VERSION "created by canmatrix"

NS_ :

BS_:

BU_: TCM iBooster HCU CIM SCM Right_Hand_Control Left_Hand_Control GPS VCM IC_2 XM GMRS Radio_CANtool Diagnostic_Tool_Digital_Wrench Information_System_Controller_1 STEERING_CONTROLLER VEHICLE_SECURITY RADIO_Hub ABS Battery_Management_Cntrl_2 Battery_Management_Cntrl_1 Auxiliary_Power_Unit_2 Auxiliary_Power_Unit_1 Electric_Propulsion_Cntrl_Unit_4 Electric_Propulsion_Cntrl_Unit_3 Electric_Propulsion_Cntrl_Unit_2 Electric_Propulsion_Cntrl_Unit_1 ECM IC

BO_ 2566740990 DM45: 22 Vector__XXX
 SG_ FlashRedStopLamp : 12|2@1+ (1,0) [0.0|3.0] "" Vector__XXX
 SG_ FlashProtectLamp : 8|2@1+ (1,0) [0.0|3.0] "" Vector__XXX
 SG_ FlashMalfuncIndicatorLamp : 14|2@1+ (1,0) [0.0|3.0] "" Vector__XXX
 SG_ FlashAmberWarningLamp : 10|2@1+ (1,0) [0.0|3.0] "" Vector__XXX
 SG_ MalfunctionIndicatorLampStatus : 6|2@1+ (1,0) [0.0|3.0] "" Vector__XXX
 SG_ AmberWarningLampStatus : 2|2@1+ (1,0) [0.0|3.0] "" Vector__XXX
 SG_ RedStopLampState : 4|2@1+ (1,0) [0.0|3.0] "" Vector__XXX
 SG_ ProtectLampStatus : 0|2@1+ (1,0) [0.0|3.0] "" Vector__XXX
 SG_ DTC5 : 144|32@1+ (1,0) [0.0|4294967295.0] "" Vector__XXX
 SG_ DTC4 : 112|32@1+ (1,0) [0.0|4294967295.0] "" Vector__XXX
 SG_ DTC3 : 80|32@1+ (1,0) [0.0|4294967295.0] "" Vector__XXX
 SG_ DTC2 : 48|32@1+ (1,0) [0.0|4294967295.0] "" Vector__XXX
 SG_ DTC1 : 16|32@1+ (1,0) [0.0|4294967295.0] "" Vector__XXX

BO_ 2566741246 DM44: 22 Vector__XXX
 SG_ FlashRedStopLamp : 12|2@1+ (1,0) [0.0|3.0] "" Vector__XXX
 SG_ FlashProtectLamp : 8|2@1+ (1,0) [0.0|3.0] "" Vector__XXX
 SG_ FlashMalfuncIndicatorLamp : 14|2@1+ (1,0) [0.0|3.0] "" Vector__XXX
 SG_ FlashAmberWarningLamp : 10|2@1+ (1,0) [0.0|3.0] "" Vector__XXX
 SG_ MalfunctionIndicatorLampStatus : 6|2@1+ (1,0) [0.0|3.0] "" Vector__XXX
 SG_ AmberWarningLampStatus : 2|2@1+ (1,0) [0.0|3.0] "" Vector__XXX
 SG_ RedStopLampState : 4|2@1+ (1,0) [0.0|3.0] "" Vector__XXX
 SG_ ProtectLampStatus : 0|2@1+ (1,0) [0.0|3.0] "" Vector__XXX
 SG_ DTC5 : 144|32@1+ (1,0) [0.0|4294967295.0] "" Vector__XXX
 SG_ DTC4 : 112|32@1+ (1,0) [0.0|4294967295.0] "" Vector__XXX
 SG_ DTC3 : 80|32@1+ (1,0) [0.0|4294967295.0] "" Vector__XXX
 SG_ DTC2 : 48|32@1+ (1,0) [0.0|4294967295.0] "" Vector__XXX
 SG_ DTC1 : 16|32@1+ (1,0) [0.0|4294967295.0] "" Vector__XXX

BO_ 2566741502 DM43: 22 Vector__XXX
 SG_ FlashRedStopLamp : 12|2@1+ (1,0) [0.0|3.0] "" Vector__XXX
 SG_ FlashProtectLamp : 8|2@1+ (1,0) [0.0|3.0] "" Vector__XXX
 SG_ FlashMalfuncIndicatorLamp : 14|2@1+ (1,0) [0.0|3.0] "" Vector__XXX
 SG_ FlashAmberWarningLamp : 10|2@1+ (1,0) [0.0|3.0] "" Vector__XXX
 SG_ MalfunctionIndicatorLampStatus : 6|2@1+ (1,0) [0.0|3.0] "" Vector__XXX
 SG_ AmberWarningLampStatus : 2|2@1+ (1,0) [0.0|3.0] "" Vector__XXX
 SG_ RedStopLampState : 4|2@1+ (1,0) [0.0|3.0] "" Vector__XXX
 SG_ ProtectLampStatus : 0|2@1+ (1,0) [0.0|3.0] "" Vector__XXX
 SG_ DTC5 : 144|32@1+ (1,0) [0.0|4294967295.0] "" Vector__XXX
 SG_ DTC4 : 112|32@1+ (1,0) [0.0|4294967295.0] "" Vector__XXX
 SG_ DTC3 : 80|32@1+ (1,0) [0.0|4294967295.0] "" Vector__XXX
 SG_ DTC2 : 48|32@1+ (1,0) [0.0|4294967295.0] "" Vector__XXX
 SG_ DTC1 : 16|32@1+ (1,0) [0.0|4294967295.0] "" Vector__XXX

BO_ 2566741758 DM42: 22 Vector__XXX
 SG_ FlashRedStopLamp : 12|2@1+ (1,0) [0.0|3.0] "" Vector__XXX
 SG_ FlashProtectLamp : 8|2@1+ (1,0) [0.0|3.0] "" Vector__XXX
 SG_ FlashMalfuncIndicatorLamp : 14|2@1+ (1,0) [0.0|3.0] "" Vector__XXX
 SG_ FlashAmberWarningLamp : 10|2@1+ (1,0) [0.0|3.0] "" Vector__XXX
 SG_ MalfunctionIndicatorLampStatus : 6|2@1+ (1,0) [0.0|3.0] "" Vector__XXX
 SG_ AmberWarningLampStatus : 2|2@1+ (1,0) [0.0|3.0] "" Vector__XXX
 SG_ RedStopLampState : 4|2@1+ (1,0) [0.0|3.0] "" Vector__XXX
 SG_ ProtectLampStatus : 0|2@1+ (1,0) [0.0|3.0] "" Vector__XXX
 SG_ DTC5 : 144|32@1+ (1,0) [0.0|4294967295.0] "" Vector__XXX
 SG_ DTC4 : 112|32@1+ (1,0) [0.0|4294967295.0] "" Vector__XXX
 SG_ DTC3 : 80|32@1+ (1,0) [0.0|4294967295.0] "" Vector__XXX
 SG_ DTC2 : 48|32@1+ (1,0) [0.0|4294967295.0] "" Vector__XXX
 SG_ DTC1 : 16|32@1+ (1,0) [0.0|4294967295.0] "" Vector__XXX

BO_ 2566742014 DM41: 22 Vector__XXX
 SG_ FlashRedStopLamp : 12|2@1+ (1,0) [0.0|3.0] "" Vector__XXX
 SG_ FlashProtectLamp : 8|2@1+ (1,0) [0.0|3.0] "" Vector__XXX
 SG_ FlashMalfuncIndicatorLamp : 14|2@1+ (1,0) [0.0|3.0] "" Vector__XXX
 SG_ FlashAmberWarningLamp : 10|2@1+ (1,0) [0.0|3.0] "" Vector__XXX
 SG_ MalfunctionIndicatorLampStatus : 6|2@1+ (1,0) [0.0|3.0] "" Vector__XXX
 SG_ AmberWarningLampStatus : 2|2@1+ (1,0) [0.0|3.0] "" Vector__XXX
 SG_ RedStopLampState : 4|2@1+ (1,0) [0.0|3.0] "" Vector__XXX
 SG_ ProtectLampStatus : 0|2@1+ (1,0) [0.0|3.0] "" Vector__XXX
 SG_ DTC5 : 144|32@1+ (1,0) [0.0|4294967295.0] "" Vector__XXX
 SG_ DTC4 : 112|32@1+ (1,0) [0.0|4294967295.0] "" Vector__XXX
 SG_ DTC3 : 80|32@1+ (1,0) [0.0|4294967295.0] "" Vector__XXX
 SG_ DTC2 : 48|32@1+ (1,0) [0.0|4294967295.0] "" Vector__XXX
 SG_ DTC1 : 16|32@1+ (1,0) [0.0|4294967295.0] "" Vector__XXX

BO_ 2560622334 DM35_40704: 22 Vector__XXX
 SG_ FlashRedStopLamp_3039 : 12|2@1+ (1,0) [0.0|3.0] "" Vector__XXX
 SG_ FlashProtectLamp_3041 : 8|2@1+ (1,0) [0.0|3.0] "" Vector__XXX
 SG_ FlashMalfuncIndicatorLamp_3038 : 14|2@1+ (1,0) [0.0|3.0] "" Vector__XXX
 SG_ FlashAmberWarningLamp_3040 : 10|2@1+ (1,0) [0.0|3.0] "" Vector__XXX
 SG_ MILStatus_1213 : 6|2@1+ (1,0) [0.0|3.0] "" Vector__XXX
 SG_ AmberWarningLampStatus_624 : 2|2@1+ (1,0) [0.0|3.0] "" Vector__XXX
 SG_ RedStopLampState_623 : 4|2@1+ (1,0) [0.0|3.0] "" Vector__XXX
 SG_ ProtectLampStatus_987 : 0|2@1+ (1,0) [0.0|3.0] "" Vector__XXX
 SG_ DTC5 : 144|32@1+ (1,0) [0.0|4294967295.0] "" Vector__XXX
 SG_ DTC4 : 112|32@1+ (1,0) [0.0|4294967295.0] "" Vector__XXX
 SG_ DTC3 : 80|32@1+ (1,0) [0.0|4294967295.0] "" Vector__XXX
 SG_ DTC2 : 48|32@1+ (1,0) [0.0|4294967295.0] "" Vector__XXX
 SG_ DTC1 : 16|32@1+ (1,0) [0.0|4294967295.0] "" Vector__XXX

BO_ 2566744062 ZNVW: 8 Vector__XXX
 SG_ ZeroNetVehicleWeightChange : 0|2@1+ (1,0) [0.0|3.0] "" Vector__XXX

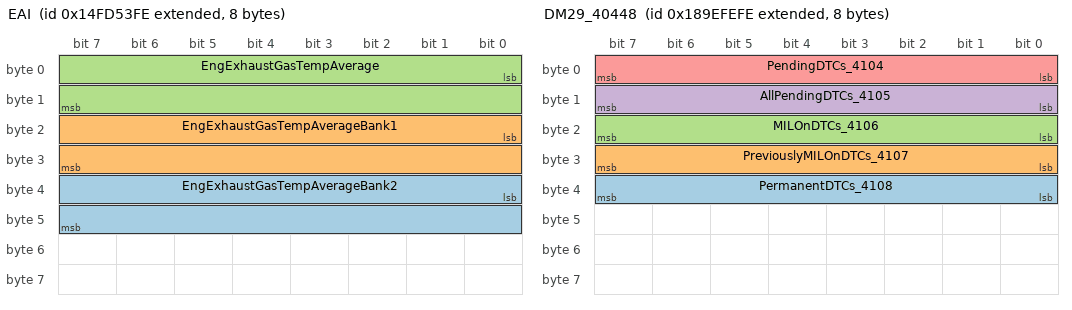
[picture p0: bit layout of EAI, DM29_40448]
BO_ 2499630078 EAI: 8 Vector__XXX
 SG_ EngExhaustGasTempAverageBank2 : 32|16@1+ (0.03125,-273) [-273.0|1734.96875] "°C" Vector__XXX
 SG_ EngExhaustGasTempAverageBank1 : 16|16@1+ (0.03125,-273) [-273.0|1734.96875] "°C" Vector__XXX
 SG_ EngExhaustGasTempAverage : 0|16@1+ (0.03125,-273) [-273.0|1734.96875] "°C" Vector__XXX

BO_ 2560556798 DM29_40448: 8 Vector__XXX
 SG_ PermanentDTCs_4108 : 32|8@1+ (1,0) [0.0|255.0] "" Vector__XXX
 SG_ PreviouslyMILOnDTCs_4107 : 24|8@1+ (1,0) [0.0|255.0] "" Vector__XXX
 SG_ MILOnDTCs_4106 : 16|8@1+ (1,0) [0.0|255.0] "" Vector__XXX
 SG_ AllPendingDTCs_4105 : 8|8@1+ (1,0) [0.0|255.0] "" Vector__XXX
 SG_ PendingDTCs_4104 : 0|8@1+ (1,0) [0.0|255.0] "" Vector__XXX

BO_ 2566750462 DM28: 22 Vector__XXX
 SG_ FlashRedStopLamp : 12|2@1+ (1,0) [0.0|3.0] "" Vector__XXX
 SG_ FlashProtectLamp : 8|2@1+ (1,0) [0.0|3.0] "" Vector__XXX
 SG_ FlashMalfuncIndicatorLamp : 14|2@1+ (1,0) [0.0|3.0] "" Vector__XXX
 SG_ FlashAmberWarningLamp : 10|2@1+ (1,0) [0.0|3.0] "" Vector__XXX
 SG_ MalfunctionIndicatorLampStatus : 6|2@1+ (1,0) [0.0|3.0] "" Vector__XXX
 SG_ AmberWarningLampStatus : 2|2@1+ (1,0) [0.0|3.0] "" Vector__XXX
 SG_ RedStopLampState : 4|2@1+ (1,0) [0.0|3.0] "" Vector__XXX
 SG_ ProtectLampStatus : 0|2@1+ (1,0) [0.0|3.0] "" Vector__XXX
 SG_ DTC5 : 144|32@1+ (1,0) [0.0|4294967295.0] "" Vector__XXX
 SG_ DTC4 : 112|32@1+ (1,0) [0.0|4294967295.0] "" Vector__XXX
 SG_ DTC3 : 80|32@1+ (1,0) [0.0|4294967295.0] "" Vector__XXX
 SG_ DTC2 : 48|32@1+ (1,0) [0.0|4294967295.0] "" Vector__XXX
 SG_ DTC1 : 16|32@1+ (1,0) [0.0|4294967295.0] "" Vector__XXX

BO_ 2566750974 DM27: 22 Vector__XXX
 SG_ FlashRedStopLamp : 12|2@1+ (1,0) [0.0|3.0] "" Vector__XXX
 SG_ FlashProtectLamp : 8|2@1+ (1,0) [0.0|3.0] "" Vector__XXX
 SG_ FlashMalfuncIndicatorLamp : 14|2@1+ (1,0) [0.0|3.0] "" Vector__XXX
 SG_ FlashAmberWarningLamp : 10|2@1+ (1,0) [0.0|3.0] "" Vector__XXX
 SG_ MalfunctionIndicatorLampStatus : 6|2@1+ (1,0) [0.0|3.0] "" Vector__XXX
 SG_ AmberWarningLampStatus : 2|2@1+ (1,0) [0.0|3.0] "" Vector__XXX
 SG_ RedStopLampState : 4|2@1+ (1,0) [0.0|3.0] "" Vector__XXX
 SG_ ProtectLampStatus : 0|2@1+ (1,0) [0.0|3.0] "" Vector__XXX
 SG_ DTC5 : 144|32@1+ (1,0) [0.0|4294967295.0] "" Vector__XXX
 SG_ DTC4 : 112|32@1+ (1,0) [0.0|4294967295.0] "" Vector__XXX
 SG_ DTC3 : 80|32@1+ (1,0) [0.0|4294967295.0] "" Vector__XXX
 SG_ DTC2 : 48|32@1+ (1,0) [0.0|4294967295.0] "" Vector__XXX
 SG_ DTC1 : 16|32@1+ (1,0) [0.0|4294967295.0] "" Vector__XXX

BO_ 2566754558 AETC: 61 Vector__XXX
 SG_ AETCTorqueValue14 : 472|16@1+ (1,0) [0.0|65535.0] "Nm" Vector__XXX
 SG_ AETCTorqueValue13 : 440|16@1+ (1,0) [0.0|65535.0] "Nm" Vector__XXX
 SG_ AETCTorqueValue12 : 408|16@1+ (1,0) [0.0|65535.0] "Nm" Vector__XXX
 SG_ AETCTorqueValue11 : 376|16@1+ (1,0) [0.0|65535.0] "Nm" Vector__XXX
 SG_ AETCTorqueValue10 : 344|16@1+ (1,0) [0.0|65535.0] "Nm" Vector__XXX
 SG_ AETCTorqueValue09 : 312|16@1+ (1,0) [0.0|65535.0] "Nm" Vector__XXX
 SG_ AETCTorqueValue08 : 280|16@1+ (1,0) [0.0|65535.0] "Nm" Vector__XXX
 SG_ AETCTorqueValue07 : 248|16@1+ (1,0) [0.0|65535.0] "Nm" Vector__XXX
 SG_ AETCTorqueValue06 : 216|16@1+ (1,0) [0.0|65535.0] "Nm" Vector__XXX
 SG_ AETCTorqueValue05 : 184|16@1+ (1,0) [0.0|65535.0] "Nm" Vector__XXX
 SG_ AETCTorqueValue04 : 152|16@1+ (1,0) [0.0|65535.0] "Nm" Vector__XXX
 SG_ AETCTorqueValue03 : 120|16@1+ (1,0) [0.0|65535.0] "Nm" Vector__XXX
 SG_ AETCTorqueValue02 : 88|16@1+ (1,0) [0.0|65535.0] "Nm" Vector__XXX
 SG_ AETCTorqueValue01 : 56|16@1+ (1,0) [0.0|65535.0] "Nm" Vector__XXX
 SG_ AETCSpeedValue14 : 456|16@1+ (0.125,0) [0.0|8191.875] "rpm" Vector__XXX
 SG_ AETCSpeedValue13 : 424|16@1+ (0.125,0) [0.0|8191.875] "rpm" Vector__XXX
 SG_ AETCSpeedValue12 : 392|16@1+ (0.125,0) [0.0|8191.875] "rpm" Vector__XXX
 SG_ AETCSpeedValue11 : 360|16@1+ (0.125,0) [0.0|8191.875] "rpm" Vector__XXX
 SG_ AETCSpeedValue10 : 328|16@1+ (0.125,0) [0.0|8191.875] "rpm" Vector__XXX
 SG_ AETCSpeedValue09 : 296|16@1+ (0.125,0) [0.0|8191.875] "rpm" Vector__XXX
 SG_ AETCSpeedValue08 : 264|16@1+ (0.125,0) [0.0|8191.875] "rpm" Vector__XXX
 SG_ AETCSpeedValue07 : 232|16@1+ (0.125,0) [0.0|8191.875] "rpm" Vector__XXX
 SG_ AETCSpeedValue06 : 200|16@1+ (0.125,0) [0.0|8191.875] "rpm" Vector__XXX
 SG_ AETCSpeedValue05 : 168|16@1+ (0.125,0) [0.0|8191.875] "rpm" Vector__XXX
 SG_ AETCSpeedValue04 : 136|16@1+ (0.125,0) [0.0|8191.875] "rpm" Vector__XXX
 SG_ AETCSpeedValue03 : 104|16@1+ (0.125,0) [0.0|8191.875] "rpm" Vector__XXX
 SG_ AETCSpeedValue02 : 72|16@1+ (0.125,0) [0.0|8191.875] "rpm" Vector__XXX
 SG_ AETCSpeedValue01 : 40|16@1+ (0.125,0) [0.0|8191.875] "rpm" Vector__XXX
 SG_ AETCTorqueValue00 : 24|16@1+ (1,0) [0.0|65535.0] "Nm" Vector__XXX
 SG_ AETCSpeedValue00 : 8|16@1+ (0.125,0) [0.0|8191.875] "rpm" Vector__XXX
 SG_ NumberOfAETCDataPoints : 4|4@1+ (1,0) [5.0|15.0] "" Vector__XXX
 SG_ AETCDataCollectionStandard : 0|4@1+ (1,0) [0.0|15.0] "" Vector__XXX

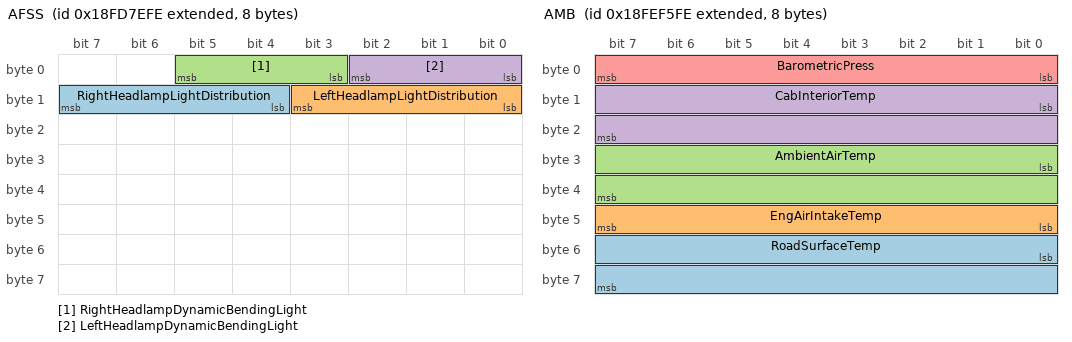
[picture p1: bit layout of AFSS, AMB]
BO_ 2566749950 AFSS: 8 Vector__XXX
 SG_ RightHeadlampLightDistribution : 12|4@1+ (1,0) [0.0|15.0] "" Vector__XXX
 SG_ LeftHeadlampLightDistribution : 8|4@1+ (1,0) [0.0|15.0] "" Vector__XXX
 SG_ RightHeadlampDynamicBendingLight : 3|3@1+ (1,0) [0.0|7.0] "" Vector__XXX
 SG_ LeftHeadlampDynamicBendingLight : 0|3@1+ (1,0) [0.0|7.0] "" Vector__XXX

BO_ 2566838782 AUXIO1: 8 Vector__XXX
 SG_ AuxI_OChannel2 : 48|16@1+ (1,0) [0.0|64255.0] "" Vector__XXX
 SG_ AuxI_OChannel1 : 32|16@1+ (1,0) [0.0|64255.0] "" Vector__XXX
 SG_ AuxI_O13 : 30|2@1+ (1,0) [0.0|3.0] "" Vector__XXX
 SG_ AuxI_O14 : 28|2@1+ (1,0) [0.0|3.0] "" Vector__XXX
 SG_ AuxI_O15 : 26|2@1+ (1,0) [0.0|3.0] "" Vector__XXX
 SG_ AuxI_O16 : 24|2@1+ (1,0) [0.0|3.0] "" Vector__XXX
 SG_ AuxI_O09 : 22|2@1+ (1,0) [0.0|3.0] "" Vector__XXX
 SG_ AuxI_O10 : 20|2@1+ (1,0) [0.0|3.0] "" Vector__XXX
 SG_ AuxI_O11 : 18|2@1+ (1,0) [0.0|3.0] "" Vector__XXX
 SG_ AuxI_O12 : 16|2@1+ (1,0) [0.0|3.0] "" Vector__XXX
 SG_ AuxI_O05 : 14|2@1+ (1,0) [0.0|3.0] "" Vector__XXX
 SG_ AuxI_O06 : 12|2@1+ (1,0) [0.0|3.0] "" Vector__XXX
 SG_ AuxI_O07 : 10|2@1+ (1,0) [0.0|3.0] "" Vector__XXX
 SG_ AuxI_O08 : 8|2@1+ (1,0) [0.0|3.0] "" Vector__XXX
 SG_ AuxI_O01 : 6|2@1+ (1,0) [0.0|3.0] "" Vector__XXX
 SG_ AuxI_O02 : 4|2@1+ (1,0) [0.0|3.0] "" Vector__XXX
 SG_ AuxI_O03 : 2|2@1+ (1,0) [0.0|3.0] "" Vector__XXX
 SG_ AuxI_O04 : 0|2@1+ (1,0) [0.0|3.0] "" Vector__XXX

BO_ 2561146622 AUXIO2_42752: 8 Vector__XXX
 SG_ AuxI_O45_3868 : 62|2@1+ (1,0) [0.0|3.0] "" Vector__XXX
 SG_ AuxI_O46_3869 : 60|2@1+ (1,0) [0.0|3.0] "" Vector__XXX
 SG_ AuxI_O47_3870 : 58|2@1+ (1,0) [0.0|3.0] "" Vector__XXX
 SG_ AuxI_O48_3871 : 56|2@1+ (1,0) [0.0|3.0] "" Vector__XXX
 SG_ AuxI_O41_3864 : 54|2@1+ (1,0) [0.0|3.0] "" Vector__XXX
 SG_ AuxI_O42_3865 : 52|2@1+ (1,0) [0.0|3.0] "" Vector__XXX
 SG_ AuxI_O43_3866 : 50|2@1+ (1,0) [0.0|3.0] "" Vector__XXX
 SG_ AuxI_O44_3867 : 48|2@1+ (1,0) [0.0|3.0] "" Vector__XXX
 SG_ AuxI_O37_3860 : 46|2@1+ (1,0) [0.0|3.0] "" Vector__XXX
 SG_ AuxI_O38_3861 : 44|2@1+ (1,0) [0.0|3.0] "" Vector__XXX
 SG_ AuxI_O39_3862 : 42|2@1+ (1,0) [0.0|3.0] "" Vector__XXX
 SG_ AuxI_O40_3863 : 40|2@1+ (1,0) [0.0|3.0] "" Vector__XXX
 SG_ AuxI_O33_3856 : 38|2@1+ (1,0) [0.0|3.0] "" Vector__XXX
 SG_ AuxI_O34_3857 : 36|2@1+ (1,0) [0.0|3.0] "" Vector__XXX
 SG_ AuxI_O35_3858 : 34|2@1+ (1,0) [0.0|3.0] "" Vector__XXX
 SG_ AuxI_O36_3859 : 32|2@1+ (1,0) [0.0|3.0] "" Vector__XXX
 SG_ AuxI_O29_3852 : 30|2@1+ (1,0) [0.0|3.0] "" Vector__XXX
 SG_ AuxI_O30_3853 : 28|2@1+ (1,0) [0.0|3.0] "" Vector__XXX
 SG_ AuxI_O31_3854 : 26|2@1+ (1,0) [0.0|3.0] "" Vector__XXX
 SG_ AuxI_O32_3855 : 24|2@1+ (1,0) [0.0|3.0] "" Vector__XXX
 SG_ AuxI_O25_3848 : 22|2@1+ (1,0) [0.0|3.0] "" Vector__XXX
 SG_ AuxI_O26_3849 : 20|2@1+ (1,0) [0.0|3.0] "" Vector__XXX
 SG_ AuxI_O27_3850 : 18|2@1+ (1,0) [0.0|3.0] "" Vector__XXX
 SG_ AuxI_O28_3851 : 16|2@1+ (1,0) [0.0|3.0] "" Vector__XXX
 SG_ AuxI_O21_3844 : 14|2@1+ (1,0) [0.0|3.0] "" Vector__XXX
 SG_ AuxI_O22_3845 : 12|2@1+ (1,0) [0.0|3.0] "" Vector__XXX
 SG_ AuxI_O23_3846 : 10|2@1+ (1,0) [0.0|3.0] "" Vector__XXX
 SG_ AuxI_O24_3847 : 8|2@1+ (1,0) [0.0|3.0] "" Vector__XXX
 SG_ AuxI_O17_3840 : 6|2@1+ (1,0) [0.0|3.0] "" Vector__XXX
 SG_ AuxI_O18_3841 : 4|2@1+ (1,0) [0.0|3.0] "" Vector__XXX
 SG_ AuxI_O19_3842 : 2|2@1+ (1,0) [0.0|3.0] "" Vector__XXX
 SG_ AuxI_O20_3843 : 0|2@1+ (1,0) [0.0|3.0] "" Vector__XXX

BO_ 2561081086 AUXIO3_42496: 8 Vector__XXX
 SG_ AuxI_O77_3900 : 62|2@1+ (1,0) [0.0|3.0] "" Vector__XXX
 SG_ AuxI_O78_3901 : 60|2@1+ (1,0) [0.0|3.0] "" Vector__XXX
 SG_ AuxI_O79_3902 : 58|2@1+ (1,0) [0.0|3.0] "" Vector__XXX
 SG_ AuxI_O80_3903 : 56|2@1+ (1,0) [0.0|3.0] "" Vector__XXX
 SG_ AuxI_O73_3896 : 54|2@1+ (1,0) [0.0|3.0] "" Vector__XXX
 SG_ AuxI_O74_3897 : 52|2@1+ (1,0) [0.0|3.0] "" Vector__XXX
 SG_ AuxI_O75_3898 : 50|2@1+ (1,0) [0.0|3.0] "" Vector__XXX
 SG_ AuxI_O76_3899 : 48|2@1+ (1,0) [0.0|3.0] "" Vector__XXX
 SG_ AuxI_O69_3892 : 46|2@1+ (1,0) [0.0|3.0] "" Vector__XXX
 SG_ AuxI_O70_3893 : 44|2@1+ (1,0) [0.0|3.0] "" Vector__XXX
 SG_ AuxI_O71_3894 : 42|2@1+ (1,0) [0.0|3.0] "" Vector__XXX
 SG_ AuxI_O72_3895 : 40|2@1+ (1,0) [0.0|3.0] "" Vector__XXX
 SG_ AuxI_O65_3888 : 38|2@1+ (1,0) [0.0|3.0] "" Vector__XXX
 SG_ AuxI_O66_3889 : 36|2@1+ (1,0) [0.0|3.0] "" Vector__XXX
 SG_ AuxI_O67_3890 : 34|2@1+ (1,0) [0.0|3.0] "" Vector__XXX
 SG_ AuxI_O68_3891 : 32|2@1+ (1,0) [0.0|3.0] "" Vector__XXX
 SG_ AuxI_O61_3884 : 30|2@1+ (1,0) [0.0|3.0] "" Vector__XXX
 SG_ AuxI_O62_3885 : 28|2@1+ (1,0) [0.0|3.0] "" Vector__XXX
 SG_ AuxI_O63_3886 : 26|2@1+ (1,0) [0.0|3.0] "" Vector__XXX
 SG_ AuxI_O64_3887 : 24|2@1+ (1,0) [0.0|3.0] "" Vector__XXX
 SG_ AuxI_O57_3880 : 22|2@1+ (1,0) [0.0|3.0] "" Vector__XXX
 SG_ AuxI_O58_3881 : 20|2@1+ (1,0) [0.0|3.0] "" Vector__XXX
 SG_ AuxI_O59_3882 : 18|2@1+ (1,0) [0.0|3.0] "" Vector__XXX
 SG_ AuxI_O60_3883 : 16|2@1+ (1,0) [0.0|3.0] "" Vector__XXX
 SG_ AuxI_O53_3876 : 14|2@1+ (1,0) [0.0|3.0] "" Vector__XXX
 SG_ AuxI_O54_3877 : 12|2@1+ (1,0) [0.0|3.0] "" Vector__XXX
 SG_ AuxI_O55_3878 : 10|2@1+ (1,0) [0.0|3.0] "" Vector__XXX
 SG_ AuxI_O56_3879 : 8|2@1+ (1,0) [0.0|3.0] "" Vector__XXX
 SG_ AuxI_O49_3872 : 6|2@1+ (1,0) [0.0|3.0] "" Vector__XXX
 SG_ AuxI_O50_3873 : 4|2@1+ (1,0) [0.0|3.0] "" Vector__XXX
 SG_ AuxI_O51_3874 : 2|2@1+ (1,0) [0.0|3.0] "" Vector__XXX
 SG_ AuxI_O52_3875 : 0|2@1+ (1,0) [0.0|3.0] "" Vector__XXX

BO_ 2561015550 AUXIO4_42240: 8 Vector__XXX
 SG_ AuxI_O109_3932 : 62|2@1+ (1,0) [0.0|3.0] "" Vector__XXX
 SG_ AuxI_O110_3933 : 60|2@1+ (1,0) [0.0|3.0] "" Vector__XXX
 SG_ AuxI_O111_3934 : 58|2@1+ (1,0) [0.0|3.0] "" Vector__XXX
 SG_ AuxI_O112_3935 : 56|2@1+ (1,0) [0.0|3.0] "" Vector__XXX
 SG_ AuxI_O105_3928 : 54|2@1+ (1,0) [0.0|3.0] "" Vector__XXX
 SG_ AuxI_O106_3929 : 52|2@1+ (1,0) [0.0|3.0] "" Vector__XXX
 SG_ AuxI_O107_3930 : 50|2@1+ (1,0) [0.0|3.0] "" Vector__XXX
 SG_ AuxI_O108_3931 : 48|2@1+ (1,0) [0.0|3.0] "" Vector__XXX
 SG_ AuxI_O101_3924 : 46|2@1+ (1,0) [0.0|3.0] "" Vector__XXX
 SG_ AuxI_O102_3925 : 44|2@1+ (1,0) [0.0|3.0] "" Vector__XXX
 SG_ AuxI_O103_3926 : 42|2@1+ (1,0) [0.0|3.0] "" Vector__XXX
 SG_ AuxI_O104_3927 : 40|2@1+ (1,0) [0.0|3.0] "" Vector__XXX
 SG_ AuxI_O97_3920 : 38|2@1+ (1,0) [0.0|3.0] "" Vector__XXX
 SG_ AuxI_O98_3921 : 36|2@1+ (1,0) [0.0|3.0] "" Vector__XXX
 SG_ AuxI_O99_3922 : 34|2@1+ (1,0) [0.0|3.0] "" Vector__XXX
 SG_ AuxI_O100_3923 : 32|2@1+ (1,0) [0.0|3.0] "" Vector__XXX
 SG_ AuxI_O93_3916 : 30|2@1+ (1,0) [0.0|3.0] "" Vector__XXX
 SG_ AuxI_O94_3917 : 28|2@1+ (1,0) [0.0|3.0] "" Vector__XXX
 SG_ AuxI_O95_3918 : 26|2@1+ (1,0) [0.0|3.0] "" Vector__XXX
 SG_ AuxI_O96_3919 : 24|2@1+ (1,0) [0.0|3.0] "" Vector__XXX
 SG_ AuxI_O89_3912 : 22|2@1+ (1,0) [0.0|3.0] "" Vector__XXX
 SG_ AuxI_O90_3913 : 20|2@1+ (1,0) [0.0|3.0] "" Vector__XXX
 SG_ AuxI_O91_3914 : 18|2@1+ (1,0) [0.0|3.0] "" Vector__XXX
 SG_ AuxI_O92_3915 : 16|2@1+ (1,0) [0.0|3.0] "" Vector__XXX
 SG_ AuxI_O85_3908 : 14|2@1+ (1,0) [0.0|3.0] "" Vector__XXX
 SG_ AuxI_O86_3909 : 12|2@1+ (1,0) [0.0|3.0] "" Vector__XXX
 SG_ AuxI_O87_3910 : 10|2@1+ (1,0) [0.0|3.0] "" Vector__XXX
 SG_ AuxI_O88_3911 : 8|2@1+ (1,0) [0.0|3.0] "" Vector__XXX
 SG_ AuxI_O81_3904 : 6|2@1+ (1,0) [0.0|3.0] "" Vector__XXX
 SG_ AuxI_O82_3905 : 4|2@1+ (1,0) [0.0|3.0] "" Vector__XXX
 SG_ AuxI_O83_3906 : 2|2@1+ (1,0) [0.0|3.0] "" Vector__XXX
 SG_ AuxI_O84_3907 : 0|2@1+ (1,0) [0.0|3.0] "" Vector__XXX

BO_ 2566746622 BSA: 8 Vector__XXX
 SG_ TrailerBrakeStrokeAxle5Right : 57|3@1+ (1,0) [0.0|7.0] "" Vector__XXX
 SG_ TrailerBrakeStrokeAxle5Left : 54|3@1+ (1,0) [0.0|7.0] "" Vector__XXX
 SG_ TrailerBrakeStrokeAxle4Right : 51|3@1+ (1,0) [0.0|7.0] "" Vector__XXX
 SG_ TrailerBrakeStrokeAxle4Left : 48|3@1+ (1,0) [0.0|7.0] "" Vector__XXX
 SG_ TrailerBrakeStrokeAxle3Right : 45|3@1+ (1,0) [0.0|7.0] "" Vector__XXX
 SG_ TrailerBrakeStrokeAxle3Left : 42|3@1+ (1,0) [0.0|7.0] "" Vector__XXX
 SG_ TrailerBrakeStrokeAxle2Right : 39|3@1+ (1,0) [0.0|7.0] "" Vector__XXX
 SG_ TrailerBrakeStrokeAxle2Left : 36|3@1+ (1,0) [0.0|7.0] "" Vector__XXX
 SG_ TrailerBrakeStrokeAxle1Right : 33|3@1+ (1,0) [0.0|7.0] "" Vector__XXX
 SG_ TrailerBrakeStrokeAxle1Left : 30|3@1+ (1,0) [0.0|7.0] "" Vector__XXX
 SG_ TractorBrakeStrokeAxle5Right : 27|3@1+ (1,0) [0.0|7.0] "" Vector__XXX
 SG_ TractorBrakeStrokeAxle5Left : 24|3@1+ (1,0) [0.0|7.0] "" Vector__XXX
 SG_ TractorBrakeStrokeAxle4Right : 21|3@1+ (1,0) [0.0|7.0] "" Vector__XXX
 SG_ TractorBrakeStrokeAxle4Left : 18|3@1+ (1,0) [0.0|7.0] "" Vector__XXX
 SG_ TractorBrakeStrokeAxle3Right : 15|3@1+ (1,0) [0.0|7.0] "" Vector__XXX
 SG_ TractorBrakeStrokeAxle3Left : 12|3@1+ (1,0) [0.0|7.0] "" Vector__XXX
 SG_ TractorBrakeStrokeAxle2Right : 9|3@1+ (1,0) [0.0|7.0] "" Vector__XXX
 SG_ TractorBrakeStrokeAxle2Left : 6|3@1+ (1,0) [0.0|7.0] "" Vector__XXX
 SG_ TractorBrakeStrokeAxle1Right : 3|3@1+ (1,0) [0.0|7.0] "" Vector__XXX
 SG_ TractorBrakeStrokeAxle1Left : 0|3@1+ (1,0) [0.0|7.0] "" Vector__XXX

BO_ 2566845950 AMB: 8 Vector__XXX
 SG_ RoadSurfaceTemp : 48|16@1+ (0.03125,-273) [-273.0|1734.96875] "°C" Vector__XXX
 SG_ EngAirIntakeTemp : 40|8@1+ (1,-40) [-40.0|210.0] "°C" Vector__XXX
 SG_ AmbientAirTemp : 24|16@1+ (0.03125,-273) [-273.0|1734.96875] "°C" Vector__XXX
 SG_ CabInteriorTemp : 8|16@1+ (0.03125,-273) [-273.0|1734.96875] "°C" Vector__XXX
 SG_ BarometricPress : 0|8@1+ (0.5,0) [0.0|125.0] "kPa" Vector__XXX

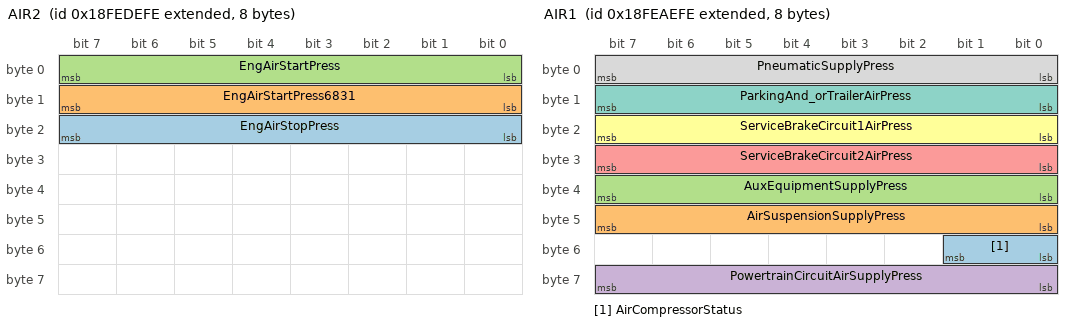
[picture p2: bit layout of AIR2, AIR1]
BO_ 2566840062 AIR2: 8 Vector__XXX
 SG_ EngAirStopPress : 16|8@1+ (4,0) [0.0|1000.0] "kPa" Vector__XXX
 SG_ EngAirStartPress6831 : 8|8@1+ (16,0) [0.0|4000.0] "kPa" Vector__XXX
 SG_ EngAirStartPress : 0|8@1+ (4,0) [0.0|1000.0] "kPa" Vector__XXX

BO_ 2566827774 AIR1: 8 Vector__XXX
 SG_ AirCompressorStatus : 48|2@1+ (1,0) [0.0|3.0] "" Vector__XXX
 SG_ AirSuspensionSupplyPress : 40|8@1+ (8,0) [0.0|2000.0] "kPa" Vector__XXX
 SG_ AuxEquipmentSupplyPress : 32|8@1+ (8,0) [0.0|2000.0] "kPa" Vector__XXX
 SG_ PowertrainCircuitAirSupplyPress : 56|8@1+ (8,0) [0.0|2000.0] "kPa" Vector__XXX
 SG_ ServiceBrakeCircuit2AirPress : 24|8@1+ (8,0) [0.0|2000.0] "kPa" Vector__XXX
 SG_ ServiceBrakeCircuit1AirPress : 16|8@1+ (8,0) [0.0|2000.0] "kPa" Vector__XXX
 SG_ ParkingAnd_orTrailerAirPress : 8|8@1+ (8,0) [0.0|2000.0] "kPa" Vector__XXX
 SG_ PneumaticSupplyPress : 0|8@1+ (8,0) [0.0|2000.0] "kPa" Vector__XXX

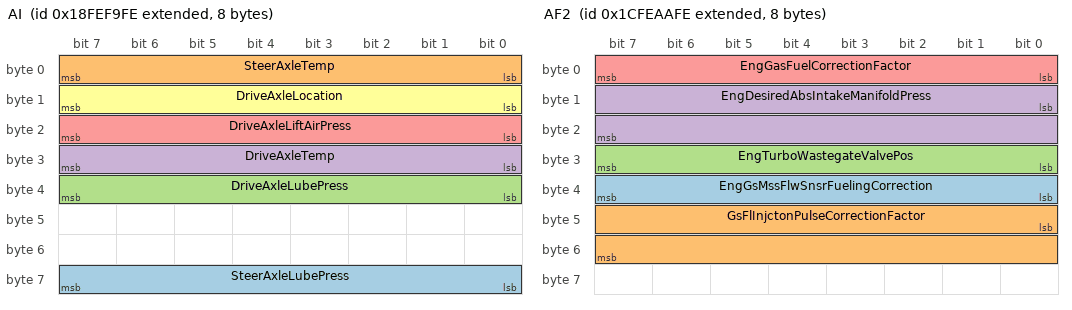
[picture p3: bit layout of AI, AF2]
BO_ 2566846974 AI: 8 Vector__XXX
 SG_ SteerAxleLubePress : 56|8@1+ (4,0) [0.0|1000.0] "kPa" Vector__XXX
 SG_ SteerAxleTemp : 0|8@1+ (1,-40) [-40.0|210.0] "°C" Vector__XXX
 SG_ DriveAxleLubePress : 32|8@1+ (4,0) [0.0|1000.0] "kPa" Vector__XXX
 SG_ DriveAxleTemp : 24|8@1+ (1,-40) [-40.0|210.0] "°C" Vector__XXX
 SG_ DriveAxleLiftAirPress : 16|8@1+ (4,0) [0.0|1000.0] "kPa" Vector__XXX
 SG_ DriveAxleLocation : 8|8@1+ (1,0) [0.0|255.0] "" Vector__XXX

BO_ 2633935614 AF2: 8 Vector__XXX
 SG_ EngGsMssFlwSnsrFuelingCorrection : 32|8@1+ (1,-125) [-125.0|125.0] "%" Vector__XXX
 SG_ GsFlInjctonPulseCorrectionFactor : 40|16@1+ (0.0078125,-251) [0.0|150.0] "%" Vector__XXX
 SG_ EngTurboWastegateValvePos : 24|8@1+ (0.4,0) [0.0|100.0] "%" Vector__XXX
 SG_ EngDesiredAbsIntakeManifoldPress : 8|16@1+ (0.1,0) [0.0|6425.5] "kPa" Vector__XXX
 SG_ EngGasFuelCorrectionFactor : 0|8@1+ (1,0) [0.0|250.0] "%" Vector__XXX

BO_ 2566803966 ACC2: 8 Vector__XXX
 SG_ RequestedACCDistanceMode : 5|3@1+ (1,0) [0.0|7.0] "" Vector__XXX
 SG_ ACCUsageDemand : 0|2@1+ (1,0) [0.0|3.0] "" Vector__XXX

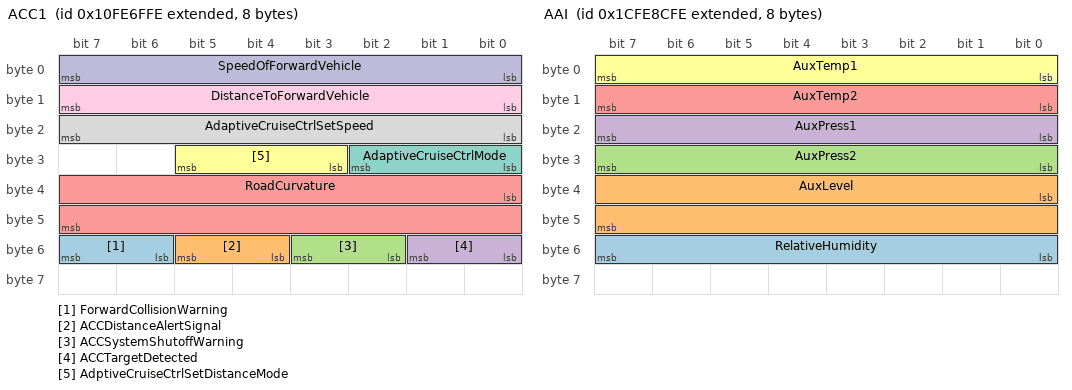
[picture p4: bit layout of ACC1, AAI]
BO_ 2432593918 ACC1: 8 Vector__XXX
 SG_ ForwardCollisionWarning : 54|2@1+ (1,0) [0.0|3.0] "" Vector__XXX
 SG_ ACCDistanceAlertSignal : 52|2@1+ (1,0) [0.0|3.0] "" Vector__XXX
 SG_ ACCSystemShutoffWarning : 50|2@1+ (1,0) [0.0|3.0] "" Vector__XXX
 SG_ ACCTargetDetected : 48|2@1+ (1,0) [0.0|3.0] "" Vector__XXX
 SG_ RoadCurvature : 32|16@1+ (0.0078125,-250) [-250.0|251.992] "1/km" Vector__XXX
 SG_ AdptiveCruiseCtrlSetDistanceMode : 27|3@1+ (1,0) [0.0|7.0] "" Vector__XXX
 SG_ AdaptiveCruiseCtrlMode : 24|3@1+ (1,0) [0.0|7.0] "" Vector__XXX
 SG_ AdaptiveCruiseCtrlSetSpeed : 16|8@1+ (1,0) [0.0|120.0] "km/h" Vector__XXX
 SG_ DistanceToForwardVehicle : 8|8@1+ (1,0) [0.0|250.0] "m" Vector__XXX
 SG_ SpeedOfForwardVehicle : 0|8@1+ (1,0) [0.0|250.0] "km/h" Vector__XXX

BO_ 2633935102 ACTL: 8 Vector__XXX
 SG_ ArticulationAngle : 0|8@1+ (1,-125) [-125.0|125.0] "deg" Vector__XXX

BO_ 2633927934 AAI: 8 Vector__XXX
 SG_ RelativeHumidity : 48|8@1+ (0.4,0) [0.0|100.0] "%" Vector__XXX
 SG_ AuxLevel : 32|16@1+ (0.1,0) [0.0|6425.5] "mm" Vector__XXX
 SG_ AuxPress2 : 24|8@1+ (16,0) [0.0|4000.0] "kPa" Vector__XXX
 SG_ AuxPress1 : 16|8@1+ (16,0) [0.0|4000.0] "kPa" Vector__XXX
 SG_ AuxTemp2 : 8|8@1+ (1,-40) [-40.0|210.0] "°C" Vector__XXX
 SG_ AuxTemp1 : 0|8@1+ (1,-40) [-40.0|210.0] "°C" Vector__XXX

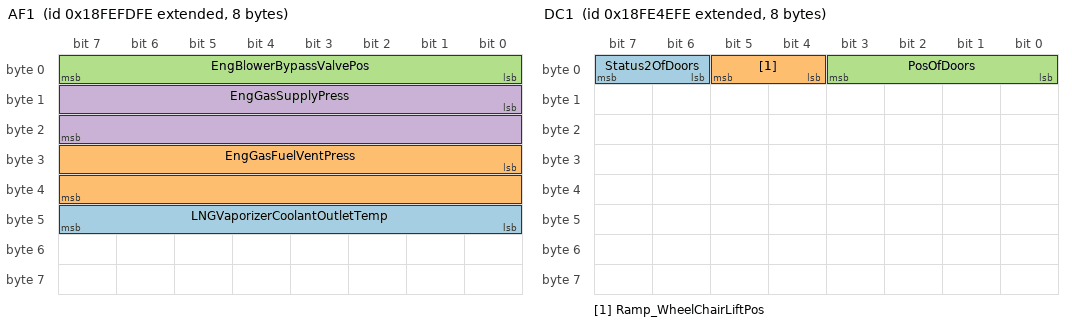
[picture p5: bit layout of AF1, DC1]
BO_ 2566847998 AF1: 8 Vector__XXX
 SG_ LNGVaporizerCoolantOutletTemp : 40|8@1+ (1,-40) [-40.0|210.0] "°C" Vector__XXX
 SG_ EngGasFuelVentPress : 24|16@1+ (0.5,0) [0.0|32127.5] "kPa" Vector__XXX
 SG_ EngBlowerBypassValvePos : 0|8@1+ (0.4,0) [0.0|100.0] "%" Vector__XXX
 SG_ EngGasSupplyPress : 8|16@1+ (0.5,0) [0.0|32127.5] "kPa" Vector__XXX

BO_ 2565406462 ACKM_59392: 8 Vector__XXX
 SG_ AddressBusy_3293 m3  : 32|8@1+ (1,0) [0.0|255.0] "" Vector__XXX
 SG_ ControlByte_2541 M  : 0|8@1+ (1,0) [0.0|255.0] "" Vector__XXX
 SG_ ParameterGroupNumber_2547 : 40|24@1+ (1,0) [0.0|16777215.0] "" Vector__XXX
 SG_ GroupFunctionValue : 8|8@1+ (1,0) [0.0|255.0] "" Vector__XXX
 SG_ AddressAccessDenied_3292 m2  : 32|8@1+ (1,0) [0.0|255.0] "" Vector__XXX
 SG_ AddressNegAcknoledgement_3291 m1  : 32|8@1+ (1,0) [0.0|255.0] "" Vector__XXX
 SG_ AddressAcknowledged_3290 m0  : 32|8@1+ (1,0) [0.0|255.0] "" Vector__XXX

BO_ 2566803198 DC1: 8 Vector__XXX
 SG_ Status2OfDoors : 6|2@1+ (1,0) [0.0|3.0] "" Vector__XXX
 SG_ Ramp_WheelChairLiftPos : 4|2@1+ (1,0) [0.0|3.0] "" Vector__XXX
 SG_ PosOfDoors : 0|4@1+ (1,0) [0.0|15.0] "" Vector__XXX

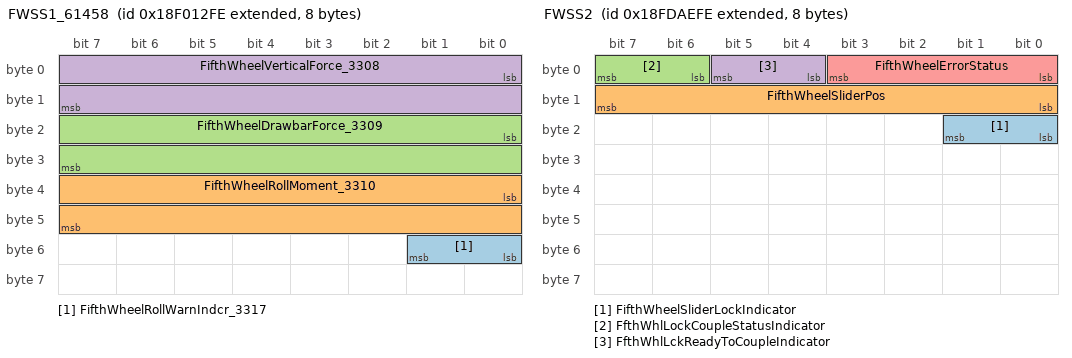
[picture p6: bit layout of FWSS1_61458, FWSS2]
BO_ 2565870334 FWSS1_61458: 8 Vector__XXX
 SG_ FifthWheelRollWarnIndcr_3317 : 48|2@1+ (1,0) [0.0|3.0] "" Vector__XXX
 SG_ FifthWheelRollMoment_3310 : 32|16@1+ (10,-320000) [-320000.0|322550.0] "N" Vector__XXX
 SG_ FifthWheelDrawbarForce_3309 : 16|16@1+ (10,-320000) [-320000.0|322550.0] "N" Vector__XXX
 SG_ FifthWheelVerticalForce_3308 : 0|16@1+ (5,0) [0.0|321275.0] "N" Vector__XXX

BO_ 2566762238 FWSS2: 8 Vector__XXX
 SG_ FifthWheelSliderLockIndicator : 16|2@1+ (1,0) [0.0|3.0] "" Vector__XXX
 SG_ FifthWheelSliderPos : 8|8@1+ (10,0) [0.0|2500.0] "mm" Vector__XXX
 SG_ FfthWhlLockCoupleStatusIndicator : 6|2@1+ (1,0) [0.0|3.0] "" Vector__XXX
 SG_ FfthWhlLckReadyToCoupleIndicator : 4|2@1+ (1,0) [0.0|3.0] "" Vector__XXX
 SG_ FifthWheelErrorStatus : 0|4@1+ (1,0) [0.0|15.0] "" Vector__XXX

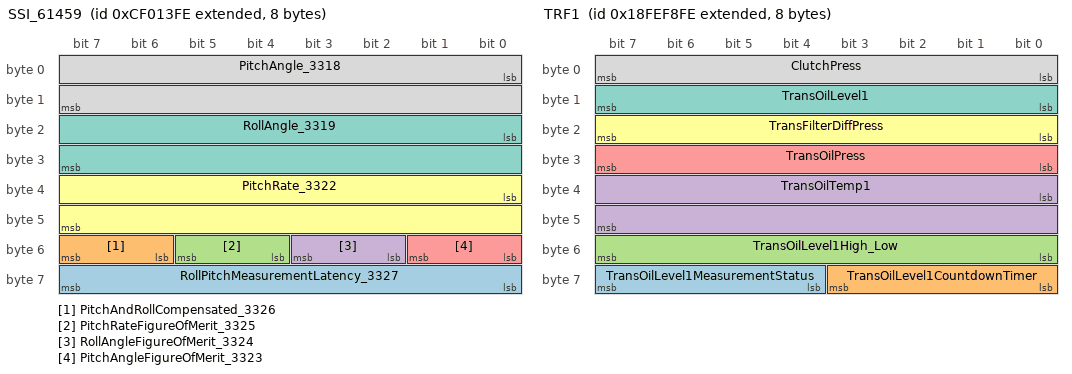
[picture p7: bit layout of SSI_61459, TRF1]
BO_ 2364543998 SSI_61459: 8 Vector__XXX
 SG_ RollPitchMeasurementLatency_3327 : 56|8@1+ (0.5,0) [0.0|125.0] "ms" Vector__XXX
 SG_ PitchAndRollCompensated_3326 : 54|2@1+ (1,0) [0.0|3.0] "" Vector__XXX
 SG_ PitchRateFigureOfMerit_3325 : 52|2@1+ (1,0) [0.0|3.0] "" Vector__XXX
 SG_ RollAngleFigureOfMerit_3324 : 50|2@1+ (1,0) [0.0|3.0] "" Vector__XXX
 SG_ PitchAngleFigureOfMerit_3323 : 48|2@1+ (1,0) [0.0|3.0] "" Vector__XXX
 SG_ PitchRate_3322 : 32|16@1+ (0.002,-64) [-64.0|64.51] "deg/s" Vector__XXX
 SG_ RollAngle_3319 : 16|16@1+ (0.002,-64) [-64.0|64.51] "deg" Vector__XXX
 SG_ PitchAngle_3318 : 0|16@1+ (0.002,-64) [-64.0|64.51] "deg" Vector__XXX

BO_ 2566846718 TRF1: 8 Vector__XXX
 SG_ TransOilLevel1MeasurementStatus : 60|4@1+ (1,0) [0.0|15.0] "" Vector__XXX
 SG_ TransOilLevel1CountdownTimer : 56|4@1+ (1,0) [0.0|13.0] "" Vector__XXX
 SG_ TransOilLevel1High_Low : 48|8@1+ (0.5,-62.5) [-62.5|62.5] "L" Vector__XXX
 SG_ TransOilTemp1 : 32|16@1+ (0.03125,-273) [-273.0|1734.96875] "°C" Vector__XXX
 SG_ TransOilPress : 24|8@1+ (16,0) [0.0|4000.0] "kPa" Vector__XXX
 SG_ TransFilterDiffPress : 16|8@1+ (2,0) [0.0|500.0] "kPa" Vector__XXX
 SG_ TransOilLevel1 : 8|8@1+ (0.4,0) [0.0|100.0] "%" Vector__XXX
 SG_ ClutchPress : 0|8@1+ (16,0) [0.0|4000.0] "kPa" Vector__XXX

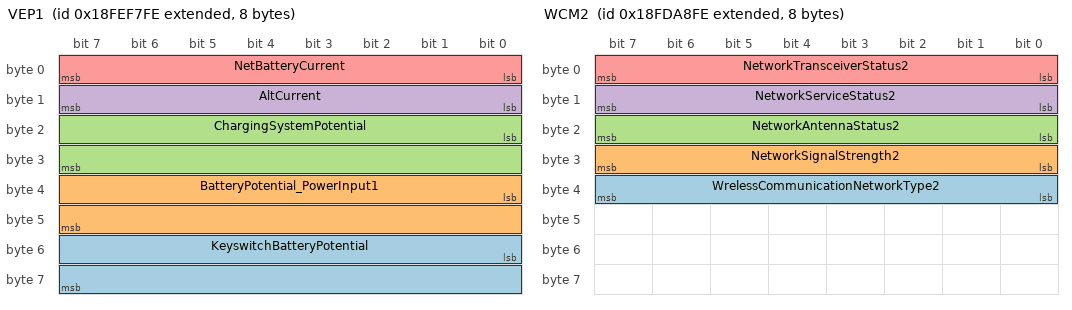
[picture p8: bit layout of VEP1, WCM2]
BO_ 2566846462 VEP1: 8 Vector__XXX
 SG_ KeyswitchBatteryPotential : 48|16@1+ (0.05,0) [0.0|3212.75] "V" Vector__XXX
 SG_ BatteryPotential_PowerInput1 : 32|16@1+ (0.05,0) [0.0|3212.75] "V" Vector__XXX
 SG_ ChargingSystemPotential : 16|16@1+ (0.05,0) [0.0|3212.75] "V" Vector__XXX
 SG_ AltCurrent : 8|8@1+ (1,0) [0.0|250.0] "A" Vector__XXX
 SG_ NetBatteryCurrent : 0|8@1+ (1,-125) [-125.0|125.0] "A" Vector__XXX

BO_ 2566760702 WCM2: 8 Vector__XXX
 SG_ WrelessCommunicationNetworkType2 : 32|8@1+ (1,0) [0.0|255.0] "" Vector__XXX
 SG_ NetworkSignalStrength2 : 24|8@1+ (0.4,0) [0.0|100.0] "%" Vector__XXX
 SG_ NetworkAntennaStatus2 : 16|8@1+ (1,0) [0.0|255.0] "" Vector__XXX
 SG_ NetworkServiceStatus2 : 8|8@1+ (1,0) [0.0|255.0] "" Vector__XXX
 SG_ NetworkTransceiverStatus2 : 0|8@1+ (1,0) [0.0|255.0] "" Vector__XXX

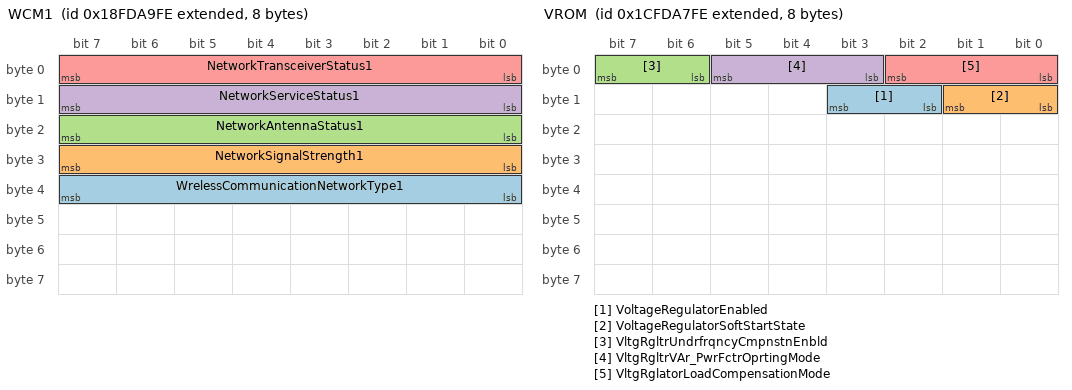
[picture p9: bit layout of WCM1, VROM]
BO_ 2566760958 WCM1: 8 Vector__XXX
 SG_ WrelessCommunicationNetworkType1 : 32|8@1+ (1,0) [0.0|255.0] "" Vector__XXX
 SG_ NetworkSignalStrength1 : 24|8@1+ (0.4,0) [0.0|100.0] "%" Vector__XXX
 SG_ NetworkAntennaStatus1 : 16|8@1+ (1,0) [0.0|255.0] "" Vector__XXX
 SG_ NetworkServiceStatus1 : 8|8@1+ (1,0) [0.0|255.0] "" Vector__XXX
 SG_ NetworkTransceiverStatus1 : 0|8@1+ (1,0) [0.0|255.0] "" Vector__XXX

BO_ 2633869310 VROM: 8 Vector__XXX
 SG_ VoltageRegulatorEnabled : 10|2@1+ (1,0) [0.0|3.0] "" Vector__XXX
 SG_ VoltageRegulatorSoftStartState : 8|2@1+ (1,0) [0.0|3.0] "" Vector__XXX
 SG_ VltgRgltrUndrfrqncyCmpnstnEnbld : 6|2@1+ (1,0) [0.0|3.0] "" Vector__XXX
 SG_ VltgRgltrVAr_PwrFctrOprtingMode : 3|3@1+ (1,0) [0.0|7.0] "" Vector__XXX
 SG_ VltgRglatorLoadCompensationMode : 0|3@1+ (1,0) [0.0|7.0] "" Vector__XXX

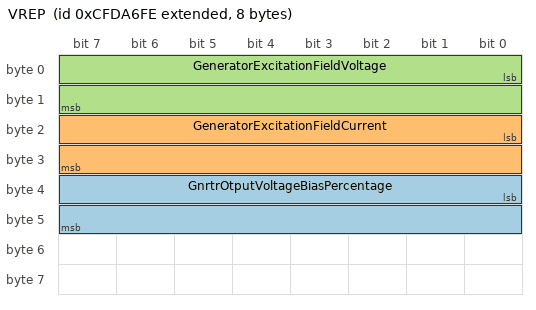
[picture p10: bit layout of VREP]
BO_ 2365433598 VREP: 8 Vector__XXX
 SG_ GnrtrOtputVoltageBiasPercentage : 32|16@1+ (0.1,-100) [-100.0|100.0] "%" Vector__XXX
 SG_ GeneratorExcitationFieldCurrent : 16|16@1+ (0.05,0) [0.0|3212.75] "A" Vector__XXX
 SG_ GeneratorExcitationFieldVoltage : 0|16@1+ (0.05,-1606) [-1606.0|1606.75] "V" Vector__XXX

CM_ BO_ 2566740990  "DTCs - B1, Confirmed and Active
Confirmed and Active DTCs that are classified as class B1 severity.";
CM_ BO_ 2566741246  "DTCs - B1, Pending
Pending DTCs that are classified as class B1 severity.";
CM_ BO_ 2566741502  "DTCs - A, Previously Active
Previously Active DTCs that are classified as class A severity.";
CM_ BO_ 2566741758  "DTCs - A, Confirmed and Active
Confirmed and Active DTCs that are classified as class A severity.";
CM_ BO_ 2566742014  "DTCs - A, Pending
Pending DTCs that are classified as class A severity.";
CM_ BO_ 2560622334  "Immediate Fault Status - The purpose of this DM is to enable the external test equipment to obtain the instantaneous status of diagnostic results";
CM_ BO_ 2566744062  "Zero Net Vehicle Weight Change
Zero Net Vehicle Weight Change";
CM_ BO_ 2499630078  "Engine Average Information
Reports averaged engine information";
CM_ BO_ 2560556798  "DTC Counts - The purpose of this DM is to identify the number of DTCs in each category. The categories are pending, all pending, MIL-on, previously MIL-on, and permanent DTCs.";
CM_ BO_ 2566750462  "Permanent DTCs
The purpose of this DM is to provide the list of permanent DTCs that are currently present. Permanent DTCs are defined as a confirmed or active MIL-on fault code that is currently commanding the MIL on and is stored in non-volatile ...";
CM_ BO_ 2566750974  "All Pending DTCs
To transmit “pending” diagnostic trouble codes detected during current or last completed driving cycle for components/systems that are tested or continuously monitored during normal driving conditions.";
CM_ BO_ 2566754558  "Advertised Engine Torque Curve
This message conveys the advertised torque curve for the engine, as typically seen on specification sheets available from most engine manufacturers.  The collection conditions for the data conveyed are indicated by ...";
CM_ BO_ 2566749950  "Adaptive Front-Lighting System Status
This message reports information about the current operation mode of the Adaptive Front-Lighting System (AFS). The Message may include information about dynamic bending light and light distribution. The message ...";
CM_ BO_ 2566838782  "Auxiliary Input/Output Status 1
Notes:
Implementers are encouraged to use specific functional SPNs whenever possible.
AUXIO PGNs are intended for two categories of use in which fixed mapping to functions is not possible:
1)  Generic I/O devices
...";
CM_ BO_ 2561146622  "Auxiliary Input/Output Status 2 - Notes:
Implementers are encouraged to use specific functional SPNs whenever possible.
AUXIO PGNs are intended for two categories of use in which fixed mapping to functions is not possible:
1)  Generic I/O devices
...";
CM_ BO_ 2561081086  "Auxiliary Input/Output Status 3 - Notes:
Implementers are encouraged to use specific functional SPNs whenever possible.
AUXIO PGNs are intended for two categories of use in which fixed mapping to functions is not possible:
1)  Generic I/O devices
...";
CM_ BO_ 2561015550  "Auxiliary Input/Output Status 4 - Notes:
Implementers are encouraged to use specific functional SPNs whenever possible.
AUXIO PGNs are intended for two categories of use in which fixed mapping to functions is not possible:
1)  Generic I/O devices
...";
CM_ BO_ 2566746622  "Brake actuator stroke status
The Brake Stroke Alert (BSA) message will provide the brake actuator stroke status for up to 20 wheel ends.";
CM_ BO_ 2566845950  "Ambient Conditions";
CM_ BO_ 2566840062  "Engine Air Start Pressure";
CM_ BO_ 2566827774  "Air Supply Pressure
Air Supply Pressure";
CM_ BO_ 2566846974  "Axle Information
Axle information message
NOTE–Message must be repeated as necessary to transmit all available information.   This method of location identification requires individual SPNs to be assigned to report failures specific to each ...";
CM_ BO_ 2633935614  "Alternate Fuel 2";
CM_ BO_ 2566803966  "Adaptive Cruise Control, Operator Input
The operator requested characteristics for the ACC systems operation.";
CM_ BO_ 2432593918  "Adaptive Cruise Control 1
NOTE—The ACC1 message is required whenever the engine is running and ACC is powered on and not
faulted. The timeout for ACC1 message will be between 2.5 times to 5 times the update rate.
The ACC1 message is intended ...";
CM_ BO_ 2633935102  "Articulation Control";
CM_ BO_ 2633927934  "Auxiliary Analog Information
Auxiliary Analog Information";
CM_ BO_ 2566847998  "Alternate Fuel 1";
CM_ BO_ 2565406462  "Acknowledgment Message
The Acknowledgment PG is used to provide a handshake mechanism between transmitting and receiving devices.";
CM_ BO_ 2566803198  "Door Control 1
Used for door information.";
CM_ BO_ 2565870334  "Fifth Wheel Smart Systems 1 - Fifth wheel smart system information. Parameters used to determine the status of the tractor to trailer coupling system integrity.";
CM_ BO_ 2566762238  "Fifth Wheel Smart Systems 2
Fifth wheel smart system information #2. Message to convey operator parameters associated with the tractor to trailer coupling control and error state.";
CM_ BO_ 2364543998  "Slope Sensor Information - The Slope Sensor Information message shall provide a measurement of the vehicles pitch angle, a measurement of the vehicles roll angle, and a measurement of the vehicles pitch rate.  The vehicle dynamics measurements in ...";
CM_ BO_ 2566846718  "Transmission Fluids 1";
CM_ BO_ 2566846462  "Vehicle Electrical Power 1";
CM_ BO_ 2566760702  "Wireless Communications Message 2
Message for reporting status information regarding the second instance of a wireless communications network on a device or system.
See PGN 64937 for the first wireless network.";
CM_ BO_ 2566760958  "Wireless Communications Message 1
Message for reporting status information regarding the first instance of a wireless communications network on a device or system.";
CM_ BO_ 2633869310  "Voltage Regulator Operating Mode
Contains operating modes for the following voltage regulator functions:  Unit Mode, Soft Start Mode, Under Frequency Mode, Operating Mode, Load Compensation Mode.";
CM_ BO_ 2365433598  "Voltage Regulator Excitation Status
Contains voltage regulator parameters that pertain to the generation excitation";
CM_ SG_ 2566740990 FlashRedStopLamp "This parameter provides the capability to flash the RSL
00 - Slow Flash (1 Hz, 50 % duty cycle)
01 - Fast Flash (2 Hz or faster, 50% duty cycle)
10 - Reserved
11 - Unavailable / Do Not Flash";
CM_ SG_ 2566740990 FlashProtectLamp "This parameter provides the capability to flash the engine protect lamp
00 - Slow Flash (1 Hz, 50 % duty cycle)
01 - Fast Flash (2 Hz or faster, 50% duty cycle)
10 - Reserved
11 - Unavailable / Do Not Flash";
CM_ SG_ 2566740990 FlashMalfuncIndicatorLamp "This parameter provides the capability to flash the MIL
00 - Slow Flash (1 Hz, 50 % duty cycle)
01 - Fast Flash (2 Hz or faster, 50% duty cycle)
10 - Class C DTC
11 - Unavailable / Do Not Flash
Note:  State 10 is for WWH OBD discriminatory ...";
CM_ SG_ 2566740990 FlashAmberWarningLamp "This parameter provides the capability to flash the AWL
00 - Slow Flash (1 Hz, 50 % duty cycle)
01 - Fast Flash (2 Hz or faster, 50% duty cycle)
10 - Reserved
11 - Unavailable / Do Not Flash";
CM_ SG_ 2566740990 MalfunctionIndicatorLampStatus "A lamp used to relay only emissions-related trouble code information. This lamp is only illuminated when there is an emission-related trouble code active.
00     Lamp Off
01     Lamp On
10     Short MIL for WWH OBD
11     Not available
Note ...";
CM_ SG_ 2566740990 AmberWarningLampStatus "This lamp is used to relay trouble code information that is reporting a problem with the vehicle system but the vehicle need not be immediately stopped.
00     Lamp Off
01     Lamp On
10     Reserved
11     Not available";
CM_ SG_ 2566740990 RedStopLampState "This lamp is used to relay trouble code information that is of a severe enough condition that it warrants stopping the vehicle.
00     Lamp Off
01     Lamp On
10     Reserved
11     Not available";
CM_ SG_ 2566740990 ProtectLampStatus "This lamp is used to relay trouble code information that is reporting a problem with a vehicle system that is most probably not electronic subsystem related. For instance, engine coolant temperature is exceeding its prescribed temperature range.
00 ...";
CM_ SG_ 2566740990 DTC5 "Diagnostic Trouble Code";
CM_ SG_ 2566740990 DTC4 "Diagnostic Trouble Code";
CM_ SG_ 2566740990 DTC3 "Diagnostic Trouble Code";
CM_ SG_ 2566740990 DTC2 "Diagnostic Trouble Code";
CM_ SG_ 2566740990 DTC1 "Diagnostic Trouble Code";
CM_ SG_ 2566741246 FlashRedStopLamp "This parameter provides the capability to flash the RSL
00 - Slow Flash (1 Hz, 50 % duty cycle)
01 - Fast Flash (2 Hz or faster, 50% duty cycle)
10 - Reserved
11 - Unavailable / Do Not Flash";
CM_ SG_ 2566741246 FlashProtectLamp "This parameter provides the capability to flash the engine protect lamp
00 - Slow Flash (1 Hz, 50 % duty cycle)
01 - Fast Flash (2 Hz or faster, 50% duty cycle)
10 - Reserved
11 - Unavailable / Do Not Flash";
CM_ SG_ 2566741246 FlashMalfuncIndicatorLamp "This parameter provides the capability to flash the MIL
00 - Slow Flash (1 Hz, 50 % duty cycle)
01 - Fast Flash (2 Hz or faster, 50% duty cycle)
10 - Class C DTC
11 - Unavailable / Do Not Flash
Note:  State 10 is for WWH OBD discriminatory ...";
CM_ SG_ 2566741246 FlashAmberWarningLamp "This parameter provides the capability to flash the AWL
00 - Slow Flash (1 Hz, 50 % duty cycle)
01 - Fast Flash (2 Hz or faster, 50% duty cycle)
10 - Reserved
11 - Unavailable / Do Not Flash";
CM_ SG_ 2566741246 MalfunctionIndicatorLampStatus "A lamp used to relay only emissions-related trouble code information. This lamp is only illuminated when there is an emission-related trouble code active.
00     Lamp Off
01     Lamp On
10     Short MIL for WWH OBD
11     Not available
Note ...";
CM_ SG_ 2566741246 AmberWarningLampStatus "This lamp is used to relay trouble code information that is reporting a problem with the vehicle system but the vehicle need not be immediately stopped.
00     Lamp Off
01     Lamp On
10     Reserved
11     Not available";
CM_ SG_ 2566741246 RedStopLampState "This lamp is used to relay trouble code information that is of a severe enough condition that it warrants stopping the vehicle.
00     Lamp Off
01     Lamp On
10     Reserved
11     Not available";
CM_ SG_ 2566741246 ProtectLampStatus "This lamp is used to relay trouble code information that is reporting a problem with a vehicle system that is most probably not electronic subsystem related. For instance, engine coolant temperature is exceeding its prescribed temperature range.
00 ...";
CM_ SG_ 2566741246 DTC5 "Diagnostic Trouble Code";
CM_ SG_ 2566741246 DTC4 "Diagnostic Trouble Code";
CM_ SG_ 2566741246 DTC3 "Diagnostic Trouble Code";
CM_ SG_ 2566741246 DTC2 "Diagnostic Trouble Code";
CM_ SG_ 2566741246 DTC1 "Diagnostic Trouble Code";
CM_ SG_ 2566741502 FlashRedStopLamp "This parameter provides the capability to flash the RSL
00 - Slow Flash (1 Hz, 50 % duty cycle)
01 - Fast Flash (2 Hz or faster, 50% duty cycle)
10 - Reserved
11 - Unavailable / Do Not Flash";
CM_ SG_ 2566741502 FlashProtectLamp "This parameter provides the capability to flash the engine protect lamp
00 - Slow Flash (1 Hz, 50 % duty cycle)
01 - Fast Flash (2 Hz or faster, 50% duty cycle)
10 - Reserved
11 - Unavailable / Do Not Flash";
CM_ SG_ 2566741502 FlashMalfuncIndicatorLamp "This parameter provides the capability to flash the MIL
00 - Slow Flash (1 Hz, 50 % duty cycle)
01 - Fast Flash (2 Hz or faster, 50% duty cycle)
10 - Class C DTC
11 - Unavailable / Do Not Flash
Note:  State 10 is for WWH OBD discriminatory ...";
CM_ SG_ 2566741502 FlashAmberWarningLamp "This parameter provides the capability to flash the AWL
00 - Slow Flash (1 Hz, 50 % duty cycle)
01 - Fast Flash (2 Hz or faster, 50% duty cycle)
10 - Reserved
11 - Unavailable / Do Not Flash";
CM_ SG_ 2566741502 MalfunctionIndicatorLampStatus "A lamp used to relay only emissions-related trouble code information. This lamp is only illuminated when there is an emission-related trouble code active.
00     Lamp Off
01     Lamp On
10     Short MIL for WWH OBD
11     Not available
Note ...";
CM_ SG_ 2566741502 AmberWarningLampStatus "This lamp is used to relay trouble code information that is reporting a problem with the vehicle system but the vehicle need not be immediately stopped.
00     Lamp Off
01     Lamp On
10     Reserved
11     Not available";
CM_ SG_ 2566741502 RedStopLampState "This lamp is used to relay trouble code information that is of a severe enough condition that it warrants stopping the vehicle.
00     Lamp Off
01     Lamp On
10     Reserved
11     Not available";
CM_ SG_ 2566741502 ProtectLampStatus "This lamp is used to relay trouble code information that is reporting a problem with a vehicle system that is most probably not electronic subsystem related. For instance, engine coolant temperature is exceeding its prescribed temperature range.
00 ...";
CM_ SG_ 2566741502 DTC5 "Diagnostic Trouble Code";
CM_ SG_ 2566741502 DTC4 "Diagnostic Trouble Code";
CM_ SG_ 2566741502 DTC3 "Diagnostic Trouble Code";
CM_ SG_ 2566741502 DTC2 "Diagnostic Trouble Code";
CM_ SG_ 2566741502 DTC1 "Diagnostic Trouble Code";
CM_ SG_ 2566741758 FlashRedStopLamp "This parameter provides the capability to flash the RSL
00 - Slow Flash (1 Hz, 50 % duty cycle)
01 - Fast Flash (2 Hz or faster, 50% duty cycle)
10 - Reserved
11 - Unavailable / Do Not Flash";
CM_ SG_ 2566741758 FlashProtectLamp "This parameter provides the capability to flash the engine protect lamp
00 - Slow Flash (1 Hz, 50 % duty cycle)
01 - Fast Flash (2 Hz or faster, 50% duty cycle)
10 - Reserved
11 - Unavailable / Do Not Flash";
CM_ SG_ 2566741758 FlashMalfuncIndicatorLamp "This parameter provides the capability to flash the MIL
00 - Slow Flash (1 Hz, 50 % duty cycle)
01 - Fast Flash (2 Hz or faster, 50% duty cycle)
10 - Class C DTC
11 - Unavailable / Do Not Flash
Note:  State 10 is for WWH OBD discriminatory ...";
CM_ SG_ 2566741758 FlashAmberWarningLamp "This parameter provides the capability to flash the AWL
00 - Slow Flash (1 Hz, 50 % duty cycle)
01 - Fast Flash (2 Hz or faster, 50% duty cycle)
10 - Reserved
11 - Unavailable / Do Not Flash";
CM_ SG_ 2566741758 MalfunctionIndicatorLampStatus "A lamp used to relay only emissions-related trouble code information. This lamp is only illuminated when there is an emission-related trouble code active.
00     Lamp Off
01     Lamp On
10     Short MIL for WWH OBD
11     Not available
Note ...";
CM_ SG_ 2566741758 AmberWarningLampStatus "This lamp is used to relay trouble code information that is reporting a problem with the vehicle system but the vehicle need not be immediately stopped.
00     Lamp Off
01     Lamp On
10     Reserved
11     Not available";
CM_ SG_ 2566741758 RedStopLampState "This lamp is used to relay trouble code information that is of a severe enough condition that it warrants stopping the vehicle.
00     Lamp Off
01     Lamp On
10     Reserved
11     Not available";
CM_ SG_ 2566741758 ProtectLampStatus "This lamp is used to relay trouble code information that is reporting a problem with a vehicle system that is most probably not electronic subsystem related. For instance, engine coolant temperature is exceeding its prescribed temperature range.
00 ...";
CM_ SG_ 2566741758 DTC5 "Diagnostic Trouble Code";
CM_ SG_ 2566741758 DTC4 "Diagnostic Trouble Code";
CM_ SG_ 2566741758 DTC3 "Diagnostic Trouble Code";
CM_ SG_ 2566741758 DTC2 "Diagnostic Trouble Code";
CM_ SG_ 2566741758 DTC1 "Diagnostic Trouble Code";
CM_ SG_ 2566742014 FlashRedStopLamp "This parameter provides the capability to flash the RSL
00 - Slow Flash (1 Hz, 50 % duty cycle)
01 - Fast Flash (2 Hz or faster, 50% duty cycle)
10 - Reserved
11 - Unavailable / Do Not Flash";
CM_ SG_ 2566742014 FlashProtectLamp "This parameter provides the capability to flash the engine protect lamp
00 - Slow Flash (1 Hz, 50 % duty cycle)
01 - Fast Flash (2 Hz or faster, 50% duty cycle)
10 - Reserved
11 - Unavailable / Do Not Flash";
CM_ SG_ 2566742014 FlashMalfuncIndicatorLamp "This parameter provides the capability to flash the MIL
00 - Slow Flash (1 Hz, 50 % duty cycle)
01 - Fast Flash (2 Hz or faster, 50% duty cycle)
10 - Class C DTC
11 - Unavailable / Do Not Flash
Note:  State 10 is for WWH OBD discriminatory ...";
CM_ SG_ 2566742014 FlashAmberWarningLamp "This parameter provides the capability to flash the AWL
00 - Slow Flash (1 Hz, 50 % duty cycle)
01 - Fast Flash (2 Hz or faster, 50% duty cycle)
10 - Reserved
11 - Unavailable / Do Not Flash";
CM_ SG_ 2566742014 MalfunctionIndicatorLampStatus "A lamp used to relay only emissions-related trouble code information. This lamp is only illuminated when there is an emission-related trouble code active.
00     Lamp Off
01     Lamp On
10     Short MIL for WWH OBD
11     Not available
Note ...";
CM_ SG_ 2566742014 AmberWarningLampStatus "This lamp is used to relay trouble code information that is reporting a problem with the vehicle system but the vehicle need not be immediately stopped.
00     Lamp Off
01     Lamp On
10     Reserved
11     Not available";
CM_ SG_ 2566742014 RedStopLampState "This lamp is used to relay trouble code information that is of a severe enough condition that it warrants stopping the vehicle.
00     Lamp Off
01     Lamp On
10     Reserved
11     Not available";
CM_ SG_ 2566742014 ProtectLampStatus "This lamp is used to relay trouble code information that is reporting a problem with a vehicle system that is most probably not electronic subsystem related. For instance, engine coolant temperature is exceeding its prescribed temperature range.
00 ...";
CM_ SG_ 2566742014 DTC5 "Diagnostic Trouble Code";
CM_ SG_ 2566742014 DTC4 "Diagnostic Trouble Code";
CM_ SG_ 2566742014 DTC3 "Diagnostic Trouble Code";
CM_ SG_ 2566742014 DTC2 "Diagnostic Trouble Code";
CM_ SG_ 2566742014 DTC1 "Diagnostic Trouble Code";
CM_ SG_ 2560622334 FlashRedStopLamp_3039 "This parameter provides the capability to flash the RSL
00 - Slow Flash (1 Hz, 50 % duty cycle)
01 - Fast Flash (2 Hz or faster, 50% duty cycle)
10 - Reserved
11 - Unavailable / Do Not Flash";
CM_ SG_ 2560622334 FlashProtectLamp_3041 "This parameter provides the capability to flash the engine protect lamp
00 - Slow Flash (1 Hz, 50 % duty cycle)
01 - Fast Flash (2 Hz or faster, 50% duty cycle)
10 - Reserved
11 - Unavailable / Do Not Flash";
CM_ SG_ 2560622334 FlashMalfuncIndicatorLamp_3038 "This parameter provides the capability to flash the MIL
00 - Slow Flash (1 Hz, 50 % duty cycle)
01 - Fast Flash (2 Hz or faster, 50% duty cycle)
10 - Class C DTC
11 - Unavailable / Do Not Flash
Note:  State 10 is for WWH OBD discriminatory ...";
CM_ SG_ 2560622334 FlashAmberWarningLamp_3040 "This parameter provides the capability to flash the AWL
00 - Slow Flash (1 Hz, 50 % duty cycle)
01 - Fast Flash (2 Hz or faster, 50% duty cycle)
10 - Reserved
11 - Unavailable / Do Not Flash";
CM_ SG_ 2560622334 MILStatus_1213 "A lamp used to relay only emissions-related trouble code information. This lamp is only illuminated when there is an emission-related trouble code active.
00     Lamp Off
01     Lamp On
10     Short MIL for WWH OBD
11     Not available
Note ...";
CM_ SG_ 2560622334 AmberWarningLampStatus_624 "This lamp is used to relay trouble code information that is reporting a problem with the vehicle system but the vehicle need not be immediately stopped.
00     Lamp Off
01     Lamp On
10     Reserved
11     Not available";
CM_ SG_ 2560622334 RedStopLampState_623 "This lamp is used to relay trouble code information that is of a severe enough condition that it warrants stopping the vehicle.
00     Lamp Off
01     Lamp On
10     Reserved
11     Not available";
CM_ SG_ 2560622334 ProtectLampStatus_987 "This lamp is used to relay trouble code information that is reporting a problem with a vehicle system that is most probably not electronic subsystem related. For instance, engine coolant temperature is exceeding its prescribed temperature range.
00 ...";
CM_ SG_ 2560622334 DTC5 "Diagnostic Trouble Code";
CM_ SG_ 2560622334 DTC4 "Diagnostic Trouble Code";
CM_ SG_ 2560622334 DTC3 "Diagnostic Trouble Code";
CM_ SG_ 2560622334 DTC2 "Diagnostic Trouble Code";
CM_ SG_ 2560622334 DTC1 "Diagnostic Trouble Code";
CM_ SG_ 2566744062 ZeroNetVehicleWeightChange "Zero Net Vehicle Weight Change command.  A controller receiving this command will record the current Gross Combination Weight as the new Zero, and future requests for Net Vehicle Weight Change will be answered with the difference between the (then) ...";
CM_ SG_ 2499630078 EngExhaustGasTempAverageBank2 "The calculated average temperature based upon all of the Bank 2 (right bank) engine exhaust port temperatures.  This is the average temperature based upon the exhaust port temperature measurements of each of the engine cylinders on the right bank ...";
CM_ SG_ 2499630078 EngExhaustGasTempAverageBank1 "The calculated average temperature based upon all of the Bank 1 (left bank) engine exhaust port temperatures.  This is the average temperature based upon the exhaust port temperature measurements of each of the engine cylinders on the left bank ...";
CM_ SG_ 2499630078 EngExhaustGasTempAverage "The calculated average temperature based upon all of the engine exhaust port temperatures.  This is the average temperature based upon the exhaust port temperature measurements at each of the engine cylinders.
Notes:
Use SPN 173 - Engine Exhaust ...";
CM_ SG_ 2566750462 FlashRedStopLamp "This parameter provides the capability to flash the RSL
00 - Slow Flash (1 Hz, 50 % duty cycle)
01 - Fast Flash (2 Hz or faster, 50% duty cycle)
10 - Reserved
11 - Unavailable / Do Not Flash";
CM_ SG_ 2566750462 FlashProtectLamp "This parameter provides the capability to flash the engine protect lamp
00 - Slow Flash (1 Hz, 50 % duty cycle)
01 - Fast Flash (2 Hz or faster, 50% duty cycle)
10 - Reserved
11 - Unavailable / Do Not Flash";
CM_ SG_ 2566750462 FlashMalfuncIndicatorLamp "This parameter provides the capability to flash the MIL
00 - Slow Flash (1 Hz, 50 % duty cycle)
01 - Fast Flash (2 Hz or faster, 50% duty cycle)
10 - Class C DTC
11 - Unavailable / Do Not Flash
Note:  State 10 is for WWH OBD discriminatory ...";
CM_ SG_ 2566750462 FlashAmberWarningLamp "This parameter provides the capability to flash the AWL
00 - Slow Flash (1 Hz, 50 % duty cycle)
01 - Fast Flash (2 Hz or faster, 50% duty cycle)
10 - Reserved
11 - Unavailable / Do Not Flash";
CM_ SG_ 2566750462 MalfunctionIndicatorLampStatus "A lamp used to relay only emissions-related trouble code information. This lamp is only illuminated when there is an emission-related trouble code active.
00     Lamp Off
01     Lamp On
10     Short MIL for WWH OBD
11     Not available
Note ...";
CM_ SG_ 2566750462 AmberWarningLampStatus "This lamp is used to relay trouble code information that is reporting a problem with the vehicle system but the vehicle need not be immediately stopped.
00     Lamp Off
01     Lamp On
10     Reserved
11     Not available";
CM_ SG_ 2566750462 RedStopLampState "This lamp is used to relay trouble code information that is of a severe enough condition that it warrants stopping the vehicle.
00     Lamp Off
01     Lamp On
10     Reserved
11     Not available";
CM_ SG_ 2566750462 ProtectLampStatus "This lamp is used to relay trouble code information that is reporting a problem with a vehicle system that is most probably not electronic subsystem related. For instance, engine coolant temperature is exceeding its prescribed temperature range.
00 ...";
CM_ SG_ 2566750462 DTC5 "Diagnostic Trouble Code";
CM_ SG_ 2566750462 DTC4 "Diagnostic Trouble Code";
CM_ SG_ 2566750462 DTC3 "Diagnostic Trouble Code";
CM_ SG_ 2566750462 DTC2 "Diagnostic Trouble Code";
CM_ SG_ 2566750462 DTC1 "Diagnostic Trouble Code";
CM_ SG_ 2566750974 FlashRedStopLamp "This parameter provides the capability to flash the RSL
00 - Slow Flash (1 Hz, 50 % duty cycle)
01 - Fast Flash (2 Hz or faster, 50% duty cycle)
10 - Reserved
11 - Unavailable / Do Not Flash";
CM_ SG_ 2566750974 FlashProtectLamp "This parameter provides the capability to flash the engine protect lamp
00 - Slow Flash (1 Hz, 50 % duty cycle)
01 - Fast Flash (2 Hz or faster, 50% duty cycle)
10 - Reserved
11 - Unavailable / Do Not Flash";
CM_ SG_ 2566750974 FlashMalfuncIndicatorLamp "This parameter provides the capability to flash the MIL
00 - Slow Flash (1 Hz, 50 % duty cycle)
01 - Fast Flash (2 Hz or faster, 50% duty cycle)
10 - Class C DTC
11 - Unavailable / Do Not Flash
Note:  State 10 is for WWH OBD discriminatory ...";
CM_ SG_ 2566750974 FlashAmberWarningLamp "This parameter provides the capability to flash the AWL
00 - Slow Flash (1 Hz, 50 % duty cycle)
01 - Fast Flash (2 Hz or faster, 50% duty cycle)
10 - Reserved
11 - Unavailable / Do Not Flash";
CM_ SG_ 2566750974 MalfunctionIndicatorLampStatus "A lamp used to relay only emissions-related trouble code information. This lamp is only illuminated when there is an emission-related trouble code active.
00     Lamp Off
01     Lamp On
10     Short MIL for WWH OBD
11     Not available
Note ...";
CM_ SG_ 2566750974 AmberWarningLampStatus "This lamp is used to relay trouble code information that is reporting a problem with the vehicle system but the vehicle need not be immediately stopped.
00     Lamp Off
01     Lamp On
10     Reserved
11     Not available";
CM_ SG_ 2566750974 RedStopLampState "This lamp is used to relay trouble code information that is of a severe enough condition that it warrants stopping the vehicle.
00     Lamp Off
01     Lamp On
10     Reserved
11     Not available";
CM_ SG_ 2566750974 ProtectLampStatus "This lamp is used to relay trouble code information that is reporting a problem with a vehicle system that is most probably not electronic subsystem related. For instance, engine coolant temperature is exceeding its prescribed temperature range.
00 ...";
CM_ SG_ 2566750974 DTC5 "Diagnostic Trouble Code";
CM_ SG_ 2566750974 DTC4 "Diagnostic Trouble Code";
CM_ SG_ 2566750974 DTC3 "Diagnostic Trouble Code";
CM_ SG_ 2566750974 DTC2 "Diagnostic Trouble Code";
CM_ SG_ 2566750974 DTC1 "Diagnostic Trouble Code";
CM_ SG_ 2566754558 AETCTorqueValue14 "Engine torque value of the data points in PGN 64912 – Advertised Engine Torque Curve (AETC).";
CM_ SG_ 2566754558 AETCTorqueValue13 "Engine torque value of the data points in PGN 64912 – Advertised Engine Torque Curve (AETC).";
CM_ SG_ 2566754558 AETCTorqueValue12 "Engine torque value of the data points in PGN 64912 – Advertised Engine Torque Curve (AETC).";
CM_ SG_ 2566754558 AETCTorqueValue11 "Engine torque value of the data points in PGN 64912 – Advertised Engine Torque Curve (AETC).";
CM_ SG_ 2566754558 AETCTorqueValue10 "Engine torque value of the data points in PGN 64912 – Advertised Engine Torque Curve (AETC).";
CM_ SG_ 2566754558 AETCTorqueValue09 "Engine torque value of the data points in PGN 64912 – Advertised Engine Torque Curve (AETC).";
CM_ SG_ 2566754558 AETCTorqueValue08 "Engine torque value of the data points in PGN 64912 – Advertised Engine Torque Curve (AETC).";
CM_ SG_ 2566754558 AETCTorqueValue07 "Engine torque value of the data points in PGN 64912 – Advertised Engine Torque Curve (AETC).";
CM_ SG_ 2566754558 AETCTorqueValue06 "Engine torque value of the data points in PGN 64912 – Advertised Engine Torque Curve (AETC).";
CM_ SG_ 2566754558 AETCTorqueValue05 "Engine torque value of the data points in PGN 64912 – Advertised Engine Torque Curve (AETC).";
CM_ SG_ 2566754558 AETCTorqueValue04 "Engine torque value of the data points in PGN 64912 – Advertised Engine Torque Curve (AETC).";
CM_ SG_ 2566754558 AETCTorqueValue03 "Engine torque value of the data points in PGN 64912 – Advertised Engine Torque Curve (AETC).";
CM_ SG_ 2566754558 AETCTorqueValue02 "Engine torque value of the data points in PGN 64912 – Advertised Engine Torque Curve (AETC).";
CM_ SG_ 2566754558 AETCTorqueValue01 "Engine torque value of the data points in PGN 64912 – Advertised Engine Torque Curve (AETC).";
CM_ SG_ 2566754558 AETCSpeedValue14 "Engine speed value of the data points in PGN 64912 – Advertised Engine Torque Curve (AETC).";
CM_ SG_ 2566754558 AETCSpeedValue13 "Engine speed value of the data points in PGN 64912 – Advertised Engine Torque Curve (AETC).";
CM_ SG_ 2566754558 AETCSpeedValue12 "Engine speed value of the data points in PGN 64912 – Advertised Engine Torque Curve (AETC).";
CM_ SG_ 2566754558 AETCSpeedValue11 "Engine speed value of the data points in PGN 64912 – Advertised Engine Torque Curve (AETC).";
CM_ SG_ 2566754558 AETCSpeedValue10 "Engine speed value of the data points in PGN 64912 – Advertised Engine Torque Curve (AETC).";
CM_ SG_ 2566754558 AETCSpeedValue09 "Engine speed value of the data points in PGN 64912 – Advertised Engine Torque Curve (AETC).";
CM_ SG_ 2566754558 AETCSpeedValue08 "Engine speed value of the data points in PGN 64912 – Advertised Engine Torque Curve (AETC).";
CM_ SG_ 2566754558 AETCSpeedValue07 "Engine speed value of the data points in PGN 64912 – Advertised Engine Torque Curve (AETC).";
CM_ SG_ 2566754558 AETCSpeedValue06 "Engine speed value of the data points in PGN 64912 – Advertised Engine Torque Curve (AETC).";
CM_ SG_ 2566754558 AETCSpeedValue05 "Engine speed value of the data points in PGN 64912 – Advertised Engine Torque Curve (AETC).";
CM_ SG_ 2566754558 AETCSpeedValue04 "Engine speed value of the data points in PGN 64912 – Advertised Engine Torque Curve (AETC).";
CM_ SG_ 2566754558 AETCSpeedValue03 "Engine speed value of the data points in PGN 64912 – Advertised Engine Torque Curve (AETC).";
CM_ SG_ 2566754558 AETCSpeedValue02 "Engine speed value of the data points in PGN 64912 – Advertised Engine Torque Curve (AETC).";
CM_ SG_ 2566754558 AETCSpeedValue01 "Engine speed value of the data points in PGN 64912 – Advertised Engine Torque Curve (AETC).";
CM_ SG_ 2566754558 AETCTorqueValue00 "Engine torque value of the data points in PGN 64912 – Advertised Engine Torque Curve (AETC).";
CM_ SG_ 2566754558 AETCSpeedValue00 "Engine speed value of the data points in PGN 64912 – Advertised Engine Torque Curve (AETC).";
CM_ SG_ 2566754558 NumberOfAETCDataPoints "Indicates the number of speed / torque data points contained in the Advertised Engine Torque Curve broadcast (AETC).  A minimum of 5 points is required, with a maximum of 15 points available as needed to accurately convey the curve.";
CM_ SG_ 2566754558 AETCDataCollectionStandard "Indicates the standardized method by which torque data was obtained for the Advertised Engine Torque Curve (AETC).  For example, in North America, heavy duty diesel engine specifications are typically based on SAE J1995.  Other applicable SAE, ISO, ...";
CM_ SG_ 2566749950 RightHeadlampLightDistribution "This parameter indicates what kind of light distribution is set by the AFS system for the right headlamp.
0000   Light distribution town - The basic light distribution for town light is generated with a symmetrical cut-off line (Class V)
0001 ...";
CM_ SG_ 2566749950 LeftHeadlampLightDistribution "This parameter indicates what kind of light distribution is set by the AFS system for the left headlamp.
0000   Light distribution town - The basic light distribution for town light is generated with a symmetrical cut-off line (Class V)
0001 ...";
CM_ SG_ 2566749950 RightHeadlampDynamicBendingLight "This parameter indicates whether the dynamic bending light of the left headlamp is working properly.
000   Dynamic bending light deactivated.  There is no problem but for some reasons (e.g. daylight present) the bending light is deactivated.
001 ...";
CM_ SG_ 2566749950 LeftHeadlampDynamicBendingLight "This parameter indicates whether the dynamic bending light of the left headlamp is working properly.
000   Dynamic bending light deactivated.  There is no problem but for some reasons (e.g. daylight present) the bending light is deactivated.
001 ...";
CM_ SG_ 2566838782 AuxI_OChannel2 "Auxiliary channel of data (16 bit) read by the ECU.  This data is in A/D counts and is manufacturer specific.  It may be configured uniquely per application.";
CM_ SG_ 2566838782 AuxI_OChannel1 "Auxiliary channel of data (16 bit) read by the ECU.  This data is in A/D counts and is manufacturer specific.  It may be configured uniquely per application.";
CM_ SG_ 2566838782 AuxI_O13 "Identifies the current status of auxiliary input/output functions that are configured uniquely per application.
00 - Auxiliary channel off
01 - Auxiliary channel on
10 - Error
11 - Not available";
CM_ SG_ 2566838782 AuxI_O14 "Identifies the current status of auxiliary input/output functions that are configured uniquely per application.
00 - Auxiliary channel off
01 - Auxiliary channel on
10 - Error
11 - Not available";
CM_ SG_ 2566838782 AuxI_O15 "Identifies the current status of auxiliary input/output functions that are configured uniquely per application.
00 - Auxiliary channel off
01 - Auxiliary channel on
10 - Error
11 - Not available";
CM_ SG_ 2566838782 AuxI_O16 "Identifies the current status of auxiliary input/output functions that are configured uniquely per application.
00 - Auxiliary channel off
01 - Auxiliary channel on
10 - Error
11 - Not available";
CM_ SG_ 2566838782 AuxI_O09 "Identifies the current status of auxiliary input/output functions that are configured uniquely per application.
00 - Auxiliary channel off
01 - Auxiliary channel on
10 - Error
11 - Not available";
CM_ SG_ 2566838782 AuxI_O10 "Identifies the current status of auxiliary input/output functions that are configured uniquely per application.
00 - Auxiliary channel off
01 - Auxiliary channel on
10 - Error
11 - Not available";
CM_ SG_ 2566838782 AuxI_O11 "Identifies the current status of auxiliary input/output functions that are configured uniquely per application.
00 - Auxiliary channel off
01 - Auxiliary channel on
10 - Error
11 - Not available";
CM_ SG_ 2566838782 AuxI_O12 "Identifies the current status of auxiliary input/output functions that are configured uniquely per application.
00 - Auxiliary channel off
01 - Auxiliary channel on
10 - Error
11 - Not available";
CM_ SG_ 2566838782 AuxI_O05 "Identifies the current status of auxiliary input/output functions that are configured uniquely per application.
00 - Auxiliary channel off
01 - Auxiliary channel on
10 - Error
11 - Not available";
CM_ SG_ 2566838782 AuxI_O06 "Identifies the current status of auxiliary input/output functions that are configured uniquely per application.
00 - Auxiliary channel off
01 - Auxiliary channel on
10 - Error
11 - Not available";
CM_ SG_ 2566838782 AuxI_O07 "Identifies the current status of auxiliary input/output functions that are configured uniquely per application.
00 - Auxiliary channel off
01 - Auxiliary channel on
10 - Error
11 - Not available";
CM_ SG_ 2566838782 AuxI_O08 "Identifies the current status of auxiliary input/output functions that are configured uniquely per application.
00 - Auxiliary channel off
01 - Auxiliary channel on
10 - Error
11 - Not available";
CM_ SG_ 2566838782 AuxI_O01 "Identifies the current status of auxiliary input/output functions that are configured uniquely per application.
00 - Auxiliary channel off
01 - Auxiliary channel on
10 - Error
11 - Not available";
CM_ SG_ 2566838782 AuxI_O02 "Identifies the current status of auxiliary input/output functions that are configured uniquely per application.
00 - Auxiliary channel off
01 - Auxiliary channel on
10 - Error
11 - Not available";
CM_ SG_ 2566838782 AuxI_O03 "Identifies the current status of auxiliary input/output functions that are configured uniquely per application.
00 - Auxiliary channel off
01 - Auxiliary channel on
10 - Error
11 - Not available";
CM_ SG_ 2566838782 AuxI_O04 "Identifies the current status of auxiliary input/output functions that are configured uniquely per application.
00 - Auxiliary channel off
01 - Auxiliary channel on
10 - Error
11 - Not available";
CM_ SG_ 2561146622 AuxI_O45_3868 "Identifies the current status of auxiliary input/output functions that are configured uniquely per application.
00 - Auxiliary channel off
01 - Auxiliary channel on
10 - Error Indicator or Not Used , depending on application
11 - Not Available ...";
CM_ SG_ 2561146622 AuxI_O46_3869 "Identifies the current status of auxiliary input/output functions that are configured uniquely per application.
00 - Auxiliary channel off
01 - Auxiliary channel on
10 - Error Indicator or Not Used , depending on application
11 - Not Available ...";
CM_ SG_ 2561146622 AuxI_O47_3870 "Identifies the current status of auxiliary input/output functions that are configured uniquely per application.
00 - Auxiliary channel off
01 - Auxiliary channel on
10 - Error Indicator or Not Used , depending on application
11 - Not Available ...";
CM_ SG_ 2561146622 AuxI_O48_3871 "Identifies the current status of auxiliary input/output functions that are configured uniquely per application.
00 - Auxiliary channel off
01 - Auxiliary channel on
10 - Error Indicator or Not Used , depending on application
11 - Not Available ...";
CM_ SG_ 2561146622 AuxI_O41_3864 "Identifies the current status of auxiliary input/output functions that are configured uniquely per application.
00 - Auxiliary channel off
01 - Auxiliary channel on
10 - Error Indicator or Not Used , depending on application
11 - Not Available ...";
CM_ SG_ 2561146622 AuxI_O42_3865 "Identifies the current status of auxiliary input/output functions that are configured uniquely per application.
00 - Auxiliary channel off
01 - Auxiliary channel on
10 - Error Indicator or Not Used , depending on application
11 - Not Available ...";
CM_ SG_ 2561146622 AuxI_O43_3866 "Identifies the current status of auxiliary input/output functions that are configured uniquely per application.
00 - Auxiliary channel off
01 - Auxiliary channel on
10 - Error Indicator or Not Used , depending on application
11 - Not Available ...";
CM_ SG_ 2561146622 AuxI_O44_3867 "Identifies the current status of auxiliary input/output functions that are configured uniquely per application.
00 - Auxiliary channel off
01 - Auxiliary channel on
10 - Error Indicator or Not Used , depending on application
11 - Not Available ...";
CM_ SG_ 2561146622 AuxI_O37_3860 "Identifies the current status of auxiliary input/output functions that are configured uniquely per application.
00 - Auxiliary channel off
01 - Auxiliary channel on
10 - Error Indicator or Not Used , depending on application
11 - Not Available ...";
CM_ SG_ 2561146622 AuxI_O38_3861 "Identifies the current status of auxiliary input/output functions that are configured uniquely per application.
00 - Auxiliary channel off
01 - Auxiliary channel on
10 - Error Indicator or Not Used , depending on application
11 - Not Available ...";
CM_ SG_ 2561146622 AuxI_O39_3862 "Identifies the current status of auxiliary input/output functions that are configured uniquely per application.
00 - Auxiliary channel off
01 - Auxiliary channel on
10 - Error Indicator or Not Used , depending on application
11 - Not Available ...";
CM_ SG_ 2561146622 AuxI_O40_3863 "Identifies the current status of auxiliary input/output functions that are configured uniquely per application.
00 - Auxiliary channel off
01 - Auxiliary channel on
10 - Error Indicator or Not Used , depending on application
11 - Not Available ...";
CM_ SG_ 2561146622 AuxI_O33_3856 "Identifies the current status of auxiliary input/output functions that are configured uniquely per application.
00 - Auxiliary channel off
01 - Auxiliary channel on
10 - Error Indicator or Not Used , depending on application
11 - Not Available ...";
CM_ SG_ 2561146622 AuxI_O34_3857 "Identifies the current status of auxiliary input/output functions that are configured uniquely per application.
00 - Auxiliary channel off
01 - Auxiliary channel on
10 - Error Indicator or Not Used , depending on application
11 - Not Available ...";
CM_ SG_ 2561146622 AuxI_O35_3858 "Identifies the current status of auxiliary input/output functions that are configured uniquely per application.
00 - Auxiliary channel off
01 - Auxiliary channel on
10 - Error Indicator or Not Used , depending on application
11 - Not Available ...";
CM_ SG_ 2561146622 AuxI_O36_3859 "Identifies the current status of auxiliary input/output functions that are configured uniquely per application.
00 - Auxiliary channel off
01 - Auxiliary channel on
10 - Error Indicator or Not Used , depending on application
11 - Not Available ...";
CM_ SG_ 2561146622 AuxI_O29_3852 "Identifies the current status of auxiliary input/output functions that are configured uniquely per application.
00 - Auxiliary channel off
01 - Auxiliary channel on
10 - Error Indicator or Not Used , depending on application
11 - Not Available ...";
CM_ SG_ 2561146622 AuxI_O30_3853 "Identifies the current status of auxiliary input/output functions that are configured uniquely per application.
00 - Auxiliary channel off
01 - Auxiliary channel on
10 - Error Indicator or Not Used , depending on application
11 - Not Available ...";
CM_ SG_ 2561146622 AuxI_O31_3854 "Identifies the current status of auxiliary input/output functions that are configured uniquely per application.
00 - Auxiliary channel off
01 - Auxiliary channel on
10 - Error Indicator or Not Used , depending on application
11 - Not Available ...";
CM_ SG_ 2561146622 AuxI_O32_3855 "Identifies the current status of auxiliary input/output functions that are configured uniquely per application.
00 - Auxiliary channel off
01 - Auxiliary channel on
10 - Error Indicator or Not Used , depending on application
11 - Not Available ...";
CM_ SG_ 2561146622 AuxI_O25_3848 "Identifies the current status of auxiliary input/output functions that are configured uniquely per application.
00 - Auxiliary channel off
01 - Auxiliary channel on
10 - Error Indicator or Not Used , depending on application
11 - Not Available ...";
CM_ SG_ 2561146622 AuxI_O26_3849 "Identifies the current status of auxiliary input/output functions that are configured uniquely per application.
00 - Auxiliary channel off
01 - Auxiliary channel on
10 - Error Indicator or Not Used , depending on application
11 - Not Available ...";
CM_ SG_ 2561146622 AuxI_O27_3850 "Identifies the current status of auxiliary input/output functions that are configured uniquely per application.
00 - Auxiliary channel off
01 - Auxiliary channel on
10 - Error Indicator or Not Used , depending on application
11 - Not Available ...";
CM_ SG_ 2561146622 AuxI_O28_3851 "Identifies the current status of auxiliary input/output functions that are configured uniquely per application.
00 - Auxiliary channel off
01 - Auxiliary channel on
10 - Error Indicator or Not Used , depending on application
11 - Not Available ...";
CM_ SG_ 2561146622 AuxI_O21_3844 "Identifies the current status of auxiliary input/output functions that are configured uniquely per application.
00 - Auxiliary channel off
01 - Auxiliary channel on
10 - Error Indicator or Not Used , depending on application
11 - Not Available ...";
CM_ SG_ 2561146622 AuxI_O22_3845 "Identifies the current status of auxiliary input/output functions that are configured uniquely per application.
00 - Auxiliary channel off
01 - Auxiliary channel on
10 - Error Indicator or Not Used , depending on application
11 - Not Available ...";
CM_ SG_ 2561146622 AuxI_O23_3846 "Identifies the current status of auxiliary input/output functions that are configured uniquely per application.
00 - Auxiliary channel off
01 - Auxiliary channel on
10 - Error Indicator or Not Used , depending on application
11 - Not Available ...";
CM_ SG_ 2561146622 AuxI_O24_3847 "Identifies the current status of auxiliary input/output functions that are configured uniquely per application.
00 - Auxiliary channel off
01 - Auxiliary channel on
10 - Error Indicator or Not Used , depending on application
11 - Not Available ...";
CM_ SG_ 2561146622 AuxI_O17_3840 "Identifies the current status of auxiliary input/output functions that are configured uniquely per application.
00 - Auxiliary channel off
01 - Auxiliary channel on
10 - Error Indicator or Not Used , depending on application
11 - Not Available ...";
CM_ SG_ 2561146622 AuxI_O18_3841 "Identifies the current status of auxiliary input/output functions that are configured uniquely per application.
00 - Auxiliary channel off
01 - Auxiliary channel on
10 - Error Indicator or Not Used , depending on application
11 - Not Available ...";
CM_ SG_ 2561146622 AuxI_O19_3842 "Identifies the current status of auxiliary input/output functions that are configured uniquely per application.
00 - Auxiliary channel off
01 - Auxiliary channel on
10 - Error Indicator or Not Used , depending on application
11 - Not Available ...";
CM_ SG_ 2561146622 AuxI_O20_3843 "Identifies the current status of auxiliary input/output functions that are configured uniquely per application.
00 - Auxiliary channel off
01 - Auxiliary channel on
10 - Error Indicator or Not Used , depending on application
11 - Not Available ...";
CM_ SG_ 2561081086 AuxI_O77_3900 "Identifies the current status of auxiliary input/output functions that are configured uniquely per application.
00 - Auxiliary channel off
01 - Auxiliary channel on
10 - Error Indicator or Not Used , depending on application
11 - Not Available ...";
CM_ SG_ 2561081086 AuxI_O78_3901 "Identifies the current status of auxiliary input/output functions that are configured uniquely per application.
00 - Auxiliary channel off
01 - Auxiliary channel on
10 - Error Indicator or Not Used , depending on application
11 - Not Available ...";
CM_ SG_ 2561081086 AuxI_O79_3902 "Identifies the current status of auxiliary input/output functions that are configured uniquely per application.
00 - Auxiliary channel off
01 - Auxiliary channel on
10 - Error Indicator or Not Used , depending on application
11 - Not Available ...";
CM_ SG_ 2561081086 AuxI_O80_3903 "Identifies the current status of auxiliary input/output functions that are configured uniquely per application.
00 - Auxiliary channel off
01 - Auxiliary channel on
10 - Error Indicator or Not Used , depending on application
11 - Not Available ...";
CM_ SG_ 2561081086 AuxI_O73_3896 "Identifies the current status of auxiliary input/output functions that are configured uniquely per application.
00 - Auxiliary channel off
01 - Auxiliary channel on
10 - Error Indicator or Not Used , depending on application
11 - Not Available ...";
CM_ SG_ 2561081086 AuxI_O74_3897 "Identifies the current status of auxiliary input/output functions that are configured uniquely per application.
00 - Auxiliary channel off
01 - Auxiliary channel on
10 - Error Indicator or Not Used , depending on application
11 - Not Available ...";
CM_ SG_ 2561081086 AuxI_O75_3898 "Identifies the current status of auxiliary input/output functions that are configured uniquely per application.
00 - Auxiliary channel off
01 - Auxiliary channel on
10 - Error Indicator or Not Used , depending on application
11 - Not Available ...";
CM_ SG_ 2561081086 AuxI_O76_3899 "Identifies the current status of auxiliary input/output functions that are configured uniquely per application.
00 - Auxiliary channel off
01 - Auxiliary channel on
10 - Error Indicator or Not Used , depending on application
11 - Not Available ...";
CM_ SG_ 2561081086 AuxI_O69_3892 "Identifies the current status of auxiliary input/output functions that are configured uniquely per application.
00 - Auxiliary channel off
01 - Auxiliary channel on
10 - Error Indicator or Not Used , depending on application
11 - Not Available ...";
CM_ SG_ 2561081086 AuxI_O70_3893 "Identifies the current status of auxiliary input/output functions that are configured uniquely per application.
00 - Auxiliary channel off
01 - Auxiliary channel on
10 - Error Indicator or Not Used , depending on application
11 - Not Available ...";
CM_ SG_ 2561081086 AuxI_O71_3894 "Identifies the current status of auxiliary input/output functions that are configured uniquely per application.
00 - Auxiliary channel off
01 - Auxiliary channel on
10 - Error Indicator or Not Used , depending on application
11 - Not Available ...";
CM_ SG_ 2561081086 AuxI_O72_3895 "Identifies the current status of auxiliary input/output functions that are configured uniquely per application.
00 - Auxiliary channel off
01 - Auxiliary channel on
10 - Error Indicator or Not Used , depending on application
11 - Not Available ...";
CM_ SG_ 2561081086 AuxI_O65_3888 "Identifies the current status of auxiliary input/output functions that are configured uniquely per application.
00 - Auxiliary channel off
01 - Auxiliary channel on
10 - Error Indicator or Not Used , depending on application
11 - Not Available ...";
CM_ SG_ 2561081086 AuxI_O66_3889 "Identifies the current status of auxiliary input/output functions that are configured uniquely per application.
00 - Auxiliary channel off
01 - Auxiliary channel on
10 - Error Indicator or Not Used , depending on application
11 - Not Available ...";
CM_ SG_ 2561081086 AuxI_O67_3890 "Identifies the current status of auxiliary input/output functions that are configured uniquely per application.
00 - Auxiliary channel off
01 - Auxiliary channel on
10 - Error Indicator or Not Used , depending on application
11 - Not Available ...";
CM_ SG_ 2561081086 AuxI_O68_3891 "Identifies the current status of auxiliary input/output functions that are configured uniquely per application.
00 - Auxiliary channel off
01 - Auxiliary channel on
10 - Error Indicator or Not Used , depending on application
11 - Not Available ...";
CM_ SG_ 2561081086 AuxI_O61_3884 "Identifies the current status of auxiliary input/output functions that are configured uniquely per application.
00 - Auxiliary channel off
01 - Auxiliary channel on
10 - Error Indicator or Not Used , depending on application
11 - Not Available ...";
CM_ SG_ 2561081086 AuxI_O62_3885 "Identifies the current status of auxiliary input/output functions that are configured uniquely per application.
00 - Auxiliary channel off
01 - Auxiliary channel on
10 - Error Indicator or Not Used , depending on application
11 - Not Available ...";
CM_ SG_ 2561081086 AuxI_O63_3886 "Identifies the current status of auxiliary input/output functions that are configured uniquely per application.
00 - Auxiliary channel off
01 - Auxiliary channel on
10 - Error Indicator or Not Used , depending on application
11 - Not Available ...";
CM_ SG_ 2561081086 AuxI_O64_3887 "Identifies the current status of auxiliary input/output functions that are configured uniquely per application.
00 - Auxiliary channel off
01 - Auxiliary channel on
10 - Error Indicator or Not Used , depending on application
11 - Not Available ...";
CM_ SG_ 2561081086 AuxI_O57_3880 "Identifies the current status of auxiliary input/output functions that are configured uniquely per application.
00 - Auxiliary channel off
01 - Auxiliary channel on
10 - Error Indicator or Not Used , depending on application
11 - Not Available ...";
CM_ SG_ 2561081086 AuxI_O58_3881 "Identifies the current status of auxiliary input/output functions that are configured uniquely per application.
00 - Auxiliary channel off
01 - Auxiliary channel on
10 - Error Indicator or Not Used , depending on application
11 - Not Available ...";
CM_ SG_ 2561081086 AuxI_O59_3882 "Identifies the current status of auxiliary input/output functions that are configured uniquely per application.
00 - Auxiliary channel off
01 - Auxiliary channel on
10 - Error Indicator or Not Used , depending on application
11 - Not Available ...";
CM_ SG_ 2561081086 AuxI_O60_3883 "Identifies the current status of auxiliary input/output functions that are configured uniquely per application.
00 - Auxiliary channel off
01 - Auxiliary channel on
10 - Error Indicator or Not Used , depending on application
11 - Not Available ...";
CM_ SG_ 2561081086 AuxI_O53_3876 "Identifies the current status of auxiliary input/output functions that are configured uniquely per application.
00 - Auxiliary channel off
01 - Auxiliary channel on
10 - Error Indicator or Not Used , depending on application
11 - Not Available ...";
CM_ SG_ 2561081086 AuxI_O54_3877 "Identifies the current status of auxiliary input/output functions that are configured uniquely per application.
00 - Auxiliary channel off
01 - Auxiliary channel on
10 - Error Indicator or Not Used , depending on application
11 - Not Available ...";
CM_ SG_ 2561081086 AuxI_O55_3878 "Identifies the current status of auxiliary input/output functions that are configured uniquely per application.
00 - Auxiliary channel off
01 - Auxiliary channel on
10 - Error Indicator or Not Used , depending on application
11 - Not Available ...";
CM_ SG_ 2561081086 AuxI_O56_3879 "Identifies the current status of auxiliary input/output functions that are configured uniquely per application.
00 - Auxiliary channel off
01 - Auxiliary channel on
10 - Error Indicator or Not Used , depending on application
11 - Not Available ...";
CM_ SG_ 2561081086 AuxI_O49_3872 "Identifies the current status of auxiliary input/output functions that are configured uniquely per application.
00 - Auxiliary channel off
01 - Auxiliary channel on
10 - Error Indicator or Not Used , depending on application
11 - Not Available ...";
CM_ SG_ 2561081086 AuxI_O50_3873 "Identifies the current status of auxiliary input/output functions that are configured uniquely per application.
00 - Auxiliary channel off
01 - Auxiliary channel on
10 - Error Indicator or Not Used , depending on application
11 - Not Available ...";
CM_ SG_ 2561081086 AuxI_O51_3874 "Identifies the current status of auxiliary input/output functions that are configured uniquely per application.
00 - Auxiliary channel off
01 - Auxiliary channel on
10 - Error Indicator or Not Used , depending on application
11 - Not Available ...";
CM_ SG_ 2561081086 AuxI_O52_3875 "Identifies the current status of auxiliary input/output functions that are configured uniquely per application.
00 - Auxiliary channel off
01 - Auxiliary channel on
10 - Error Indicator or Not Used , depending on application
11 - Not Available ...";
CM_ SG_ 2561015550 AuxI_O109_3932 "Identifies the current status of auxiliary input/output functions that are configured uniquely per application.
00 - Auxiliary channel off
01 - Auxiliary channel on
10 - Error Indicator or Not Used , depending on application
11 - Not Available ...";
CM_ SG_ 2561015550 AuxI_O110_3933 "Identifies the current status of auxiliary input/output functions that are configured uniquely per application.
00 - Auxiliary channel off
01 - Auxiliary channel on
10 - Error Indicator or Not Used , depending on application
11 - Not Available ...";
CM_ SG_ 2561015550 AuxI_O111_3934 "Identifies the current status of auxiliary input/output functions that are configured uniquely per application.
00 - Auxiliary channel off
01 - Auxiliary channel on
10 - Error Indicator or Not Used , depending on application
11 - Not Available ...";
CM_ SG_ 2561015550 AuxI_O112_3935 "Identifies the current status of auxiliary input/output functions that are configured uniquely per application.
00 - Auxiliary channel off
01 - Auxiliary channel on
10 - Error Indicator or Not Used , depending on application
11 - Not Available ...";
CM_ SG_ 2561015550 AuxI_O105_3928 "Identifies the current status of auxiliary input/output functions that are configured uniquely per application.
00 - Auxiliary channel off
01 - Auxiliary channel on
10 - Error Indicator or Not Used , depending on application
11 - Not Available ...";
CM_ SG_ 2561015550 AuxI_O106_3929 "Identifies the current status of auxiliary input/output functions that are configured uniquely per application.
00 - Auxiliary channel off
01 - Auxiliary channel on
10 - Error Indicator or Not Used , depending on application
11 - Not Available ...";
CM_ SG_ 2561015550 AuxI_O107_3930 "Identifies the current status of auxiliary input/output functions that are configured uniquely per application.
00 - Auxiliary channel off
01 - Auxiliary channel on
10 - Error Indicator or Not Used , depending on application
11 - Not Available ...";
CM_ SG_ 2561015550 AuxI_O108_3931 "Identifies the current status of auxiliary input/output functions that are configured uniquely per application.
00 - Auxiliary channel off
01 - Auxiliary channel on
10 - Error Indicator or Not Used , depending on application
11 - Not Available ...";
CM_ SG_ 2561015550 AuxI_O101_3924 "Identifies the current status of auxiliary input/output functions that are configured uniquely per application.
00 - Auxiliary channel off
01 - Auxiliary channel on
10 - Error Indicator or Not Used , depending on application
11 - Not Available ...";
CM_ SG_ 2561015550 AuxI_O102_3925 "Identifies the current status of auxiliary input/output functions that are configured uniquely per application.
00 - Auxiliary channel off
01 - Auxiliary channel on
10 - Error Indicator or Not Used , depending on application
11 - Not Available ...";
CM_ SG_ 2561015550 AuxI_O103_3926 "Identifies the current status of auxiliary input/output functions that are configured uniquely per application.
00 - Auxiliary channel off
01 - Auxiliary channel on
10 - Error Indicator or Not Used , depending on application
11 - Not Available ...";
CM_ SG_ 2561015550 AuxI_O104_3927 "Identifies the current status of auxiliary input/output functions that are configured uniquely per application.
00 - Auxiliary channel off
01 - Auxiliary channel on
10 - Error Indicator or Not Used , depending on application
11 - Not Available ...";
CM_ SG_ 2561015550 AuxI_O97_3920 "Identifies the current status of auxiliary input/output functions that are configured uniquely per application.
00 - Auxiliary channel off
01 - Auxiliary channel on
10 - Error Indicator or Not Used , depending on application
11 - Not Available ...";
CM_ SG_ 2561015550 AuxI_O98_3921 "Identifies the current status of auxiliary input/output functions that are configured uniquely per application.
00 - Auxiliary channel off
01 - Auxiliary channel on
10 - Error Indicator or Not Used , depending on application
11 - Not Available ...";
CM_ SG_ 2561015550 AuxI_O99_3922 "Identifies the current status of auxiliary input/output functions that are configured uniquely per application.
00 - Auxiliary channel off
01 - Auxiliary channel on
10 - Error Indicator or Not Used , depending on application
11 - Not Available ...";
CM_ SG_ 2561015550 AuxI_O100_3923 "Identifies the current status of auxiliary input/output functions that are configured uniquely per application.
00 - Auxiliary channel off
01 - Auxiliary channel on
10 - Error Indicator or Not Used , depending on application
11 - Not Available ...";
CM_ SG_ 2561015550 AuxI_O93_3916 "Identifies the current status of auxiliary input/output functions that are configured uniquely per application.
00 - Auxiliary channel off
01 - Auxiliary channel on
10 - Error Indicator or Not Used , depending on application
11 - Not Available ...";
CM_ SG_ 2561015550 AuxI_O94_3917 "Identifies the current status of auxiliary input/output functions that are configured uniquely per application.
00 - Auxiliary channel off
01 - Auxiliary channel on
10 - Error Indicator or Not Used , depending on application
11 - Not Available ...";
CM_ SG_ 2561015550 AuxI_O95_3918 "Identifies the current status of auxiliary input/output functions that are configured uniquely per application.
00 - Auxiliary channel off
01 - Auxiliary channel on
10 - Error Indicator or Not Used , depending on application
11 - Not Available ...";
CM_ SG_ 2561015550 AuxI_O96_3919 "Identifies the current status of auxiliary input/output functions that are configured uniquely per application.
00 - Auxiliary channel off
01 - Auxiliary channel on
10 - Error Indicator or Not Used , depending on application
11 - Not Available ...";
CM_ SG_ 2561015550 AuxI_O89_3912 "Identifies the current status of auxiliary input/output functions that are configured uniquely per application.
00 - Auxiliary channel off
01 - Auxiliary channel on
10 - Error Indicator or Not Used , depending on application
11 - Not Available ...";
CM_ SG_ 2561015550 AuxI_O90_3913 "Identifies the current status of auxiliary input/output functions that are configured uniquely per application.
00 - Auxiliary channel off
01 - Auxiliary channel on
10 - Error Indicator or Not Used , depending on application
11 - Not Available ...";
CM_ SG_ 2561015550 AuxI_O91_3914 "Identifies the current status of auxiliary input/output functions that are configured uniquely per application.
00 - Auxiliary channel off
01 - Auxiliary channel on
10 - Error Indicator or Not Used , depending on application
11 - Not Available ...";
CM_ SG_ 2561015550 AuxI_O92_3915 "Identifies the current status of auxiliary input/output functions that are configured uniquely per application.
00 - Auxiliary channel off
01 - Auxiliary channel on
10 - Error Indicator or Not Used , depending on application
11 - Not Available ...";
CM_ SG_ 2561015550 AuxI_O85_3908 "Identifies the current status of auxiliary input/output functions that are configured uniquely per application.
00 - Auxiliary channel off
01 - Auxiliary channel on
10 - Error Indicator or Not Used , depending on application
11 - Not Available ...";
CM_ SG_ 2561015550 AuxI_O86_3909 "Identifies the current status of auxiliary input/output functions that are configured uniquely per application.
00 - Auxiliary channel off
01 - Auxiliary channel on
10 - Error Indicator or Not Used , depending on application
11 - Not Available ...";
CM_ SG_ 2561015550 AuxI_O87_3910 "Identifies the current status of auxiliary input/output functions that are configured uniquely per application.
00 - Auxiliary channel off
01 - Auxiliary channel on
10 - Error Indicator or Not Used , depending on application
11 - Not Available ...";
CM_ SG_ 2561015550 AuxI_O88_3911 "Identifies the current status of auxiliary input/output functions that are configured uniquely per application.
00 - Auxiliary channel off
01 - Auxiliary channel on
10 - Error Indicator or Not Used , depending on application
11 - Not Available ...";
CM_ SG_ 2561015550 AuxI_O81_3904 "Identifies the current status of auxiliary input/output functions that are configured uniquely per application.
00 - Auxiliary channel off
01 - Auxiliary channel on
10 - Error Indicator or Not Used , depending on application
11 - Not Available ...";
CM_ SG_ 2561015550 AuxI_O82_3905 "Identifies the current status of auxiliary input/output functions that are configured uniquely per application.
00 - Auxiliary channel off
01 - Auxiliary channel on
10 - Error Indicator or Not Used , depending on application
11 - Not Available ...";
CM_ SG_ 2561015550 AuxI_O83_3906 "Identifies the current status of auxiliary input/output functions that are configured uniquely per application.
00 - Auxiliary channel off
01 - Auxiliary channel on
10 - Error Indicator or Not Used , depending on application
11 - Not Available ...";
CM_ SG_ 2561015550 AuxI_O84_3907 "Identifies the current status of auxiliary input/output functions that are configured uniquely per application.
00 - Auxiliary channel off
01 - Auxiliary channel on
10 - Error Indicator or Not Used , depending on application
11 - Not Available ...";
CM_ SG_ 2566746622 TrailerBrakeStrokeAxle5Right "Brake stroke status for right brake actuator on trailer axle 5.
000 - OK (Normal operation)
001 - Non-functioning
010 - Overstroke
011 - Dragging brake
100 - Reserved
101 - Reserved
110 - Sensor error
111 - Not available";
CM_ SG_ 2566746622 TrailerBrakeStrokeAxle5Left "Brake stroke status for left brake actuator on trailer axle 5.
000 - OK (Normal operation)
001 - Non-functioning
010 - Overstroke
011 - Dragging brake
100 - Reserved
101 - Reserved
110 - Sensor error
111 - Not available";
CM_ SG_ 2566746622 TrailerBrakeStrokeAxle4Right "Brake stroke status for right brake actuator on trailer axle 4.
000 - OK (Normal operation)
001 - Non-functioning
010 - Overstroke
011 - Dragging brake
100 - Reserved
101 - Reserved
110 - Sensor error
111 - Not available";
CM_ SG_ 2566746622 TrailerBrakeStrokeAxle4Left "Brake stroke status for left brake actuator on trailer axle 4.
000 - OK (Normal operation)
001 - Non-functioning
010 - Overstroke
011 - Dragging brake
100 - Reserved
101 - Reserved
110 - Sensor error
111 - Not available";
CM_ SG_ 2566746622 TrailerBrakeStrokeAxle3Right "Brake stroke status for right brake actuator on trailer axle 3.
000 - OK (Normal operation)
001 - Non-functioning
010 - Overstroke
011 - Dragging brake
100 - Reserved
101 - Reserved
110 - Sensor error
111 - Not available";
CM_ SG_ 2566746622 TrailerBrakeStrokeAxle3Left "Brake stroke status for left brake actuator on trailer axle 3.
000 - OK (Normal operation)
001 - Non-functioning
010 - Overstroke
011 - Dragging brake
100 - Reserved
101 - Reserved
110 - Sensor error
111 - Not available";
CM_ SG_ 2566746622 TrailerBrakeStrokeAxle2Right "Brake stroke status for right brake actuator on trailer axle 2.
000 - OK (Normal operation)
001 - Non-functioning
010 - Overstroke
011 - Dragging brake
100 - Reserved
101 - Reserved
110 - Sensor error
111 - Not available";
CM_ SG_ 2566746622 TrailerBrakeStrokeAxle2Left "Brake stroke status for left brake actuator on trailer axle 2.
000 - OK (Normal operation)
001 - Non-functioning
010 - Overstroke
011 - Dragging brake
100 - Reserved
101 - Reserved
110 - Sensor error
111 - Not available";
CM_ SG_ 2566746622 TrailerBrakeStrokeAxle1Right "Brake stroke status for right brake actuator on trailer axle 1.
000 - OK (Normal operation)
001 - Non-functioning
010 - Overstroke
011 - Dragging brake
100 - Reserved
101 - Reserved
110 - Sensor error
111 - Not available";
CM_ SG_ 2566746622 TrailerBrakeStrokeAxle1Left "Brake stroke status for left brake actuator on trailerr axle 1.
000 - OK (Normal operation)
001 - Non-functioning
010 - Overstroke
011 - Dragging brake
100 - Reserved
101 - Reserved
110 - Sensor error
111 - Not available";
CM_ SG_ 2566746622 TractorBrakeStrokeAxle5Right "Brake stroke status for right brake actuator on tractor axle 5.
000 - OK (Normal operation)
001 - Non-functioning
010 - Overstroke
011 - Dragging brake
100 - Reserved
101 - Reserved
110 - Sensor error
111 - Not available";
CM_ SG_ 2566746622 TractorBrakeStrokeAxle5Left "Brake stroke status for left brake actuator on tractor axle 5.
000 - OK (Normal operation)
001 - Non-functioning
010 - Overstroke
011 - Dragging brake
100 - Reserved
101 - Reserved
110 - Sensor error
111 - Not available";
CM_ SG_ 2566746622 TractorBrakeStrokeAxle4Right "Brake stroke status for right brake actuator on tractor axle 4.
000 - OK (Normal operation)
001 - Non-functioning
010 - Overstroke
011 - Dragging brake
100 - Reserved
101 - Reserved
110 - Sensor error
111 - Not available";
CM_ SG_ 2566746622 TractorBrakeStrokeAxle4Left "Brake stroke status for left brake actuator on tractor axle 4.
000 - OK (Normal operation)
001 - Non-functioning
010 - Overstroke
011 - Dragging brake
100 - Reserved
101 - Reserved
110 - Sensor error
111 - Not available";
CM_ SG_ 2566746622 TractorBrakeStrokeAxle3Right "Brake stroke status for right brake actuator on tractor axle 3.
000 - OK (Normal operation)
001 - Non-functioning
010 - Overstroke
011 - Dragging brake
100 - Reserved
101 - Reserved
110 - Sensor error
111 - Not available";
CM_ SG_ 2566746622 TractorBrakeStrokeAxle3Left "Brake stroke status for left brake actuator on tractor axle 3.
000 - OK (Normal operation)
001 - Non-functioning
010 - Overstroke
011 - Dragging brake
100 - Reserved
101 - Reserved
110 - Sensor error
111 - Not available";
CM_ SG_ 2566746622 TractorBrakeStrokeAxle2Right "Brake stroke status for right brake actuator on tractor axle 2.
000 - OK (Normal operation)
001 - Non-functioning
010 - Overstroke
011 - Dragging brake
100 - Reserved
101 - Reserved
110 - Sensor error
111 - Not available";
CM_ SG_ 2566746622 TractorBrakeStrokeAxle2Left "Brake stroke status for left brake actuator on tractor axle 2.
000 - OK (Normal operation)
001 - Non-functioning
010 - Overstroke
011 - Dragging brake
100 - Reserved
101 - Reserved
110 - Sensor error
111 - Not available";
CM_ SG_ 2566746622 TractorBrakeStrokeAxle1Right "Brake stroke status for right brake actuator on tractor axle 1.
000 - OK (Normal operation)
001 - Non-functioning
010 - Overstroke
011 - Dragging brake
100 - Reserved
101 - Reserved
110 - Sensor error
111 - Not available";
CM_ SG_ 2566746622 TractorBrakeStrokeAxle1Left "Brake stroke status for left brake actuator on tractor axle 1.
000 - OK (Normal operation)
001 - Non-functioning
010 - Overstroke
011 - Dragging brake
100 - Reserved
101 - Reserved
110 - Sensor error
111 - Not available";
CM_ SG_ 2566845950 RoadSurfaceTemp "Indicated temperature of road surface over which vehicle is operating.";
CM_ SG_ 2566845950 EngAirIntakeTemp "Temperature of air entering vehicle air induction system.";
CM_ SG_ 2566845950 AmbientAirTemp "Temperature of air surrounding vehicle.";
CM_ SG_ 2566845950 CabInteriorTemp "Temperature of air inside the part of the vehicle that encloses the driver and vehicle operating controls.
Note: See also SPN 1691.  SPN 1662 is an additional diagnostic SPN associated with cab temperature.";
CM_ SG_ 2566845950 BarometricPress "Absolute air pressure of the atmosphere.";
CM_ SG_ 2566840062 EngAirStopPress "Gage pressure of air in an engine stopping system that utilizes compressed air to provide the force required to stop the crankshaft. Engine stopping air is typically used for emergency engine stopping.";
CM_ SG_ 2566840062 EngAirStartPress6831 "Gage pressure of air in an engine starting system that utilizes compressed air to provide the force required to rotate the crankshaft.
See SPN 82 for higher resolution.";
CM_ SG_ 2566840062 EngAirStartPress "Gage pressure of air in an engine starting system that utilizes compressed air to provide the force required to rotate the crankshaft.";
CM_ SG_ 2566827774 AirCompressorStatus "Indicates whether the air compressor is actively compressing air.
00     Compressor not active
01     Compressor active
10     Error indicator
11     Not available";
CM_ SG_ 2566827774 AirSuspensionSupplyPress "The pneumatic pressure in the circuit for the electronically controlled air suspension system.";
CM_ SG_ 2566827774 AuxEquipmentSupplyPress "The pneumatic pressure in the auxiliary circuit.";
CM_ SG_ 2566827774 PowertrainCircuitAirSupplyPress "Supply pressure to carry the pressure information for the powertrain circuit. This circuit typically would feed powertrain components such as throttles, gearbox actuators and aftertreatment actuators for EGR and SCR systems.";
CM_ SG_ 2566827774 ServiceBrakeCircuit2AirPress "The pneumatic pressure in the secondary service brake circuit or reservoir, supplying the front axle.";
CM_ SG_ 2566827774 ServiceBrakeCircuit1AirPress "The pneumatic pressure in the primary service brake circuit or reservoir, supplying the rear axle.";
CM_ SG_ 2566827774 ParkingAnd_orTrailerAirPress "The pneumatic pressure in the circuit or reservoir for the parking brake and/or the trailer supply.";
CM_ SG_ 2566827774 PneumaticSupplyPress "The pneumatic pressure in the main reservoir, sometimes referred to as the wet tank.";
CM_ SG_ 2566846974 SteerAxleLubePress "The steering axle lubricant pressure.";
CM_ SG_ 2566846974 SteerAxleTemp "Temperature of lubricant in steering axle.";
CM_ SG_ 2566846974 DriveAxleLubePress "The drive axle lubricant pressure with location determined by Drive Axle Location (SPN 930).";
CM_ SG_ 2566846974 DriveAxleTemp "Temperature of axle lubricant in drive axle.";
CM_ SG_ 2566846974 DriveAxleLiftAirPress "Gage pressure of air in system that utilizes compressed air to provide force between axle and frame.";
CM_ SG_ 2566846974 DriveAxleLocation "To identify to which of several similar devices (such as tires or fuel tanks) the information applies.
The low order 4 bits represent a position number, counting left to right when facing in the direction of normal vehicle travel (forward).
The ...";
CM_ SG_ 2633935614 EngGsMssFlwSnsrFuelingCorrection "The amount of fuel the Gas Mass Flow Rate Sensor is sensing should be added or subtracted compared to the maximum amount of fuel the control system allows the sensor to add or subtract.";
CM_ SG_ 2633935614 GsFlInjctonPulseCorrectionFactor "A correction to the gaseous fuel injection pulse (expressed in msec) represented as a percentage.  100% means no correction, higher values indicate increased pulse time, lower values indicate decreased pulse time.";
CM_ SG_ 2633935614 EngTurboWastegateValvePos "The position of the turbocharger wastegate valve (not the electronic wastegate control valve).";
CM_ SG_ 2633935614 EngDesiredAbsIntakeManifoldPress "The desired absolute intake manifold pressure (turbo boost limit) of the engine.";
CM_ SG_ 2633935614 EngGasFuelCorrectionFactor "A correction to a predefined gaseous fuel energy (expressed in energy per unit volume) represented as a percentage.  The actual fuel energy used to control the engine is the product of the gaseous fuel correction factor and the energy of the gas.";
CM_ SG_ 2566803966 RequestedACCDistanceMode "The Requested Distance Control Mode to the ACC system from the operators interface.
The ACC Set Distance Mode (SPN 1589) indicates the selected Distance Control Mode for the ACC system. This parameter is the driver requested setting for this.
000 ...";
CM_ SG_ 2566803966 ACCUsageDemand "This parameter indicates the drivers demand to activate or deactivate ACC keeping distance control.
00 driver demand for not using ACC distance keeping control
01 driver demand for using ACC distance keeping control
10 reserved
11 don't care";
CM_ SG_ 2432593918 ForwardCollisionWarning "This parameter indicates if a collision is imminent and strong driver reaction either by braking hard or by an avoidance maneuver are imperative to prevent a collision.
00 No warning
01 Collision is imminent
10 Error indicator
11 not available
...";
CM_ SG_ 2432593918 ACCDistanceAlertSignal "Signal to indicate to the operator that the ACC system is not able to maintain the distance to the target. Example: Target stopping rapidly. This signal may be used to activate warning sounds or indicators.
00 ACC DAS Not Active
01 ACC DAS Active
...";
CM_ SG_ 2432593918 ACCSystemShutoffWarning "Signal to warn the driver of system deactivation due to non-driver actions. Example: Attempting to control vehicle speed below or above limits of ACC. This signal may be used to activate warning sounds or indicators.
00 ACC SSOW Not Active
01 ACC ...";
CM_ SG_ 2432593918 ACCTargetDetected "Signal to indicate to the driver that the ACC system has detected a target.
00 No targets detected
01 Target detected
10 Reserved
11 Take no action";
CM_ SG_ 2432593918 RoadCurvature "Estimated value of the current road curvature for use by the adaptive cruise control system.  Positive values are used for left curves.  Curvature is the inverse of the radius and is zero for straight roads.";
CM_ SG_ 2432593918 AdptiveCruiseCtrlSetDistanceMode "Selected distance mode for adaptive cruise control.
000 ACC Distance mode #1 (largest distance)
001 ACC Distance mode #2
010 ACC Distance mode #3
011 ACC Distance mode #4
100 ACC Distance mode #5 (shortest distance)
101 Conventional cruise ...";
CM_ SG_ 2432593918 AdaptiveCruiseCtrlMode "This parameter is used to indicate the current state, or mode, of operation by the Adaptive Cruise Control (ACC) device. The states characterize independent system states (e.g., it is not possible to express distance control active and overtake mode ...";
CM_ SG_ 2432593918 AdaptiveCruiseCtrlSetSpeed "Value of the desired (chosen) velocity of the adaptive cruise control system.";
CM_ SG_ 2432593918 DistanceToForwardVehicle "Distance to the preceding vehicle situated within 250 m in the same lane and moving in the same direction.";
CM_ SG_ 2432593918 SpeedOfForwardVehicle "Absolute velocity of the preceding vehicle situated within 250 m in the same lane and moving in the same direction.";
CM_ SG_ 2633935102 ArticulationAngle "Angle of deflection of an articulated transit vehicle (rotation angle about the vehicles z-axis). A right turn (clockwise) is indicated with a positive angle and a left turn is indicated with a negative angle.  This parameter is defined according to ...";
CM_ SG_ 2633927934 RelativeHumidity "Measures humidity of combustion air prior to entry into turbocharger";
CM_ SG_ 2633927934 AuxLevel "Level measured by a sensor.";
CM_ SG_ 2633927934 AuxPress2 "Pressure measured by auxiliary pressure sensor #2.  Not to be used in place of existing SPNs.";
CM_ SG_ 2633927934 AuxPress1 "Pressure measured by auxiliary pressure sensor #1.  Not to be used in place of existing SPNs.";
CM_ SG_ 2633927934 AuxTemp2 "Temperature measured by auxiliary temperature sensor #2.  Not to be used in place of existing SPNs.";
CM_ SG_ 2633927934 AuxTemp1 "Temperature measured by auxiliary temperature sensor #1.  Not to be used in place of existing SPNs.";
CM_ SG_ 2566847998 LNGVaporizerCoolantOutletTemp "Temperature of coolant at outlet of liquified natural gas vaporizer. This parameter is also used to determine if coolant has reached freezing temperature.";
CM_ SG_ 2566847998 EngGasFuelVentPress "Gaseous fuel pressure through a vent pipe.";
CM_ SG_ 2566847998 EngBlowerBypassValvePos "Relative position of the blower bypass valve.";
CM_ SG_ 2566847998 EngGasSupplyPress "Gage pressure of gaseous fuel supply to fuel metering device.";
CM_ SG_ 2565406462 ControlByte_2541 "Indicates the acknowledgement response.
0 - Positive Acknowledgment (ACK)
1 - Negative Acknowledgment (NACK)
2 - Access Denied (PGN supported but access denied)
3 - Cannot Respond (PGN supported but ECU cannot respond now) cannot respond with ...";
CM_ SG_ 2565406462 ParameterGroupNumber_2547 "PGN which is requested by the Request message";
CM_ SG_ 2565406462 GroupFunctionValue "Group Function of PGN being acknowledged. This field identifies for a device the specific group function of a PGN being acknowledged or declined.  This field is not used if the PGN being acknowledged or declined is not a group function PGN.";
CM_ SG_ 2566803198 Status2OfDoors "Composite indication of all bus door statuses. Enabled means the bus doors are able to be automatically opened or closed.
00   all bus doors are disabled
01   at least 1 bus door enabled
10   error
11   not available";
CM_ SG_ 2566803198 Ramp_WheelChairLiftPos "Signal which indicates the actual position of the ramp / wheel chair lift.
00 Inside bus
01 Outside bus
10 Error
11 Not available";
CM_ SG_ 2566803198 PosOfDoors "Signal which indicates the actual position of the doors.
0000 At least 1 door is open
0001 Closing last door
0010 All doors closed
0011-1101 Not defined
1110 Error
1111 Not available";
CM_ SG_ 2565870334 FifthWheelRollWarnIndcr_3317 "Indicates to the vehicle operator that the roll moment has exceeded a preset limit.
00 Limit not exceeded
01 Limit exceeded
10 error
11 Not Available";
CM_ SG_ 2565870334 FifthWheelRollMoment_3310 "Fifth wheel roll moment force - If the moment is positive, the trailer is rolling clockwise relative to the normal vehicle forward motion.";
CM_ SG_ 2565870334 FifthWheelDrawbarForce_3309 "Fifth wheel drawbar force, with the trailer held stationary a positive force is generated by the vehicle pulling forward.";
CM_ SG_ 2565870334 FifthWheelVerticalForce_3308 "The amount of load being applied to the fifth wheel by the trailer. Zero load is indicated without a trailer.";
CM_ SG_ 2566762238 FifthWheelSliderLockIndicator "Indicates to vehicle operator that the fifth wheel slider is in position and locked.
00 Not Locked
01 Locked
10 Error
11 Not Available";
CM_ SG_ 2566762238 FifthWheelSliderPos "Slider position measurement. Zero equals fully back position, that is, the farthest to the rear of the vehicle.";
CM_ SG_ 2566762238 FfthWhlLockCoupleStatusIndicator "Indicates results of coupling operation to the vehicle operator. For incomplete couples further information can be obtained from the fifth wheel error status SPN.
00   Incomplete or bad couple, truck should not be moved
01   Successful couple ...";
CM_ SG_ 2566762238 FfthWhlLckReadyToCoupleIndicator "Indicates to the vehicle operator that the fifth wheel lock is open and ready to couple.
00   Lock not open, not ready to couple
01   Lock open, ready to couple
10   Error
11   Not Available";
CM_ SG_ 2566762238 FifthWheelErrorStatus "Fifth wheel error state which conveys information when coupling status is incomplete or bad.
0000    0 - Improper Couple
0001    1 - Locks Closed / No Kingpin at Startup
0010    2 - Kingpin / Locks Open at Startup
0011    3 - Not Used
0100    4 ...";
CM_ SG_ 2364543998 RollPitchMeasurementLatency_3327 "The estimated measurement latency of the measurement.  NOTE: This is only the sensor latency and does not include any additional latencies that might exist because of the CAN Bus or overall system implementation.
Latency is the time from sensor ...";
CM_ SG_ 2364543998 PitchAndRollCompensated_3326 "Compensated mode for the pitch and roll measurements.  Compensation is the use of multiple sensors together to enhance the output of pitch and roll measurements.
00 - Compensation Off
01 - Compensation On
10 - Error
11 - Not Available";
CM_ SG_ 2364543998 PitchRateFigureOfMerit_3325 "Figure of merit for the pitch rate measurement.
00 - Pitch rate fully functional.  Data is within sensor specification.
01 - Pitch rate degraded.  Data is suspect due to environmental conditions.
10 - Error
11 - Not available";
CM_ SG_ 2364543998 RollAngleFigureOfMerit_3324 "Figure of merit for roll angle measurement.
00 - Roll angle fully functional.  Data is within sensor specification.
01 - Roll angle degraded.  Data is suspect due to environmental conditions.
10 - Error
11 - Not available";
CM_ SG_ 2364543998 PitchAngleFigureOfMerit_3323 "Figure of merit for pitch angle measurement.
00 - Pitch angle fully functional.  Data is within sensor specification.
01 - Pitch angle degraded.  Data is suspect due to environmental conditions.
10 - Error
11 - Not available";
CM_ SG_ 2364543998 PitchRate_3322 "Pitch rate is the rate-of-change of the pitch angle over time, where the pitch angle vector is in the direction of travel of the vehicle. The pitch rate for increasing ascent over time is reported with a positive value. This parameter is defined ...";
CM_ SG_ 2364543998 RollAngle_3319 "The angle between the vehicle y-axis and the ground plane (i.e. rotation about the X-axis).  The roll angle for a roll to the right is reported with a positive value. Roll angle is the same for both Z-Down and Z-Up axis systems, since both systems ...";
CM_ SG_ 2364543998 PitchAngle_3318 "The angle between the vehicle x-axis and the ground plane (i.e. rotation about the vehicle Y-axis).  The pitch angle for an angle of ascent is reported with a positive value. This parameter is defined according to a Z-Down axis system and the sign ...";
CM_ SG_ 2566846718 TransOilLevel1MeasurementStatus "Measurement status for the first instance of a transmission oil level indicator.  Indicates if conditions are acceptable to obtain a valid transmission oil level measurement as conveyed in SPN 124 Transmission Oil Level or SPN 3027 Transmission Oil ...";
CM_ SG_ 2566846718 TransOilLevel1CountdownTimer "Countdown timer for the first instance of a transmission oil level indicator.  Once all vehicle conditions (such as vehicle stopped, etc) are met, some transmissions may require a ‘settling time’ to allow the fluid level to normalize.  This ...";
CM_ SG_ 2566846718 TransOilLevel1High_Low "First instance of a transmission oil level indicator. Conveys the amount of current volume of transmission sump oil compared to recommended volume. Positive values indicate overfill. Zero means the transmission fluild is filled to the recommended ...";
CM_ SG_ 2566846718 TransOilTemp1 "First instance of transmission lubricant temperature.";
CM_ SG_ 2566846718 TransOilPress "Gage pressure of lubrication fluid in transmission, measured after pump.";
CM_ SG_ 2566846718 TransFilterDiffPress "Change in transmission fluid pressure, measured after the filter, due to accumulation of solid or semisolid material on or in the filter.";
CM_ SG_ 2566846718 TransOilLevel1 "First instance of a transmission oil level indicator. Conveys the ratio of volume of transmission sump oil to recommended volume.";
CM_ SG_ 2566846718 ClutchPress "Gage pressure of oil within a wet clutch.";
CM_ SG_ 2566846462 KeyswitchBatteryPotential "Battery potential measured at the input of the electronic control unit supplied through a key switch or similar switching device.";
CM_ SG_ 2566846462 BatteryPotential_PowerInput1 "This parameter measures the first source of battery potential as measured at the input of the ECU/actuator etc. coming from one or more batteries, irrespective of the distance between the component and the battery.  This SPN is also used when ECUs ...";
CM_ SG_ 2566846462 ChargingSystemPotential "Electrical potential measured at the charging system output.  The charging system may be any device charging the batteries.  This includes alternators, generators, solid state charger and other charging devices.";
CM_ SG_ 2566846462 AltCurrent "Measure of electrical current flow from the alternator.  Alternator Current (High Range/Resolution) parameter SPN 1795 has a higher range and resolution of the same parameter.";
CM_ SG_ 2566846462 NetBatteryCurrent "Net flow of electrical current into/out of the first battery or first set of batteries used for starting the engine, for lighting, and for ignition (SLI). See SPN 2579 for alternate range and resolution.";
CM_ SG_ 2566760702 WrelessCommunicationNetworkType2 "Type of Wireless Communication Network
0 = Cellular network #1
1 = Cellular network #2
2 = Wireless LAN #1
3 = Wireless LAN #2
4 = Satellite network
5-250 = Reserved for Future Assignment
251-253 = Reserved
254 = Error
255 = Not Available";
CM_ SG_ 2566760702 NetworkSignalStrength2 "Indicates the signal strength for the wireless communications network type.";
CM_ SG_ 2566760702 NetworkAntennaStatus2 "Indicates the status of the antenna for the wireless communications network type
0 = Off
1 = On
2-250 = Reserved for Future Assignment
251-253 = Reserved
254 = Error
255 = Not Available";
CM_ SG_ 2566760702 NetworkServiceStatus2 "Indicates the status of the Service for the wireless communications network type
0 = Local Service
1 = Roaming Service
2 = Service not available
3 = Not Authorized to Operate on Service
4-250 = Reserved for Future Assignment
251-253 = Reserved
...";
CM_ SG_ 2566760702 NetworkTransceiverStatus2 "Indicates the status of the transceiver for the wireless communications network type
0 = Off
1 = On
2 = Not Authorized to Operate on Network
3-250 = Reserved for Future Assignment
251-253 = Reserved
254 = Error
255 = Not Available";
CM_ SG_ 2566760958 WrelessCommunicationNetworkType1 "Type of Wireless Communication Network
0 = Cellular network #1
1 = Cellular network #2
2 = Wireless LAN #1
3 = Wireless LAN #2
4 = Satellite network
5-250 = Reserved for Future Assignment
251-253 = Reserved
254 = Error
255 = Not Available";
CM_ SG_ 2566760958 NetworkSignalStrength1 "Indicates the signal strength for the wireless communications network type.";
CM_ SG_ 2566760958 NetworkAntennaStatus1 "Indicates the status of the antenna for the wireless communications network type
0 = Off
1 = On
2-250 = Reserved for Future Assignment
251-253 = Reserved
254 = Error
255 = Not Available";
CM_ SG_ 2566760958 NetworkServiceStatus1 "Indicates the status of the Service for the wireless communications network type
0 = Local Service
1 = Roaming Service
2 = Service not available
3 = Not Authorized to Operate on Service
4-250 = Reserved for Future Assignment
251-253 = Reserved
...";
CM_ SG_ 2566760958 NetworkTransceiverStatus1 "Indicates the status of the transceiver for the wireless communications network type
0 = Off
1 = On
2 = Not Authorized to Operate on Network
3-250 = Reserved for Future Assignment
251-253 = Reserved
254 = Error
255 = Not Available";
CM_ SG_ 2633869310 VoltageRegulatorEnabled "State signal indicating the Voltage Regulator is enabled.  This parameter indicates whether the regulator is regulating or not regulating generator output voltage.
00 - Not regulating voltage - unit disabled
01 - Regulating voltage
10 - Reserved
...";
CM_ SG_ 2633869310 VoltageRegulatorSoftStartState "State signal indicating the mode of the Voltage regulator soft start function.  Soft start controls the generator voltage overshoot by controlling the rate of rise of the generator output voltage at generator start up.
00 - Soft start is inactive
...";
CM_ SG_ 2633869310 VltgRgltrUndrfrqncyCmpnstnEnbld "State signal indicating the operating mode for underfrequency compensation.
00 - Underfrequency compensation disabled
01 - Underfrequency compensation enabled
10 - Reserved
11 - Not available
Note:
Underfrequency compensation is when the ...";
CM_ SG_ 2633869310 VltgRgltrVAr_PwrFctrOprtingMode "State signal indicating the operating mode for the Voltage regulator VAr/Power Factor
000 - VAr/Power Factor regulation disabled
001 - Power factor regulation enabled
010 - VAr regulation enabled
011 - Reserved
100 - Reserved
101 - Reserved
...";
CM_ SG_ 2633869310 VltgRglatorLoadCompensationMode "State signal indicating the voltage regulator load compensation mode.  Load compensation is when the voltage is adjusted based on the magnitude of load current
000 - load compensation disabled
001 - Voltage droop compensation enabled
010 - IR ...";
CM_ SG_ 2365433598 GnrtrOtputVoltageBiasPercentage "Measured signal that represents the voltage bias percentage of the generator ouptput voltage being requested by external to the voltage regulator.
Generator output voltage bias percentage is the amount of voltage in percent the generator output ...";
CM_ SG_ 2365433598 GeneratorExcitationFieldCurrent "Measured signal that represents the generator excitation field current.";
CM_ SG_ 2365433598 GeneratorExcitationFieldVoltage "Measured signal that represents the generator excitation field voltage.  Generator excitation field voltage is indicative of the amount of excitation current being supplied by the voltage regulator to the generator field.";

BA_DEF_ BO_ "GenMsgCycleTime" INT 0 3600000;
BA_DEF_ BO_ "GenMsgCycleTimeFast" INT 0 3600000;
BA_DEF_ BO_ "GenMsgDelayTime" INT 0 1000;
BA_DEF_ BO_ "GenMsgILSupport" ENUM  "No","Yes";
BA_DEF_ BO_ "GenMsgRequestable" INT 0 1;
BA_DEF_ BO_ "GenMsgSendType" ENUM  "cyclic","spontaneous","cyclicIfActive","spontaneousWithDelay","cyclicAndSpontaneous","cyclicAndSpontaneousWithDelay","spontaneousWithRepetition","cyclicIfActiveAndSpontaneousWD";
BA_DEF_ BO_ "GenMsgStartDelayTime" INT 0 100000;
BA_DEF_ BO_ "J1939PGNameSecSrc0Dest3" STRING;
BA_DEF_ BO_ "J1939PGPrio" INT 0 7;
BA_DEF_ BO_ "J1939PGPrioSrc0Dest3" INT 0 7;
BA_DEF_ BO_ "J1939PGRelationDest3Src0" INT 0 254;
BA_DEF_ BO_ "J1939PGRelationSrc0Dest3" INT 0 254;
BA_DEF_ BO_ "J1939PGRepCycleSrc0Dest3" INT -1 65535;
BA_DEF_ BO_ "J1939PGRepTypeSrc0Dest3" INT 0 4;
BA_DEF_ BO_ "J1939PGRepetitionCycle" INT 0 65535;
BA_DEF_ BO_ "J1939PGRepetitionType" ENUM  "always","when active","on request";
BA_DEF_ BO_ "J1939PGtoECUSrc0Dest3" INT 0 254;
BA_DEF_ BO_ "J1939PGtoWSMSrc0Dest3" INT 0 254;
BA_DEF_ BO_ "TpJ1939VarDlc" ENUM  "No","Yes";
BA_DEF_ BO_ "VFrameFormat" ENUM  "StandardCAN","ExtendedCAN","reserved","J1939PG";
BA_DEF_ SG_ "GenSigEVName" STRING;
BA_DEF_ SG_ "GenSigILSupport" ENUM  "No","Yes";
BA_DEF_ SG_ "GenSigSendType" ENUM  "Cyclic","OnWrite","OnWriteWithRepetition","OnChange","OnChangeWithRepetition","IfActive","IfActiveWithRepetition","NoSigSendType";
BA_DEF_ SG_ "GenSigStartValue" INT 0 10000;
BA_DEF_ SG_ "SPN" INT 0 524287;
BA_DEF_ SG_ "SigType" ENUM  "Default","Range","RangeSigned","ASCII","Discrete","Control","ReferencePGN","DTC","StringDelimiter","StringLength","StringLengthControl","MessageCounter","MessageChecksum";
BA_DEF_ SG_ "SystemSignalLongSymbol" STRING;
BA_DEF_DEF_ "GenMsgCycleTime" 0;
BA_DEF_DEF_ "GenMsgCycleTimeFast" 0;
BA_DEF_DEF_ "GenMsgDelayTime" 0;
BA_DEF_DEF_ "GenMsgILSupport" "Yes";
BA_DEF_DEF_ "GenMsgRequestable" 1;
BA_DEF_DEF_ "GenMsgSendType" "noMsgSendType";
BA_DEF_DEF_ "GenMsgStartDelayTime" 0;
BA_DEF_DEF_ "GenSigEVName" "Env@Nodename_@Signame";
BA_DEF_DEF_ "GenSigILSupport" "Yes";
BA_DEF_DEF_ "GenSigSendType" "NoSigSendType";
BA_DEF_DEF_ "GenSigStartValue" 0;
BA_DEF_DEF_ "J1939PGNameSecSrc0Dest3" "(null)";
BA_DEF_DEF_ "J1939PGPrio" 6;
BA_DEF_DEF_ "J1939PGPrioSrc0Dest3" 6;
BA_DEF_DEF_ "J1939PGRelationDest3Src0" 254;
BA_DEF_DEF_ "J1939PGRelationSrc0Dest3" 254;
BA_DEF_DEF_ "J1939PGRepCycleSrc0Dest3" -1;
BA_DEF_DEF_ "J1939PGRepTypeSrc0Dest3" 3;
BA_DEF_DEF_ "J1939PGRepetitionCycle" 100;
BA_DEF_DEF_ "J1939PGRepetitionType" "always";
BA_DEF_DEF_ "J1939PGtoECUSrc0Dest3" -1;
BA_DEF_DEF_ "J1939PGtoWSMSrc0Dest3" -1;
BA_DEF_DEF_ "SPN" 0;
BA_DEF_DEF_ "SigType" "Default";
BA_DEF_DEF_ "SystemSignalLongSymbol" "";
BA_DEF_DEF_ "TpJ1939VarDlc" "No";
BA_DEF_DEF_ "VFrameFormat" "J1939PG";
BA_ "GenMsgSendType" BO_ 2566740990 8;
BA_ "TpJ1939VarDlc" BO_ 2566740990 1;
BA_ "GenMsgSendType" BO_ 2566741246 8;
BA_ "TpJ1939VarDlc" BO_ 2566741246 1;
BA_ "GenMsgSendType" BO_ 2566741502 8;
BA_ "TpJ1939VarDlc" BO_ 2566741502 1;
BA_ "GenMsgSendType" BO_ 2566741758 8;
BA_ "TpJ1939VarDlc" BO_ 2566741758 1;
BA_ "GenMsgSendType" BO_ 2566742014 8;
BA_ "TpJ1939VarDlc" BO_ 2566742014 1;
BA_ "GenMsgSendType" BO_ 2560622334 8;
BA_ "TpJ1939VarDlc" BO_ 2560622334 1;
BA_ "GenMsgCycleTime" BO_ 2499630078 500;
BA_ "GenMsgSendType" BO_ 2499630078 0;
BA_ "GenMsgSendType" BO_ 2566750462 8;
BA_ "TpJ1939VarDlc" BO_ 2566750462 1;
BA_ "GenMsgSendType" BO_ 2566750974 8;
BA_ "TpJ1939VarDlc" BO_ 2566750974 1;
BA_ "GenMsgDelayTime" BO_ 2566838782 100;
BA_ "GenMsgDelayTime" BO_ 2561146622 100;
BA_ "GenMsgDelayTime" BO_ 2561081086 100;
BA_ "GenMsgDelayTime" BO_ 2561015550 100;
BA_ "GenMsgCycleTime" BO_ 2566746622 1000;
BA_ "GenMsgSendType" BO_ 2566746622 0;
BA_ "GenMsgCycleTime" BO_ 2566845950 1000;
BA_ "GenMsgSendType" BO_ 2566845950 0;
BA_ "GenMsgCycleTime" BO_ 2566827774 1000;
BA_ "GenMsgSendType" BO_ 2566827774 0;
BA_ "GenMsgCycleTime" BO_ 2566846974 1000;
BA_ "GenMsgSendType" BO_ 2566846974 0;
BA_ "GenMsgCycleTime" BO_ 2566803966 250;
BA_ "GenMsgSendType" BO_ 2566803966 0;
BA_ "GenMsgCycleTime" BO_ 2432593918 100;
BA_ "GenMsgDelayTime" BO_ 2432593918 20;
BA_ "GenMsgSendType" BO_ 2432593918 0;
BA_ "GenMsgCycleTime" BO_ 2566847998 500;
BA_ "GenMsgSendType" BO_ 2566847998 0;
BA_ "GenMsgRequestable" BO_ 2565406462 0;
BA_ "GenMsgSendType" BO_ 2565406462 8;
BA_ "GenMsgCycleTime" BO_ 2566803198 100;
BA_ "GenMsgSendType" BO_ 2566803198 0;
BA_ "GenMsgCycleTime" BO_ 2565870334 50;
BA_ "GenMsgSendType" BO_ 2565870334 0;
BA_ "GenMsgCycleTime" BO_ 2364543998 10;
BA_ "GenMsgSendType" BO_ 2364543998 0;
BA_ "GenMsgCycleTime" BO_ 2566846718 1000;
BA_ "GenMsgSendType" BO_ 2566846718 0;
BA_ "GenMsgCycleTime" BO_ 2566846462 1000;
BA_ "GenMsgSendType" BO_ 2566846462 0;
BA_ "GenMsgCycleTime" BO_ 2633869310 1000;
BA_ "GenMsgSendType" BO_ 2633869310 0;
BA_ "GenMsgCycleTime" BO_ 2365433598 100;
BA_ "GenMsgSendType" BO_ 2365433598 0;
BA_ "SPN" SG_ 2566740990 FlashRedStopLamp 3039;
BA_ "SigType" SG_ 2566740990 FlashRedStopLamp 5;
BA_ "SPN" SG_ 2566740990 FlashProtectLamp 3041;
BA_ "SigType" SG_ 2566740990 FlashProtectLamp 5;
BA_ "SPN" SG_ 2566740990 FlashMalfuncIndicatorLamp 3038;
BA_ "SigType" SG_ 2566740990 FlashMalfuncIndicatorLamp 5;
BA_ "SPN" SG_ 2566740990 FlashAmberWarningLamp 3040;
BA_ "SigType" SG_ 2566740990 FlashAmberWarningLamp 5;
BA_ "SPN" SG_ 2566740990 MalfunctionIndicatorLampStatus 1213;
BA_ "SigType" SG_ 2566740990 MalfunctionIndicatorLampStatus 5;
BA_ "SPN" SG_ 2566740990 AmberWarningLampStatus 624;
BA_ "SigType" SG_ 2566740990 AmberWarningLampStatus 5;
BA_ "SPN" SG_ 2566740990 RedStopLampState 623;
BA_ "SigType" SG_ 2566740990 RedStopLampState 4;
BA_ "SPN" SG_ 2566740990 ProtectLampStatus 987;
BA_ "SigType" SG_ 2566740990 ProtectLampStatus 5;
BA_ "SigType" SG_ 2566740990 DTC5 7;
BA_ "SigType" SG_ 2566740990 DTC4 7;
BA_ "SigType" SG_ 2566740990 DTC3 7;
BA_ "SigType" SG_ 2566740990 DTC2 7;
BA_ "SigType" SG_ 2566740990 DTC1 7;
BA_ "SPN" SG_ 2566741246 FlashRedStopLamp 3039;
BA_ "SigType" SG_ 2566741246 FlashRedStopLamp 5;
BA_ "SPN" SG_ 2566741246 FlashProtectLamp 3041;
BA_ "SigType" SG_ 2566741246 FlashProtectLamp 5;
BA_ "SPN" SG_ 2566741246 FlashMalfuncIndicatorLamp 3038;
BA_ "SigType" SG_ 2566741246 FlashMalfuncIndicatorLamp 5;
BA_ "SPN" SG_ 2566741246 FlashAmberWarningLamp 3040;
BA_ "SigType" SG_ 2566741246 FlashAmberWarningLamp 5;
BA_ "SPN" SG_ 2566741246 MalfunctionIndicatorLampStatus 1213;
BA_ "SigType" SG_ 2566741246 MalfunctionIndicatorLampStatus 5;
BA_ "SPN" SG_ 2566741246 AmberWarningLampStatus 624;
BA_ "SigType" SG_ 2566741246 AmberWarningLampStatus 5;
BA_ "SPN" SG_ 2566741246 RedStopLampState 623;
BA_ "SigType" SG_ 2566741246 RedStopLampState 4;
BA_ "SPN" SG_ 2566741246 ProtectLampStatus 987;
BA_ "SigType" SG_ 2566741246 ProtectLampStatus 5;
BA_ "SigType" SG_ 2566741246 DTC5 7;
BA_ "SigType" SG_ 2566741246 DTC4 7;
BA_ "SigType" SG_ 2566741246 DTC3 7;
BA_ "SigType" SG_ 2566741246 DTC2 7;
BA_ "SigType" SG_ 2566741246 DTC1 7;
BA_ "SPN" SG_ 2566741502 FlashRedStopLamp 3039;
BA_ "SigType" SG_ 2566741502 FlashRedStopLamp 5;
BA_ "SPN" SG_ 2566741502 FlashProtectLamp 3041;
BA_ "SigType" SG_ 2566741502 FlashProtectLamp 5;
BA_ "SPN" SG_ 2566741502 FlashMalfuncIndicatorLamp 3038;
BA_ "SigType" SG_ 2566741502 FlashMalfuncIndicatorLamp 5;
BA_ "SPN" SG_ 2566741502 FlashAmberWarningLamp 3040;
BA_ "SigType" SG_ 2566741502 FlashAmberWarningLamp 5;
BA_ "SPN" SG_ 2566741502 MalfunctionIndicatorLampStatus 1213;
BA_ "SigType" SG_ 2566741502 MalfunctionIndicatorLampStatus 5;
BA_ "SPN" SG_ 2566741502 AmberWarningLampStatus 624;
BA_ "SigType" SG_ 2566741502 AmberWarningLampStatus 5;
BA_ "SPN" SG_ 2566741502 RedStopLampState 623;
BA_ "SigType" SG_ 2566741502 RedStopLampState 4;
BA_ "SPN" SG_ 2566741502 ProtectLampStatus 987;
BA_ "SigType" SG_ 2566741502 ProtectLampStatus 5;
BA_ "SigType" SG_ 2566741502 DTC5 7;
BA_ "SigType" SG_ 2566741502 DTC4 7;
BA_ "SigType" SG_ 2566741502 DTC3 7;
BA_ "SigType" SG_ 2566741502 DTC2 7;
BA_ "SigType" SG_ 2566741502 DTC1 7;
BA_ "SPN" SG_ 2566741758 FlashRedStopLamp 3039;
BA_ "SigType" SG_ 2566741758 FlashRedStopLamp 5;
BA_ "SPN" SG_ 2566741758 FlashProtectLamp 3041;
BA_ "SigType" SG_ 2566741758 FlashProtectLamp 5;
BA_ "SPN" SG_ 2566741758 FlashMalfuncIndicatorLamp 3038;
BA_ "SigType" SG_ 2566741758 FlashMalfuncIndicatorLamp 5;
BA_ "SPN" SG_ 2566741758 FlashAmberWarningLamp 3040;
BA_ "SigType" SG_ 2566741758 FlashAmberWarningLamp 5;
BA_ "SPN" SG_ 2566741758 MalfunctionIndicatorLampStatus 1213;
BA_ "SigType" SG_ 2566741758 MalfunctionIndicatorLampStatus 5;
BA_ "SPN" SG_ 2566741758 AmberWarningLampStatus 624;
BA_ "SigType" SG_ 2566741758 AmberWarningLampStatus 5;
BA_ "SPN" SG_ 2566741758 RedStopLampState 623;
BA_ "SigType" SG_ 2566741758 RedStopLampState 4;
BA_ "SPN" SG_ 2566741758 ProtectLampStatus 987;
BA_ "SigType" SG_ 2566741758 ProtectLampStatus 5;
BA_ "SigType" SG_ 2566741758 DTC5 7;
BA_ "SigType" SG_ 2566741758 DTC4 7;
BA_ "SigType" SG_ 2566741758 DTC3 7;
BA_ "SigType" SG_ 2566741758 DTC2 7;
BA_ "SigType" SG_ 2566741758 DTC1 7;
BA_ "SPN" SG_ 2566742014 FlashRedStopLamp 3039;
BA_ "SigType" SG_ 2566742014 FlashRedStopLamp 5;
BA_ "SPN" SG_ 2566742014 FlashProtectLamp 3041;
BA_ "SigType" SG_ 2566742014 FlashProtectLamp 5;
BA_ "SPN" SG_ 2566742014 FlashMalfuncIndicatorLamp 3038;
BA_ "SigType" SG_ 2566742014 FlashMalfuncIndicatorLamp 5;
BA_ "SPN" SG_ 2566742014 FlashAmberWarningLamp 3040;
BA_ "SigType" SG_ 2566742014 FlashAmberWarningLamp 5;
BA_ "SPN" SG_ 2566742014 MalfunctionIndicatorLampStatus 1213;
BA_ "SigType" SG_ 2566742014 MalfunctionIndicatorLampStatus 5;
BA_ "SPN" SG_ 2566742014 AmberWarningLampStatus 624;
BA_ "SigType" SG_ 2566742014 AmberWarningLampStatus 5;
BA_ "SPN" SG_ 2566742014 RedStopLampState 623;
BA_ "SigType" SG_ 2566742014 RedStopLampState 4;
BA_ "SPN" SG_ 2566742014 ProtectLampStatus 987;
BA_ "SigType" SG_ 2566742014 ProtectLampStatus 5;
BA_ "SigType" SG_ 2566742014 DTC5 7;
BA_ "SigType" SG_ 2566742014 DTC4 7;
BA_ "SigType" SG_ 2566742014 DTC3 7;
BA_ "SigType" SG_ 2566742014 DTC2 7;
BA_ "SigType" SG_ 2566742014 DTC1 7;
BA_ "SPN" SG_ 2560622334 FlashRedStopLamp_3039 3039;
BA_ "SigType" SG_ 2560622334 FlashRedStopLamp_3039 5;
BA_ "SPN" SG_ 2560622334 FlashProtectLamp_3041 3041;
BA_ "SigType" SG_ 2560622334 FlashProtectLamp_3041 5;
BA_ "SPN" SG_ 2560622334 FlashMalfuncIndicatorLamp_3038 3038;
BA_ "SigType" SG_ 2560622334 FlashMalfuncIndicatorLamp_3038 5;
BA_ "SPN" SG_ 2560622334 FlashAmberWarningLamp_3040 3040;
BA_ "SigType" SG_ 2560622334 FlashAmberWarningLamp_3040 5;
BA_ "SPN" SG_ 2560622334 MILStatus_1213 1213;
BA_ "SigType" SG_ 2560622334 MILStatus_1213 5;
BA_ "SPN" SG_ 2560622334 AmberWarningLampStatus_624 624;
BA_ "SigType" SG_ 2560622334 AmberWarningLampStatus_624 5;
BA_ "SPN" SG_ 2560622334 RedStopLampState_623 623;
BA_ "SigType" SG_ 2560622334 RedStopLampState_623 4;
BA_ "SPN" SG_ 2560622334 ProtectLampStatus_987 987;
BA_ "SigType" SG_ 2560622334 ProtectLampStatus_987 5;
BA_ "SigType" SG_ 2560622334 DTC5 7;
BA_ "SigType" SG_ 2560622334 DTC4 7;
BA_ "SigType" SG_ 2560622334 DTC3 7;
BA_ "SigType" SG_ 2560622334 DTC2 7;
BA_ "SigType" SG_ 2560622334 DTC1 7;
BA_ "SPN" SG_ 2566744062 ZeroNetVehicleWeightChange 4075;
BA_ "SigType" SG_ 2566744062 ZeroNetVehicleWeightChange 5;
BA_ "SPN" SG_ 2499630078 EngExhaustGasTempAverageBank2 4152;
BA_ "SigType" SG_ 2499630078 EngExhaustGasTempAverageBank2 1;
BA_ "SPN" SG_ 2499630078 EngExhaustGasTempAverageBank1 4153;
BA_ "SigType" SG_ 2499630078 EngExhaustGasTempAverageBank1 1;
BA_ "SPN" SG_ 2499630078 EngExhaustGasTempAverage 4151;
BA_ "SigType" SG_ 2499630078 EngExhaustGasTempAverage 1;
BA_ "SPN" SG_ 2560556798 PermanentDTCs_4108 4108;
BA_ "SigType" SG_ 2560556798 PermanentDTCs_4108 1;
BA_ "SPN" SG_ 2560556798 PreviouslyMILOnDTCs_4107 4107;
BA_ "SigType" SG_ 2560556798 PreviouslyMILOnDTCs_4107 1;
BA_ "SPN" SG_ 2560556798 MILOnDTCs_4106 4106;
BA_ "SigType" SG_ 2560556798 MILOnDTCs_4106 1;
BA_ "SPN" SG_ 2560556798 AllPendingDTCs_4105 4105;
BA_ "SigType" SG_ 2560556798 AllPendingDTCs_4105 1;
BA_ "SPN" SG_ 2560556798 PendingDTCs_4104 4104;
BA_ "SigType" SG_ 2560556798 PendingDTCs_4104 1;
BA_ "SPN" SG_ 2566750462 FlashRedStopLamp 3039;
BA_ "SigType" SG_ 2566750462 FlashRedStopLamp 5;
BA_ "SPN" SG_ 2566750462 FlashProtectLamp 3041;
BA_ "SigType" SG_ 2566750462 FlashProtectLamp 5;
BA_ "SPN" SG_ 2566750462 FlashMalfuncIndicatorLamp 3038;
BA_ "SigType" SG_ 2566750462 FlashMalfuncIndicatorLamp 5;
BA_ "SPN" SG_ 2566750462 FlashAmberWarningLamp 3040;
BA_ "SigType" SG_ 2566750462 FlashAmberWarningLamp 5;
BA_ "SPN" SG_ 2566750462 MalfunctionIndicatorLampStatus 1213;
BA_ "SigType" SG_ 2566750462 MalfunctionIndicatorLampStatus 5;
BA_ "SPN" SG_ 2566750462 AmberWarningLampStatus 624;
BA_ "SigType" SG_ 2566750462 AmberWarningLampStatus 5;
BA_ "SPN" SG_ 2566750462 RedStopLampState 623;
BA_ "SigType" SG_ 2566750462 RedStopLampState 4;
BA_ "SPN" SG_ 2566750462 ProtectLampStatus 987;
BA_ "SigType" SG_ 2566750462 ProtectLampStatus 5;
BA_ "SigType" SG_ 2566750462 DTC5 7;
BA_ "SigType" SG_ 2566750462 DTC4 7;
BA_ "SigType" SG_ 2566750462 DTC3 7;
BA_ "SigType" SG_ 2566750462 DTC2 7;
BA_ "SigType" SG_ 2566750462 DTC1 7;
BA_ "SPN" SG_ 2566750974 FlashRedStopLamp 3039;
BA_ "SigType" SG_ 2566750974 FlashRedStopLamp 5;
BA_ "SPN" SG_ 2566750974 FlashProtectLamp 3041;
BA_ "SigType" SG_ 2566750974 FlashProtectLamp 5;
BA_ "SPN" SG_ 2566750974 FlashMalfuncIndicatorLamp 3038;
BA_ "SigType" SG_ 2566750974 FlashMalfuncIndicatorLamp 5;
BA_ "SPN" SG_ 2566750974 FlashAmberWarningLamp 3040;
BA_ "SigType" SG_ 2566750974 FlashAmberWarningLamp 5;
BA_ "SPN" SG_ 2566750974 MalfunctionIndicatorLampStatus 1213;
BA_ "SigType" SG_ 2566750974 MalfunctionIndicatorLampStatus 5;
BA_ "SPN" SG_ 2566750974 AmberWarningLampStatus 624;
BA_ "SigType" SG_ 2566750974 AmberWarningLampStatus 5;
BA_ "SPN" SG_ 2566750974 RedStopLampState 623;
BA_ "SigType" SG_ 2566750974 RedStopLampState 4;
BA_ "SPN" SG_ 2566750974 ProtectLampStatus 987;
BA_ "SigType" SG_ 2566750974 ProtectLampStatus 5;
BA_ "SigType" SG_ 2566750974 DTC5 7;
BA_ "SigType" SG_ 2566750974 DTC4 7;
BA_ "SigType" SG_ 2566750974 DTC3 7;
BA_ "SigType" SG_ 2566750974 DTC2 7;
BA_ "SigType" SG_ 2566750974 DTC1 7;
BA_ "SigType" SG_ 2566754558 AETCTorqueValue14 1;
BA_ "SigType" SG_ 2566754558 AETCTorqueValue13 1;
BA_ "SigType" SG_ 2566754558 AETCTorqueValue12 1;
BA_ "SigType" SG_ 2566754558 AETCTorqueValue11 1;
BA_ "SigType" SG_ 2566754558 AETCTorqueValue10 1;
BA_ "SigType" SG_ 2566754558 AETCTorqueValue09 1;
BA_ "SigType" SG_ 2566754558 AETCTorqueValue08 1;
BA_ "SigType" SG_ 2566754558 AETCTorqueValue07 1;
BA_ "SigType" SG_ 2566754558 AETCTorqueValue06 1;
BA_ "SigType" SG_ 2566754558 AETCTorqueValue05 1;
BA_ "SigType" SG_ 2566754558 AETCTorqueValue04 1;
BA_ "SigType" SG_ 2566754558 AETCTorqueValue03 1;
BA_ "SigType" SG_ 2566754558 AETCTorqueValue02 1;
BA_ "SigType" SG_ 2566754558 AETCTorqueValue01 1;
BA_ "SigType" SG_ 2566754558 AETCSpeedValue14 1;
BA_ "SigType" SG_ 2566754558 AETCSpeedValue13 1;
BA_ "SigType" SG_ 2566754558 AETCSpeedValue12 1;
BA_ "SigType" SG_ 2566754558 AETCSpeedValue11 1;
BA_ "SigType" SG_ 2566754558 AETCSpeedValue10 1;
BA_ "SigType" SG_ 2566754558 AETCSpeedValue09 1;
BA_ "SigType" SG_ 2566754558 AETCSpeedValue08 1;
BA_ "SigType" SG_ 2566754558 AETCSpeedValue07 1;
BA_ "SigType" SG_ 2566754558 AETCSpeedValue06 1;
BA_ "SigType" SG_ 2566754558 AETCSpeedValue05 1;
BA_ "SigType" SG_ 2566754558 AETCSpeedValue04 1;
BA_ "SigType" SG_ 2566754558 AETCSpeedValue03 1;
BA_ "SigType" SG_ 2566754558 AETCSpeedValue02 1;
BA_ "SigType" SG_ 2566754558 AETCSpeedValue01 1;
BA_ "SigType" SG_ 2566754558 AETCTorqueValue00 1;
BA_ "SigType" SG_ 2566754558 AETCSpeedValue00 1;
BA_ "GenSigStartValue" SG_ 2566754558 NumberOfAETCDataPoints 5;
BA_ "SPN" SG_ 2566754558 NumberOfAETCDataPoints 3559;
BA_ "SPN" SG_ 2566754558 AETCDataCollectionStandard 3558;
BA_ "SPN" SG_ 2566749950 RightHeadlampLightDistribution 3694;
BA_ "SPN" SG_ 2566749950 LeftHeadlampLightDistribution 3693;
BA_ "SPN" SG_ 2566749950 RightHeadlampDynamicBendingLight 3692;
BA_ "SPN" SG_ 2566749950 LeftHeadlampDynamicBendingLight 3691;
BA_ "SPN" SG_ 2566838782 AuxI_OChannel2 1084;
BA_ "SigType" SG_ 2566838782 AuxI_OChannel2 1;
BA_ "SPN" SG_ 2566838782 AuxI_OChannel1 1083;
BA_ "SigType" SG_ 2566838782 AuxI_OChannel1 1;
BA_ "SPN" SG_ 2566838782 AuxI_O13 713;
BA_ "SigType" SG_ 2566838782 AuxI_O13 4;
BA_ "SPN" SG_ 2566838782 AuxI_O14 714;
BA_ "SigType" SG_ 2566838782 AuxI_O14 4;
BA_ "SPN" SG_ 2566838782 AuxI_O15 715;
BA_ "SigType" SG_ 2566838782 AuxI_O15 4;
BA_ "SPN" SG_ 2566838782 AuxI_O16 716;
BA_ "SigType" SG_ 2566838782 AuxI_O16 4;
BA_ "SPN" SG_ 2566838782 AuxI_O09 709;
BA_ "SigType" SG_ 2566838782 AuxI_O09 4;
BA_ "SPN" SG_ 2566838782 AuxI_O10 710;
BA_ "SigType" SG_ 2566838782 AuxI_O10 4;
BA_ "SPN" SG_ 2566838782 AuxI_O11 711;
BA_ "SigType" SG_ 2566838782 AuxI_O11 4;
BA_ "SPN" SG_ 2566838782 AuxI_O12 712;
BA_ "SigType" SG_ 2566838782 AuxI_O12 4;
BA_ "SPN" SG_ 2566838782 AuxI_O05 705;
BA_ "SigType" SG_ 2566838782 AuxI_O05 4;
BA_ "SPN" SG_ 2566838782 AuxI_O06 706;
BA_ "SigType" SG_ 2566838782 AuxI_O06 4;
BA_ "SPN" SG_ 2566838782 AuxI_O07 707;
BA_ "SigType" SG_ 2566838782 AuxI_O07 4;
BA_ "SPN" SG_ 2566838782 AuxI_O08 708;
BA_ "SigType" SG_ 2566838782 AuxI_O08 4;
BA_ "SPN" SG_ 2566838782 AuxI_O01 701;
BA_ "SigType" SG_ 2566838782 AuxI_O01 4;
BA_ "SPN" SG_ 2566838782 AuxI_O02 702;
BA_ "SigType" SG_ 2566838782 AuxI_O02 4;
BA_ "SPN" SG_ 2566838782 AuxI_O03 703;
BA_ "SigType" SG_ 2566838782 AuxI_O03 4;
BA_ "SPN" SG_ 2566838782 AuxI_O04 704;
BA_ "SigType" SG_ 2566838782 AuxI_O04 4;
BA_ "SPN" SG_ 2561146622 AuxI_O45_3868 3868;
BA_ "SigType" SG_ 2561146622 AuxI_O45_3868 4;
BA_ "SPN" SG_ 2561146622 AuxI_O46_3869 3869;
BA_ "SigType" SG_ 2561146622 AuxI_O46_3869 4;
BA_ "SPN" SG_ 2561146622 AuxI_O47_3870 3870;
BA_ "SigType" SG_ 2561146622 AuxI_O47_3870 4;
BA_ "SPN" SG_ 2561146622 AuxI_O48_3871 3871;
BA_ "SigType" SG_ 2561146622 AuxI_O48_3871 4;
BA_ "SPN" SG_ 2561146622 AuxI_O41_3864 3864;
BA_ "SigType" SG_ 2561146622 AuxI_O41_3864 4;
BA_ "SPN" SG_ 2561146622 AuxI_O42_3865 3865;
BA_ "SigType" SG_ 2561146622 AuxI_O42_3865 4;
BA_ "SPN" SG_ 2561146622 AuxI_O43_3866 3866;
BA_ "SigType" SG_ 2561146622 AuxI_O43_3866 4;
BA_ "SPN" SG_ 2561146622 AuxI_O44_3867 3867;
BA_ "SigType" SG_ 2561146622 AuxI_O44_3867 4;
BA_ "SPN" SG_ 2561146622 AuxI_O37_3860 3860;
BA_ "SigType" SG_ 2561146622 AuxI_O37_3860 4;
BA_ "SPN" SG_ 2561146622 AuxI_O38_3861 3861;
BA_ "SigType" SG_ 2561146622 AuxI_O38_3861 4;
BA_ "SPN" SG_ 2561146622 AuxI_O39_3862 3862;
BA_ "SigType" SG_ 2561146622 AuxI_O39_3862 4;
BA_ "SPN" SG_ 2561146622 AuxI_O40_3863 3863;
BA_ "SigType" SG_ 2561146622 AuxI_O40_3863 4;
BA_ "SPN" SG_ 2561146622 AuxI_O33_3856 3856;
BA_ "SigType" SG_ 2561146622 AuxI_O33_3856 4;
BA_ "SPN" SG_ 2561146622 AuxI_O34_3857 3857;
BA_ "SigType" SG_ 2561146622 AuxI_O34_3857 4;
BA_ "SPN" SG_ 2561146622 AuxI_O35_3858 3858;
BA_ "SigType" SG_ 2561146622 AuxI_O35_3858 4;
BA_ "SPN" SG_ 2561146622 AuxI_O36_3859 3859;
BA_ "SigType" SG_ 2561146622 AuxI_O36_3859 4;
BA_ "SPN" SG_ 2561146622 AuxI_O29_3852 3852;
BA_ "SigType" SG_ 2561146622 AuxI_O29_3852 4;
BA_ "SPN" SG_ 2561146622 AuxI_O30_3853 3853;
BA_ "SigType" SG_ 2561146622 AuxI_O30_3853 4;
BA_ "SPN" SG_ 2561146622 AuxI_O31_3854 3854;
BA_ "SigType" SG_ 2561146622 AuxI_O31_3854 4;
BA_ "SPN" SG_ 2561146622 AuxI_O32_3855 3855;
BA_ "SigType" SG_ 2561146622 AuxI_O32_3855 4;
BA_ "SPN" SG_ 2561146622 AuxI_O25_3848 3848;
BA_ "SigType" SG_ 2561146622 AuxI_O25_3848 4;
BA_ "SPN" SG_ 2561146622 AuxI_O26_3849 3849;
BA_ "SigType" SG_ 2561146622 AuxI_O26_3849 4;
BA_ "SPN" SG_ 2561146622 AuxI_O27_3850 3850;
BA_ "SigType" SG_ 2561146622 AuxI_O27_3850 4;
BA_ "SPN" SG_ 2561146622 AuxI_O28_3851 3851;
BA_ "SigType" SG_ 2561146622 AuxI_O28_3851 4;
BA_ "SPN" SG_ 2561146622 AuxI_O21_3844 3844;
BA_ "SigType" SG_ 2561146622 AuxI_O21_3844 4;
BA_ "SPN" SG_ 2561146622 AuxI_O22_3845 3845;
BA_ "SigType" SG_ 2561146622 AuxI_O22_3845 4;
BA_ "SPN" SG_ 2561146622 AuxI_O23_3846 3846;
BA_ "SigType" SG_ 2561146622 AuxI_O23_3846 4;
BA_ "SPN" SG_ 2561146622 AuxI_O24_3847 3847;
BA_ "SigType" SG_ 2561146622 AuxI_O24_3847 4;
BA_ "SPN" SG_ 2561146622 AuxI_O17_3840 3840;
BA_ "SigType" SG_ 2561146622 AuxI_O17_3840 4;
BA_ "SPN" SG_ 2561146622 AuxI_O18_3841 3841;
BA_ "SigType" SG_ 2561146622 AuxI_O18_3841 4;
BA_ "SPN" SG_ 2561146622 AuxI_O19_3842 3842;
BA_ "SigType" SG_ 2561146622 AuxI_O19_3842 4;
BA_ "SPN" SG_ 2561146622 AuxI_O20_3843 3843;
BA_ "SigType" SG_ 2561146622 AuxI_O20_3843 4;
BA_ "SPN" SG_ 2561081086 AuxI_O77_3900 3900;
BA_ "SigType" SG_ 2561081086 AuxI_O77_3900 4;
BA_ "SPN" SG_ 2561081086 AuxI_O78_3901 3901;
BA_ "SigType" SG_ 2561081086 AuxI_O78_3901 4;
BA_ "SPN" SG_ 2561081086 AuxI_O79_3902 3902;
BA_ "SigType" SG_ 2561081086 AuxI_O79_3902 4;
BA_ "SPN" SG_ 2561081086 AuxI_O80_3903 3903;
BA_ "SigType" SG_ 2561081086 AuxI_O80_3903 4;
BA_ "SPN" SG_ 2561081086 AuxI_O73_3896 3896;
BA_ "SigType" SG_ 2561081086 AuxI_O73_3896 4;
BA_ "SPN" SG_ 2561081086 AuxI_O74_3897 3897;
BA_ "SigType" SG_ 2561081086 AuxI_O74_3897 4;
BA_ "SPN" SG_ 2561081086 AuxI_O75_3898 3898;
BA_ "SigType" SG_ 2561081086 AuxI_O75_3898 4;
BA_ "SPN" SG_ 2561081086 AuxI_O76_3899 3899;
BA_ "SigType" SG_ 2561081086 AuxI_O76_3899 4;
BA_ "SPN" SG_ 2561081086 AuxI_O69_3892 3892;
BA_ "SigType" SG_ 2561081086 AuxI_O69_3892 4;
BA_ "SPN" SG_ 2561081086 AuxI_O70_3893 3893;
BA_ "SigType" SG_ 2561081086 AuxI_O70_3893 4;
BA_ "SPN" SG_ 2561081086 AuxI_O71_3894 3894;
BA_ "SigType" SG_ 2561081086 AuxI_O71_3894 4;
BA_ "SPN" SG_ 2561081086 AuxI_O72_3895 3895;
BA_ "SigType" SG_ 2561081086 AuxI_O72_3895 4;
BA_ "SPN" SG_ 2561081086 AuxI_O65_3888 3888;
BA_ "SigType" SG_ 2561081086 AuxI_O65_3888 4;
BA_ "SPN" SG_ 2561081086 AuxI_O66_3889 3889;
BA_ "SigType" SG_ 2561081086 AuxI_O66_3889 4;
BA_ "SPN" SG_ 2561081086 AuxI_O67_3890 3890;
BA_ "SigType" SG_ 2561081086 AuxI_O67_3890 4;
BA_ "SPN" SG_ 2561081086 AuxI_O68_3891 3891;
BA_ "SigType" SG_ 2561081086 AuxI_O68_3891 4;
BA_ "SPN" SG_ 2561081086 AuxI_O61_3884 3884;
BA_ "SigType" SG_ 2561081086 AuxI_O61_3884 4;
BA_ "SPN" SG_ 2561081086 AuxI_O62_3885 3885;
BA_ "SigType" SG_ 2561081086 AuxI_O62_3885 4;
BA_ "SPN" SG_ 2561081086 AuxI_O63_3886 3886;
BA_ "SigType" SG_ 2561081086 AuxI_O63_3886 4;
BA_ "SPN" SG_ 2561081086 AuxI_O64_3887 3887;
BA_ "SigType" SG_ 2561081086 AuxI_O64_3887 4;
BA_ "SPN" SG_ 2561081086 AuxI_O57_3880 3880;
BA_ "SigType" SG_ 2561081086 AuxI_O57_3880 4;
BA_ "SPN" SG_ 2561081086 AuxI_O58_3881 3881;
BA_ "SigType" SG_ 2561081086 AuxI_O58_3881 4;
BA_ "SPN" SG_ 2561081086 AuxI_O59_3882 3882;
BA_ "SigType" SG_ 2561081086 AuxI_O59_3882 4;
BA_ "SPN" SG_ 2561081086 AuxI_O60_3883 3883;
BA_ "SigType" SG_ 2561081086 AuxI_O60_3883 4;
BA_ "SPN" SG_ 2561081086 AuxI_O53_3876 3876;
BA_ "SigType" SG_ 2561081086 AuxI_O53_3876 4;
BA_ "SPN" SG_ 2561081086 AuxI_O54_3877 3877;
BA_ "SigType" SG_ 2561081086 AuxI_O54_3877 4;
BA_ "SPN" SG_ 2561081086 AuxI_O55_3878 3878;
BA_ "SigType" SG_ 2561081086 AuxI_O55_3878 4;
BA_ "SPN" SG_ 2561081086 AuxI_O56_3879 3879;
BA_ "SigType" SG_ 2561081086 AuxI_O56_3879 4;
BA_ "SPN" SG_ 2561081086 AuxI_O49_3872 3872;
BA_ "SigType" SG_ 2561081086 AuxI_O49_3872 4;
BA_ "SPN" SG_ 2561081086 AuxI_O50_3873 3873;
BA_ "SigType" SG_ 2561081086 AuxI_O50_3873 4;
BA_ "SPN" SG_ 2561081086 AuxI_O51_3874 3874;
BA_ "SigType" SG_ 2561081086 AuxI_O51_3874 4;
BA_ "SPN" SG_ 2561081086 AuxI_O52_3875 3875;
BA_ "SigType" SG_ 2561081086 AuxI_O52_3875 4;
BA_ "SPN" SG_ 2561015550 AuxI_O109_3932 3932;
BA_ "SigType" SG_ 2561015550 AuxI_O109_3932 4;
BA_ "SPN" SG_ 2561015550 AuxI_O110_3933 3933;
BA_ "SigType" SG_ 2561015550 AuxI_O110_3933 4;
BA_ "SPN" SG_ 2561015550 AuxI_O111_3934 3934;
BA_ "SigType" SG_ 2561015550 AuxI_O111_3934 4;
BA_ "SPN" SG_ 2561015550 AuxI_O112_3935 3935;
BA_ "SigType" SG_ 2561015550 AuxI_O112_3935 4;
BA_ "SPN" SG_ 2561015550 AuxI_O105_3928 3928;
BA_ "SigType" SG_ 2561015550 AuxI_O105_3928 4;
BA_ "SPN" SG_ 2561015550 AuxI_O106_3929 3929;
BA_ "SigType" SG_ 2561015550 AuxI_O106_3929 4;
BA_ "SPN" SG_ 2561015550 AuxI_O107_3930 3930;
BA_ "SigType" SG_ 2561015550 AuxI_O107_3930 4;
BA_ "SPN" SG_ 2561015550 AuxI_O108_3931 3931;
BA_ "SigType" SG_ 2561015550 AuxI_O108_3931 4;
BA_ "SPN" SG_ 2561015550 AuxI_O101_3924 3924;
BA_ "SigType" SG_ 2561015550 AuxI_O101_3924 4;
BA_ "SPN" SG_ 2561015550 AuxI_O102_3925 3925;
BA_ "SigType" SG_ 2561015550 AuxI_O102_3925 4;
BA_ "SPN" SG_ 2561015550 AuxI_O103_3926 3926;
BA_ "SigType" SG_ 2561015550 AuxI_O103_3926 4;
BA_ "SPN" SG_ 2561015550 AuxI_O104_3927 3927;
BA_ "SigType" SG_ 2561015550 AuxI_O104_3927 4;
BA_ "SPN" SG_ 2561015550 AuxI_O97_3920 3920;
BA_ "SigType" SG_ 2561015550 AuxI_O97_3920 4;
BA_ "SPN" SG_ 2561015550 AuxI_O98_3921 3921;
BA_ "SigType" SG_ 2561015550 AuxI_O98_3921 4;
BA_ "SPN" SG_ 2561015550 AuxI_O99_3922 3922;
BA_ "SigType" SG_ 2561015550 AuxI_O99_3922 4;
BA_ "SPN" SG_ 2561015550 AuxI_O100_3923 3923;
BA_ "SigType" SG_ 2561015550 AuxI_O100_3923 4;
BA_ "SPN" SG_ 2561015550 AuxI_O93_3916 3916;
BA_ "SigType" SG_ 2561015550 AuxI_O93_3916 4;
BA_ "SPN" SG_ 2561015550 AuxI_O94_3917 3917;
BA_ "SigType" SG_ 2561015550 AuxI_O94_3917 4;
BA_ "SPN" SG_ 2561015550 AuxI_O95_3918 3918;
BA_ "SigType" SG_ 2561015550 AuxI_O95_3918 4;
BA_ "SPN" SG_ 2561015550 AuxI_O96_3919 3919;
BA_ "SigType" SG_ 2561015550 AuxI_O96_3919 4;
BA_ "SPN" SG_ 2561015550 AuxI_O89_3912 3912;
BA_ "SigType" SG_ 2561015550 AuxI_O89_3912 4;
BA_ "SPN" SG_ 2561015550 AuxI_O90_3913 3913;
BA_ "SigType" SG_ 2561015550 AuxI_O90_3913 4;
BA_ "SPN" SG_ 2561015550 AuxI_O91_3914 3914;
BA_ "SigType" SG_ 2561015550 AuxI_O91_3914 4;
BA_ "SPN" SG_ 2561015550 AuxI_O92_3915 3915;
BA_ "SigType" SG_ 2561015550 AuxI_O92_3915 4;
BA_ "SPN" SG_ 2561015550 AuxI_O85_3908 3908;
BA_ "SigType" SG_ 2561015550 AuxI_O85_3908 4;
BA_ "SPN" SG_ 2561015550 AuxI_O86_3909 3909;
BA_ "SigType" SG_ 2561015550 AuxI_O86_3909 4;
BA_ "SPN" SG_ 2561015550 AuxI_O87_3910 3910;
BA_ "SigType" SG_ 2561015550 AuxI_O87_3910 4;
BA_ "SPN" SG_ 2561015550 AuxI_O88_3911 3911;
BA_ "SigType" SG_ 2561015550 AuxI_O88_3911 4;
BA_ "SPN" SG_ 2561015550 AuxI_O81_3904 3904;
BA_ "SigType" SG_ 2561015550 AuxI_O81_3904 4;
BA_ "SPN" SG_ 2561015550 AuxI_O82_3905 3905;
BA_ "SigType" SG_ 2561015550 AuxI_O82_3905 4;
BA_ "SPN" SG_ 2561015550 AuxI_O83_3906 3906;
BA_ "SigType" SG_ 2561015550 AuxI_O83_3906 4;
BA_ "SPN" SG_ 2561015550 AuxI_O84_3907 3907;
BA_ "SigType" SG_ 2561015550 AuxI_O84_3907 4;
BA_ "SPN" SG_ 2566746622 TrailerBrakeStrokeAxle5Right 3804;
BA_ "SPN" SG_ 2566746622 TrailerBrakeStrokeAxle5Left 3803;
BA_ "SPN" SG_ 2566746622 TrailerBrakeStrokeAxle4Right 3802;
BA_ "SPN" SG_ 2566746622 TrailerBrakeStrokeAxle4Left 3801;
BA_ "SPN" SG_ 2566746622 TrailerBrakeStrokeAxle3Right 3800;
BA_ "SPN" SG_ 2566746622 TrailerBrakeStrokeAxle3Left 3799;
BA_ "SPN" SG_ 2566746622 TrailerBrakeStrokeAxle2Right 3798;
BA_ "SPN" SG_ 2566746622 TrailerBrakeStrokeAxle2Left 3797;
BA_ "SPN" SG_ 2566746622 TrailerBrakeStrokeAxle1Right 3796;
BA_ "SPN" SG_ 2566746622 TrailerBrakeStrokeAxle1Left 3795;
BA_ "SPN" SG_ 2566746622 TractorBrakeStrokeAxle5Right 3794;
BA_ "SPN" SG_ 2566746622 TractorBrakeStrokeAxle5Left 3793;
BA_ "SPN" SG_ 2566746622 TractorBrakeStrokeAxle4Right 3792;
BA_ "SPN" SG_ 2566746622 TractorBrakeStrokeAxle4Left 3791;
BA_ "SPN" SG_ 2566746622 TractorBrakeStrokeAxle3Right 3790;
BA_ "SPN" SG_ 2566746622 TractorBrakeStrokeAxle3Left 3789;
BA_ "SPN" SG_ 2566746622 TractorBrakeStrokeAxle2Right 3788;
BA_ "SPN" SG_ 2566746622 TractorBrakeStrokeAxle2Left 3787;
BA_ "SPN" SG_ 2566746622 TractorBrakeStrokeAxle1Right 3786;
BA_ "SPN" SG_ 2566746622 TractorBrakeStrokeAxle1Left 3785;
BA_ "SPN" SG_ 2566845950 RoadSurfaceTemp 79;
BA_ "SigType" SG_ 2566845950 RoadSurfaceTemp 1;
BA_ "SPN" SG_ 2566845950 EngAirIntakeTemp 172;
BA_ "SigType" SG_ 2566845950 EngAirIntakeTemp 1;
BA_ "SPN" SG_ 2566845950 AmbientAirTemp 171;
BA_ "SigType" SG_ 2566845950 AmbientAirTemp 1;
BA_ "SPN" SG_ 2566845950 CabInteriorTemp 170;
BA_ "SigType" SG_ 2566845950 CabInteriorTemp 1;
BA_ "SPN" SG_ 2566845950 BarometricPress 108;
BA_ "SigType" SG_ 2566845950 BarometricPress 1;
BA_ "SPN" SG_ 2566840062 EngAirStopPress 6832;
BA_ "SigType" SG_ 2566840062 EngAirStopPress 1;
BA_ "SPN" SG_ 2566840062 EngAirStartPress6831 6831;
BA_ "SigType" SG_ 2566840062 EngAirStartPress6831 1;
BA_ "SPN" SG_ 2566840062 EngAirStartPress 82;
BA_ "SigType" SG_ 2566840062 EngAirStartPress 1;
BA_ "SPN" SG_ 2566827774 AirCompressorStatus 1351;
BA_ "SigType" SG_ 2566827774 AirCompressorStatus 4;
BA_ "SPN" SG_ 2566827774 AirSuspensionSupplyPress 1090;
BA_ "SigType" SG_ 2566827774 AirSuspensionSupplyPress 1;
BA_ "SPN" SG_ 2566827774 AuxEquipmentSupplyPress 1089;
BA_ "SigType" SG_ 2566827774 AuxEquipmentSupplyPress 1;
BA_ "SPN" SG_ 2566827774 PowertrainCircuitAirSupplyPress 6305;
BA_ "SigType" SG_ 2566827774 PowertrainCircuitAirSupplyPress 1;
BA_ "SPN" SG_ 2566827774 ServiceBrakeCircuit2AirPress 1088;
BA_ "SigType" SG_ 2566827774 ServiceBrakeCircuit2AirPress 1;
BA_ "SPN" SG_ 2566827774 ServiceBrakeCircuit1AirPress 1087;
BA_ "SigType" SG_ 2566827774 ServiceBrakeCircuit1AirPress 1;
BA_ "SPN" SG_ 2566827774 ParkingAnd_orTrailerAirPress 1086;
BA_ "SigType" SG_ 2566827774 ParkingAnd_orTrailerAirPress 1;
BA_ "SPN" SG_ 2566827774 PneumaticSupplyPress 46;
BA_ "SigType" SG_ 2566827774 PneumaticSupplyPress 1;
BA_ "SPN" SG_ 2566846974 SteerAxleLubePress 2614;
BA_ "SigType" SG_ 2566846974 SteerAxleLubePress 1;
BA_ "SPN" SG_ 2566846974 SteerAxleTemp 75;
BA_ "SigType" SG_ 2566846974 SteerAxleTemp 1;
BA_ "SPN" SG_ 2566846974 DriveAxleLubePress 2613;
BA_ "SigType" SG_ 2566846974 DriveAxleLubePress 1;
BA_ "SPN" SG_ 2566846974 DriveAxleTemp 578;
BA_ "SigType" SG_ 2566846974 DriveAxleTemp 1;
BA_ "SPN" SG_ 2566846974 DriveAxleLiftAirPress 579;
BA_ "SigType" SG_ 2566846974 DriveAxleLiftAirPress 1;
BA_ "SPN" SG_ 2566846974 DriveAxleLocation 930;
BA_ "SPN" SG_ 2633935614 EngGsMssFlwSnsrFuelingCorrection 1694;
BA_ "SigType" SG_ 2633935614 EngGsMssFlwSnsrFuelingCorrection 1;
BA_ "GenSigStartValue" SG_ 2633935614 GsFlInjctonPulseCorrectionFactor 32128;
BA_ "SPN" SG_ 2633935614 GsFlInjctonPulseCorrectionFactor 6649;
BA_ "SigType" SG_ 2633935614 GsFlInjctonPulseCorrectionFactor 1;
BA_ "SPN" SG_ 2633935614 EngTurboWastegateValvePos 1693;
BA_ "SigType" SG_ 2633935614 EngTurboWastegateValvePos 1;
BA_ "SPN" SG_ 2633935614 EngDesiredAbsIntakeManifoldPress 1692;
BA_ "SigType" SG_ 2633935614 EngDesiredAbsIntakeManifoldPress 1;
BA_ "SPN" SG_ 2633935614 EngGasFuelCorrectionFactor 1116;
BA_ "SigType" SG_ 2633935614 EngGasFuelCorrectionFactor 1;
BA_ "SPN" SG_ 2566803966 RequestedACCDistanceMode 1799;
BA_ "SPN" SG_ 2566803966 ACCUsageDemand 5023;
BA_ "SigType" SG_ 2566803966 ACCUsageDemand 5;
BA_ "SPN" SG_ 2432593918 ForwardCollisionWarning 5022;
BA_ "SigType" SG_ 2432593918 ForwardCollisionWarning 5;
BA_ "SPN" SG_ 2432593918 ACCDistanceAlertSignal 1796;
BA_ "SigType" SG_ 2432593918 ACCDistanceAlertSignal 5;
BA_ "SPN" SG_ 2432593918 ACCSystemShutoffWarning 1797;
BA_ "SigType" SG_ 2432593918 ACCSystemShutoffWarning 5;
BA_ "SPN" SG_ 2432593918 ACCTargetDetected 1798;
BA_ "SigType" SG_ 2432593918 ACCTargetDetected 5;
BA_ "SPN" SG_ 2432593918 RoadCurvature 1591;
BA_ "SigType" SG_ 2432593918 RoadCurvature 1;
BA_ "SPN" SG_ 2432593918 AdptiveCruiseCtrlSetDistanceMode 1589;
BA_ "SPN" SG_ 2432593918 AdaptiveCruiseCtrlMode 1590;
BA_ "SPN" SG_ 2432593918 AdaptiveCruiseCtrlSetSpeed 1588;
BA_ "SigType" SG_ 2432593918 AdaptiveCruiseCtrlSetSpeed 1;
BA_ "SPN" SG_ 2432593918 DistanceToForwardVehicle 1587;
BA_ "SigType" SG_ 2432593918 DistanceToForwardVehicle 1;
BA_ "SPN" SG_ 2432593918 SpeedOfForwardVehicle 1586;
BA_ "SigType" SG_ 2432593918 SpeedOfForwardVehicle 1;
BA_ "SPN" SG_ 2633935102 ArticulationAngle 1120;
BA_ "SigType" SG_ 2633935102 ArticulationAngle 1;
BA_ "SPN" SG_ 2633927934 RelativeHumidity 354;
BA_ "SigType" SG_ 2633927934 RelativeHumidity 1;
BA_ "SPN" SG_ 2633927934 AuxLevel 3087;
BA_ "SigType" SG_ 2633927934 AuxLevel 1;
BA_ "SPN" SG_ 2633927934 AuxPress2 1388;
BA_ "SigType" SG_ 2633927934 AuxPress2 1;
BA_ "SPN" SG_ 2633927934 AuxPress1 1387;
BA_ "SigType" SG_ 2633927934 AuxPress1 1;
BA_ "SPN" SG_ 2633927934 AuxTemp2 442;
BA_ "SigType" SG_ 2633927934 AuxTemp2 1;
BA_ "SPN" SG_ 2633927934 AuxTemp1 441;
BA_ "SigType" SG_ 2633927934 AuxTemp1 1;
BA_ "SPN" SG_ 2566847998 LNGVaporizerCoolantOutletTemp 7020;
BA_ "SigType" SG_ 2566847998 LNGVaporizerCoolantOutletTemp 1;
BA_ "SPN" SG_ 2566847998 EngGasFuelVentPress 6814;
BA_ "SigType" SG_ 2566847998 EngGasFuelVentPress 1;
BA_ "SPN" SG_ 2566847998 EngBlowerBypassValvePos 72;
BA_ "SigType" SG_ 2566847998 EngBlowerBypassValvePos 1;
BA_ "SPN" SG_ 2566847998 EngGasSupplyPress 159;
BA_ "SigType" SG_ 2566847998 EngGasSupplyPress 1;
BA_ "SPN" SG_ 2565406462 AddressBusy_3293 3293;
BA_ "SPN" SG_ 2565406462 ControlByte_2541 2541;
BA_ "SigType" SG_ 2565406462 ControlByte_2541 6;
BA_ "SPN" SG_ 2565406462 ParameterGroupNumber_2547 2547;
BA_ "SigType" SG_ 2565406462 ParameterGroupNumber_2547 6;
BA_ "SigType" SG_ 2565406462 GroupFunctionValue 1;
BA_ "SPN" SG_ 2565406462 AddressAccessDenied_3292 3292;
BA_ "SPN" SG_ 2565406462 AddressNegAcknoledgement_3291 3291;
BA_ "SPN" SG_ 2565406462 AddressAcknowledged_3290 3290;
BA_ "SPN" SG_ 2566803198 Status2OfDoors 3411;
BA_ "SigType" SG_ 2566803198 Status2OfDoors 4;
BA_ "SPN" SG_ 2566803198 Ramp_WheelChairLiftPos 1820;
BA_ "SigType" SG_ 2566803198 Ramp_WheelChairLiftPos 4;
BA_ "SPN" SG_ 2566803198 PosOfDoors 1821;
BA_ "SPN" SG_ 2565870334 FifthWheelRollWarnIndcr_3317 3317;
BA_ "SigType" SG_ 2565870334 FifthWheelRollWarnIndcr_3317 5;
BA_ "SPN" SG_ 2565870334 FifthWheelRollMoment_3310 3310;
BA_ "SigType" SG_ 2565870334 FifthWheelRollMoment_3310 1;
BA_ "SPN" SG_ 2565870334 FifthWheelDrawbarForce_3309 3309;
BA_ "SigType" SG_ 2565870334 FifthWheelDrawbarForce_3309 1;
BA_ "SPN" SG_ 2565870334 FifthWheelVerticalForce_3308 3308;
BA_ "SigType" SG_ 2565870334 FifthWheelVerticalForce_3308 1;
BA_ "SPN" SG_ 2566762238 FifthWheelSliderLockIndicator 3316;
BA_ "SigType" SG_ 2566762238 FifthWheelSliderLockIndicator 4;
BA_ "SPN" SG_ 2566762238 FifthWheelSliderPos 3311;
BA_ "SigType" SG_ 2566762238 FifthWheelSliderPos 1;
BA_ "SPN" SG_ 2566762238 FfthWhlLockCoupleStatusIndicator 3313;
BA_ "SigType" SG_ 2566762238 FfthWhlLockCoupleStatusIndicator 5;
BA_ "SPN" SG_ 2566762238 FfthWhlLckReadyToCoupleIndicator 3312;
BA_ "SigType" SG_ 2566762238 FfthWhlLckReadyToCoupleIndicator 5;
BA_ "SPN" SG_ 2566762238 FifthWheelErrorStatus 3307;
BA_ "SPN" SG_ 2364543998 RollPitchMeasurementLatency_3327 3327;
BA_ "SigType" SG_ 2364543998 RollPitchMeasurementLatency_3327 1;
BA_ "SPN" SG_ 2364543998 PitchAndRollCompensated_3326 3326;
BA_ "SigType" SG_ 2364543998 PitchAndRollCompensated_3326 5;
BA_ "SPN" SG_ 2364543998 PitchRateFigureOfMerit_3325 3325;
BA_ "SigType" SG_ 2364543998 PitchRateFigureOfMerit_3325 5;
BA_ "SPN" SG_ 2364543998 RollAngleFigureOfMerit_3324 3324;
BA_ "SigType" SG_ 2364543998 RollAngleFigureOfMerit_3324 5;
BA_ "SPN" SG_ 2364543998 PitchAngleFigureOfMerit_3323 3323;
BA_ "SigType" SG_ 2364543998 PitchAngleFigureOfMerit_3323 5;
BA_ "SPN" SG_ 2364543998 PitchRate_3322 3322;
BA_ "SigType" SG_ 2364543998 PitchRate_3322 1;
BA_ "SPN" SG_ 2364543998 RollAngle_3319 3319;
BA_ "SigType" SG_ 2364543998 RollAngle_3319 1;
BA_ "SPN" SG_ 2364543998 PitchAngle_3318 3318;
BA_ "SigType" SG_ 2364543998 PitchAngle_3318 1;
BA_ "SPN" SG_ 2566846718 TransOilLevel1MeasurementStatus 3026;
BA_ "SPN" SG_ 2566846718 TransOilLevel1CountdownTimer 3028;
BA_ "SPN" SG_ 2566846718 TransOilLevel1High_Low 3027;
BA_ "SigType" SG_ 2566846718 TransOilLevel1High_Low 1;
BA_ "SPN" SG_ 2566846718 TransOilTemp1 177;
BA_ "SigType" SG_ 2566846718 TransOilTemp1 1;
BA_ "SPN" SG_ 2566846718 TransOilPress 127;
BA_ "SigType" SG_ 2566846718 TransOilPress 1;
BA_ "SPN" SG_ 2566846718 TransFilterDiffPress 126;
BA_ "SigType" SG_ 2566846718 TransFilterDiffPress 1;
BA_ "SPN" SG_ 2566846718 TransOilLevel1 124;
BA_ "SigType" SG_ 2566846718 TransOilLevel1 1;
BA_ "SPN" SG_ 2566846718 ClutchPress 123;
BA_ "SigType" SG_ 2566846718 ClutchPress 1;
BA_ "SPN" SG_ 2566846462 KeyswitchBatteryPotential 158;
BA_ "SigType" SG_ 2566846462 KeyswitchBatteryPotential 1;
BA_ "SPN" SG_ 2566846462 BatteryPotential_PowerInput1 168;
BA_ "SigType" SG_ 2566846462 BatteryPotential_PowerInput1 1;
BA_ "SPN" SG_ 2566846462 ChargingSystemPotential 167;
BA_ "SigType" SG_ 2566846462 ChargingSystemPotential 1;
BA_ "SPN" SG_ 2566846462 AltCurrent 115;
BA_ "SigType" SG_ 2566846462 AltCurrent 1;
BA_ "SPN" SG_ 2566846462 NetBatteryCurrent 114;
BA_ "SigType" SG_ 2566846462 NetBatteryCurrent 1;
BA_ "SPN" SG_ 2566760702 WrelessCommunicationNetworkType2 3446;
BA_ "SPN" SG_ 2566760702 NetworkSignalStrength2 3445;
BA_ "SigType" SG_ 2566760702 NetworkSignalStrength2 1;
BA_ "SPN" SG_ 2566760702 NetworkAntennaStatus2 3444;
BA_ "SPN" SG_ 2566760702 NetworkServiceStatus2 3443;
BA_ "SPN" SG_ 2566760702 NetworkTransceiverStatus2 3442;
BA_ "SPN" SG_ 2566760958 WrelessCommunicationNetworkType1 3372;
BA_ "SPN" SG_ 2566760958 NetworkSignalStrength1 3371;
BA_ "SigType" SG_ 2566760958 NetworkSignalStrength1 1;
BA_ "SPN" SG_ 2566760958 NetworkAntennaStatus1 3370;
BA_ "SPN" SG_ 2566760958 NetworkServiceStatus1 3369;
BA_ "SPN" SG_ 2566760958 NetworkTransceiverStatus1 3368;
BA_ "SPN" SG_ 2633869310 VoltageRegulatorEnabled 3379;
BA_ "SigType" SG_ 2633869310 VoltageRegulatorEnabled 5;
BA_ "SPN" SG_ 2633869310 VoltageRegulatorSoftStartState 3378;
BA_ "SigType" SG_ 2633869310 VoltageRegulatorSoftStartState 5;
BA_ "SPN" SG_ 2633869310 VltgRgltrUndrfrqncyCmpnstnEnbld 3377;
BA_ "SigType" SG_ 2633869310 VltgRgltrUndrfrqncyCmpnstnEnbld 5;
BA_ "SPN" SG_ 2633869310 VltgRgltrVAr_PwrFctrOprtingMode 3376;
BA_ "SPN" SG_ 2633869310 VltgRglatorLoadCompensationMode 3375;
BA_ "SPN" SG_ 2365433598 GnrtrOtputVoltageBiasPercentage 3382;
BA_ "SigType" SG_ 2365433598 GnrtrOtputVoltageBiasPercentage 1;
BA_ "SPN" SG_ 2365433598 GeneratorExcitationFieldCurrent 3381;
BA_ "SigType" SG_ 2365433598 GeneratorExcitationFieldCurrent 1;
BA_ "SPN" SG_ 2365433598 GeneratorExcitationFieldVoltage 3380;
BA_ "SigType" SG_ 2365433598 GeneratorExcitationFieldVoltage 1;
VAL_ 2566740990 FlashRedStopLamp 0 "Slow Flash" 1 "Fast Flash" 2 "Reserved" 3 "Unavailable / Do Not Flash";
VAL_ 2566740990 FlashProtectLamp 0 "Slow Flash" 1 "Fast Flash" 2 "Reserved" 3 "Unavailable / Do Not Flash";
VAL_ 2566740990 FlashMalfuncIndicatorLamp 0 "Slow Flash" 1 "Fast Flash" 2 "Class C DTC  " 3 "Unavailable / Do Not Flash";
VAL_ 2566740990 FlashAmberWarningLamp 0 "Slow Flash" 1 "Fast Flash" 2 "Reserved" 3 "Unavailable / Do Not Flash";
VAL_ 2566740990 MalfunctionIndicatorLampStatus 0 "Lamp Off" 1 "Lamp On" 2 "Short MIL for WWH OBD" 3 "Not available";
VAL_ 2566740990 AmberWarningLampStatus 0 "Lamp Off" 1 "Lamp On" 2 "Reserved" 3 "Not available";
VAL_ 2566740990 RedStopLampState 0 "Lamp Off" 1 "Lamp On" 2 "Reserved" 3 "Not available";
VAL_ 2566740990 ProtectLampStatus 0 "Lamp Off" 1 "Lamp On" 2 "Reserved" 3 "Not available";
VAL_ 2566741246 FlashRedStopLamp 0 "Slow Flash" 1 "Fast Flash" 2 "Reserved" 3 "Unavailable / Do Not Flash";
VAL_ 2566741246 FlashProtectLamp 0 "Slow Flash" 1 "Fast Flash" 2 "Reserved" 3 "Unavailable / Do Not Flash";
VAL_ 2566741246 FlashMalfuncIndicatorLamp 0 "Slow Flash" 1 "Fast Flash" 2 "Class C DTC  " 3 "Unavailable / Do Not Flash";
VAL_ 2566741246 FlashAmberWarningLamp 0 "Slow Flash" 1 "Fast Flash" 2 "Reserved" 3 "Unavailable / Do Not Flash";
VAL_ 2566741246 MalfunctionIndicatorLampStatus 0 "Lamp Off" 1 "Lamp On" 2 "Short MIL for WWH OBD" 3 "Not available";
VAL_ 2566741246 AmberWarningLampStatus 0 "Lamp Off" 1 "Lamp On" 2 "Reserved" 3 "Not available";
VAL_ 2566741246 RedStopLampState 0 "Lamp Off" 1 "Lamp On" 2 "Reserved" 3 "Not available";
VAL_ 2566741246 ProtectLampStatus 0 "Lamp Off" 1 "Lamp On" 2 "Reserved" 3 "Not available";
VAL_ 2566741502 FlashRedStopLamp 0 "Slow Flash" 1 "Fast Flash" 2 "Reserved" 3 "Unavailable / Do Not Flash";
VAL_ 2566741502 FlashProtectLamp 0 "Slow Flash" 1 "Fast Flash" 2 "Reserved" 3 "Unavailable / Do Not Flash";
VAL_ 2566741502 FlashMalfuncIndicatorLamp 0 "Slow Flash" 1 "Fast Flash" 2 "Class C DTC  " 3 "Unavailable / Do Not Flash";
VAL_ 2566741502 FlashAmberWarningLamp 0 "Slow Flash" 1 "Fast Flash" 2 "Reserved" 3 "Unavailable / Do Not Flash";
VAL_ 2566741502 MalfunctionIndicatorLampStatus 0 "Lamp Off" 1 "Lamp On" 2 "Short MIL for WWH OBD" 3 "Not available";
VAL_ 2566741502 AmberWarningLampStatus 0 "Lamp Off" 1 "Lamp On" 2 "Reserved" 3 "Not available";
VAL_ 2566741502 RedStopLampState 0 "Lamp Off" 1 "Lamp On" 2 "Reserved" 3 "Not available";
VAL_ 2566741502 ProtectLampStatus 0 "Lamp Off" 1 "Lamp On" 2 "Reserved" 3 "Not available";
VAL_ 2566741758 FlashRedStopLamp 0 "Slow Flash" 1 "Fast Flash" 2 "Reserved" 3 "Unavailable / Do Not Flash";
VAL_ 2566741758 FlashProtectLamp 0 "Slow Flash" 1 "Fast Flash" 2 "Reserved" 3 "Unavailable / Do Not Flash";
VAL_ 2566741758 FlashMalfuncIndicatorLamp 0 "Slow Flash" 1 "Fast Flash" 2 "Class C DTC  " 3 "Unavailable / Do Not Flash";
VAL_ 2566741758 FlashAmberWarningLamp 0 "Slow Flash" 1 "Fast Flash" 2 "Reserved" 3 "Unavailable / Do Not Flash";
VAL_ 2566741758 MalfunctionIndicatorLampStatus 0 "Lamp Off" 1 "Lamp On" 2 "Short MIL for WWH OBD" 3 "Not available";
VAL_ 2566741758 AmberWarningLampStatus 0 "Lamp Off" 1 "Lamp On" 2 "Reserved" 3 "Not available";
VAL_ 2566741758 RedStopLampState 0 "Lamp Off" 1 "Lamp On" 2 "Reserved" 3 "Not available";
VAL_ 2566741758 ProtectLampStatus 0 "Lamp Off" 1 "Lamp On" 2 "Reserved" 3 "Not available";
VAL_ 2566742014 FlashRedStopLamp 0 "Slow Flash" 1 "Fast Flash" 2 "Reserved" 3 "Unavailable / Do Not Flash";
VAL_ 2566742014 FlashProtectLamp 0 "Slow Flash" 1 "Fast Flash" 2 "Reserved" 3 "Unavailable / Do Not Flash";
VAL_ 2566742014 FlashMalfuncIndicatorLamp 0 "Slow Flash" 1 "Fast Flash" 2 "Class C DTC  " 3 "Unavailable / Do Not Flash";
VAL_ 2566742014 FlashAmberWarningLamp 0 "Slow Flash" 1 "Fast Flash" 2 "Reserved" 3 "Unavailable / Do Not Flash";
VAL_ 2566742014 MalfunctionIndicatorLampStatus 0 "Lamp Off" 1 "Lamp On" 2 "Short MIL for WWH OBD" 3 "Not available";
VAL_ 2566742014 AmberWarningLampStatus 0 "Lamp Off" 1 "Lamp On" 2 "Reserved" 3 "Not available";
VAL_ 2566742014 RedStopLampState 0 "Lamp Off" 1 "Lamp On" 2 "Reserved" 3 "Not available";
VAL_ 2566742014 ProtectLampStatus 0 "Lamp Off" 1 "Lamp On" 2 "Reserved" 3 "Not available";
VAL_ 2560622334 FlashRedStopLamp_3039 0 "Slow Flash" 1 "Fast Flash" 2 "Reserved" 3 "Unavailable / Do Not Flash";
VAL_ 2560622334 FlashProtectLamp_3041 0 "Slow Flash" 1 "Fast Flash" 2 "Reserved" 3 "Unavailable / Do Not Flash";
VAL_ 2560622334 FlashMalfuncIndicatorLamp_3038 0 "Slow Flash" 1 "Fast Flash" 2 "Class C DTC  " 3 "Unavailable / Do Not Flash";
VAL_ 2560622334 FlashAmberWarningLamp_3040 0 "Slow Flash" 1 "Fast Flash" 2 "Reserved" 3 "Unavailable / Do Not Flash";
VAL_ 2560622334 MILStatus_1213 0 "Lamp Off" 1 "Lamp On" 2 "Short MIL for WWH OBD" 3 "Not available";
VAL_ 2560622334 AmberWarningLampStatus_624 0 "Lamp Off" 1 "Lamp On" 2 "Reserved" 3 "Not available";
VAL_ 2560622334 RedStopLampState_623 0 "Lamp Off" 1 "Lamp On" 2 "Reserved" 3 "Not available";
VAL_ 2560622334 ProtectLampStatus_987 0 "Lamp Off" 1 "Lamp On" 2 "Reserved" 3 "Not available";
VAL_ 2566744062 ZeroNetVehicleWeightChange 0 "No change to Net Vehicle Weight Change " 1 "Zero Net Vehicle Weight Change" 2 "Reserved" 3 "Not available / Not applicable";
VAL_ 2566750462 FlashRedStopLamp 0 "Slow Flash" 1 "Fast Flash" 2 "Reserved" 3 "Unavailable / Do Not Flash";
VAL_ 2566750462 FlashProtectLamp 0 "Slow Flash" 1 "Fast Flash" 2 "Reserved" 3 "Unavailable / Do Not Flash";
VAL_ 2566750462 FlashMalfuncIndicatorLamp 0 "Slow Flash" 1 "Fast Flash" 2 "Class C DTC  " 3 "Unavailable / Do Not Flash";
VAL_ 2566750462 FlashAmberWarningLamp 0 "Slow Flash" 1 "Fast Flash" 2 "Reserved" 3 "Unavailable / Do Not Flash";
VAL_ 2566750462 MalfunctionIndicatorLampStatus 0 "Lamp Off" 1 "Lamp On" 2 "Short MIL for WWH OBD" 3 "Not available";
VAL_ 2566750462 AmberWarningLampStatus 0 "Lamp Off" 1 "Lamp On" 2 "Reserved" 3 "Not available";
VAL_ 2566750462 RedStopLampState 0 "Lamp Off" 1 "Lamp On" 2 "Reserved" 3 "Not available";
VAL_ 2566750462 ProtectLampStatus 0 "Lamp Off" 1 "Lamp On" 2 "Reserved" 3 "Not available";
VAL_ 2566750974 FlashRedStopLamp 0 "Slow Flash" 1 "Fast Flash" 2 "Reserved" 3 "Unavailable / Do Not Flash";
VAL_ 2566750974 FlashProtectLamp 0 "Slow Flash" 1 "Fast Flash" 2 "Reserved" 3 "Unavailable / Do Not Flash";
VAL_ 2566750974 FlashMalfuncIndicatorLamp 0 "Slow Flash" 1 "Fast Flash" 2 "Class C DTC  " 3 "Unavailable / Do Not Flash";
VAL_ 2566750974 FlashAmberWarningLamp 0 "Slow Flash" 1 "Fast Flash" 2 "Reserved" 3 "Unavailable / Do Not Flash";
VAL_ 2566750974 MalfunctionIndicatorLampStatus 0 "Lamp Off" 1 "Lamp On" 2 "Short MIL for WWH OBD" 3 "Not available";
VAL_ 2566750974 AmberWarningLampStatus 0 "Lamp Off" 1 "Lamp On" 2 "Reserved" 3 "Not available";
VAL_ 2566750974 RedStopLampState 0 "Lamp Off" 1 "Lamp On" 2 "Reserved" 3 "Not available";
VAL_ 2566750974 ProtectLampStatus 0 "Lamp Off" 1 "Lamp On" 2 "Reserved" 3 "Not available";
VAL_ 2566754558 AETCDataCollectionStandard 0 "SAE J1995" 15 "Not Available";
VAL_ 2566749950 RightHeadlampLightDistribution 0 "Light distribution town" 1 "Light distribution country" 2 "Light distribution motorway" 3 "Light distribution high beam" 4 "Light distribution adverse weather" 5 "Light distribution fail safe position" 6 "Light distribution failure" 7 "Different light distributions not available" 15 "Not available";
VAL_ 2566749950 LeftHeadlampLightDistribution 0 "Light distribution town" 1 "Light distribution country" 2 "Light distribution motorway" 3 "Light distribution high beam" 4 "Light distribution adverse weather" 5 "Light distribution fail safe position" 6 "Light distribution failure" 7 "Different light distributions not available" 15 "Not available";
VAL_ 2566749950 RightHeadlampDynamicBendingLight 0 "Dynamic bending light deactivated" 1 "Dynamic bending light is working properly" 2 "Dynamic bending light fail safe position" 3 "Dynamic bending light failure" 7 "Not available";
VAL_ 2566749950 LeftHeadlampDynamicBendingLight 0 "Dynamic bending light deactivated" 1 "Dynamic bending light is working properly" 2 "Dynamic bending light fail safe position" 3 "Dynamic bending light failure" 7 "Not available";
VAL_ 2566838782 AuxI_O13 0 "Auxiliary channel off" 1 "Auxiliary channel on" 2 "Error" 3 "Not available";
VAL_ 2566838782 AuxI_O14 0 "Auxiliary channel off" 1 "Auxiliary channel on" 2 "Error" 3 "Not available";
VAL_ 2566838782 AuxI_O15 0 "Auxiliary channel off" 1 "Auxiliary channel on" 2 "Error" 3 "Not available";
VAL_ 2566838782 AuxI_O16 0 "Auxiliary channel off" 1 "Auxiliary channel on" 2 "Error" 3 "Not available";
VAL_ 2566838782 AuxI_O09 0 "Auxiliary channel off" 1 "Auxiliary channel on" 2 "Error" 3 "Not available";
VAL_ 2566838782 AuxI_O10 0 "Auxiliary channel off" 1 "Auxiliary channel on" 2 "Error" 3 "Not available";
VAL_ 2566838782 AuxI_O11 0 "Auxiliary channel off" 1 "Auxiliary channel on" 2 "Error" 3 "Not available";
VAL_ 2566838782 AuxI_O12 0 "Auxiliary channel off" 1 "Auxiliary channel on" 2 "Error" 3 "Not available";
VAL_ 2566838782 AuxI_O05 0 "Auxiliary channel off" 1 "Auxiliary channel on" 2 "Error" 3 "Not available";
VAL_ 2566838782 AuxI_O06 0 "Auxiliary channel off" 1 "Auxiliary channel on" 2 "Error" 3 "Not available";
VAL_ 2566838782 AuxI_O07 0 "Auxiliary channel off" 1 "Auxiliary channel on" 2 "Error" 3 "Not available";
VAL_ 2566838782 AuxI_O08 0 "Auxiliary channel off" 1 "Auxiliary channel on" 2 "Error" 3 "Not available";
VAL_ 2566838782 AuxI_O01 0 "Auxiliary channel off" 1 "Auxiliary channel on" 2 "Error" 3 "Not available";
VAL_ 2566838782 AuxI_O02 0 "Auxiliary channel off" 1 "Auxiliary channel on" 2 "Error" 3 "Not available";
VAL_ 2566838782 AuxI_O03 0 "Auxiliary channel off" 1 "Auxiliary channel on" 2 "Error" 3 "Not available";
VAL_ 2566838782 AuxI_O04 0 "Auxiliary channel off" 1 "Auxiliary channel on" 2 "Error" 3 "Not available";
VAL_ 2561146622 AuxI_O45_3868 0 "Auxiliary channel off" 1 "Auxiliary channel on" 2 "Error Indicator or Not Used " 3 "Not Available or Take No Action";
VAL_ 2561146622 AuxI_O46_3869 0 "Auxiliary channel off" 1 "Auxiliary channel on" 2 "Error Indicator or Not Used " 3 "Not Available or Take No Action";
VAL_ 2561146622 AuxI_O47_3870 0 "Auxiliary channel off" 1 "Auxiliary channel on" 2 "Error Indicator or Not Used " 3 "Not Available or Take No Action";
VAL_ 2561146622 AuxI_O48_3871 0 "Auxiliary channel off" 1 "Auxiliary channel on" 2 "Error Indicator or Not Used " 3 "Not Available or Take No Action";
VAL_ 2561146622 AuxI_O41_3864 0 "Auxiliary channel off" 1 "Auxiliary channel on" 2 "Error Indicator or Not Used " 3 "Not Available or Take No Action";
VAL_ 2561146622 AuxI_O42_3865 0 "Auxiliary channel off" 1 "Auxiliary channel on" 2 "Error Indicator or Not Used " 3 "Not Available or Take No Action";
VAL_ 2561146622 AuxI_O43_3866 0 "Auxiliary channel off" 1 "Auxiliary channel on" 2 "Error Indicator or Not Used " 3 "Not Available or Take No Action";
VAL_ 2561146622 AuxI_O44_3867 0 "Auxiliary channel off" 1 "Auxiliary channel on" 2 "Error Indicator or Not Used " 3 "Not Available or Take No Action";
VAL_ 2561146622 AuxI_O37_3860 0 "Auxiliary channel off" 1 "Auxiliary channel on" 2 "Error Indicator or Not Used " 3 "Not Available or Take No Action";
VAL_ 2561146622 AuxI_O38_3861 0 "Auxiliary channel off" 1 "Auxiliary channel on" 2 "Error Indicator or Not Used " 3 "Not Available or Take No Action";
VAL_ 2561146622 AuxI_O39_3862 0 "Auxiliary channel off" 1 "Auxiliary channel on" 2 "Error Indicator or Not Used " 3 "Not Available or Take No Action";
VAL_ 2561146622 AuxI_O40_3863 0 "Auxiliary channel off" 1 "Auxiliary channel on" 2 "Error Indicator or Not Used " 3 "Not Available or Take No Action";
VAL_ 2561146622 AuxI_O33_3856 0 "Auxiliary channel off" 1 "Auxiliary channel on" 2 "Error Indicator or Not Used " 3 "Not Available or Take No Action";
VAL_ 2561146622 AuxI_O34_3857 0 "Auxiliary channel off" 1 "Auxiliary channel on" 2 "Error Indicator or Not Used " 3 "Not Available or Take No Action";
VAL_ 2561146622 AuxI_O35_3858 0 "Auxiliary channel off" 1 "Auxiliary channel on" 2 "Error Indicator or Not Used " 3 "Not Available or Take No Action";
VAL_ 2561146622 AuxI_O36_3859 0 "Auxiliary channel off" 1 "Auxiliary channel on" 2 "Error Indicator or Not Used " 3 "Not Available or Take No Action";
VAL_ 2561146622 AuxI_O29_3852 0 "Auxiliary channel off" 1 "Auxiliary channel on" 2 "Error Indicator or Not Used " 3 "Not Available or Take No Action";
VAL_ 2561146622 AuxI_O30_3853 0 "Auxiliary channel off" 1 "Auxiliary channel on" 2 "Error Indicator or Not Used " 3 "Not Available or Take No Action";
VAL_ 2561146622 AuxI_O31_3854 0 "Auxiliary channel off" 1 "Auxiliary channel on" 2 "Error Indicator or Not Used " 3 "Not Available or Take No Action";
VAL_ 2561146622 AuxI_O32_3855 0 "Auxiliary channel off" 1 "Auxiliary channel on" 2 "Error Indicator or Not Used " 3 "Not Available or Take No Action";
VAL_ 2561146622 AuxI_O25_3848 0 "Auxiliary channel off" 1 "Auxiliary channel on" 2 "Error Indicator or Not Used " 3 "Not Available or Take No Action";
VAL_ 2561146622 AuxI_O26_3849 0 "Auxiliary channel off" 1 "Auxiliary channel on" 2 "Error Indicator or Not Used " 3 "Not Available or Take No Action";
VAL_ 2561146622 AuxI_O27_3850 0 "Auxiliary channel off" 1 "Auxiliary channel on" 2 "Error Indicator or Not Used " 3 "Not Available or Take No Action";
VAL_ 2561146622 AuxI_O28_3851 0 "Auxiliary channel off" 1 "Auxiliary channel on" 2 "Error Indicator or Not Used " 3 "Not Available or Take No Action";
VAL_ 2561146622 AuxI_O21_3844 0 "Auxiliary channel off" 1 "Auxiliary channel on" 2 "Error Indicator or Not Used " 3 "Not Available or Take No Action";
VAL_ 2561146622 AuxI_O22_3845 0 "Auxiliary channel off" 1 "Auxiliary channel on" 2 "Error Indicator or Not Used " 3 "Not Available or Take No Action";
VAL_ 2561146622 AuxI_O23_3846 0 "Auxiliary channel off" 1 "Auxiliary channel on" 2 "Error Indicator or Not Used " 3 "Not Available or Take No Action";
VAL_ 2561146622 AuxI_O24_3847 0 "Auxiliary channel off" 1 "Auxiliary channel on" 2 "Error Indicator or Not Used " 3 "Not Available or Take No Action";
VAL_ 2561146622 AuxI_O17_3840 0 "Auxiliary channel off" 1 "Auxiliary channel on" 2 "Error Indicator or Not Used " 3 "Not Available or Take No Action";
VAL_ 2561146622 AuxI_O18_3841 0 "Auxiliary channel off" 1 "Auxiliary channel on" 2 "Error Indicator or Not Used " 3 "Not Available or Take No Action";
VAL_ 2561146622 AuxI_O19_3842 0 "Auxiliary channel off" 1 "Auxiliary channel on" 2 "Error Indicator or Not Used " 3 "Not Available or Take No Action";
VAL_ 2561146622 AuxI_O20_3843 0 "Auxiliary channel off" 1 "Auxiliary channel on" 2 "Error Indicator or Not Used " 3 "Not Available or Take No Action";
VAL_ 2561081086 AuxI_O77_3900 0 "Auxiliary channel off" 1 "Auxiliary channel on" 2 "Error Indicator or Not Used " 3 "Not Available or Take No Action";
VAL_ 2561081086 AuxI_O78_3901 0 "Auxiliary channel off" 1 "Auxiliary channel on" 2 "Error Indicator or Not Used " 3 "Not Available or Take No Action";
VAL_ 2561081086 AuxI_O79_3902 0 "Auxiliary channel off" 1 "Auxiliary channel on" 2 "Error Indicator or Not Used " 3 "Not Available or Take No Action";
VAL_ 2561081086 AuxI_O80_3903 0 "Auxiliary channel off" 1 "Auxiliary channel on" 2 "Error Indicator or Not Used " 3 "Not Available or Take No Action";
VAL_ 2561081086 AuxI_O73_3896 0 "Auxiliary channel off" 1 "Auxiliary channel on" 2 "Error Indicator or Not Used " 3 "Not Available or Take No Action";
VAL_ 2561081086 AuxI_O74_3897 0 "Auxiliary channel off" 1 "Auxiliary channel on" 2 "Error Indicator or Not Used " 3 "Not Available or Take No Action";
VAL_ 2561081086 AuxI_O75_3898 0 "Auxiliary channel off" 1 "Auxiliary channel on" 2 "Error Indicator or Not Used " 3 "Not Available or Take No Action";
VAL_ 2561081086 AuxI_O76_3899 0 "Auxiliary channel off" 1 "Auxiliary channel on" 2 "Error Indicator or Not Used " 3 "Not Available or Take No Action";
VAL_ 2561081086 AuxI_O69_3892 0 "Auxiliary channel off" 1 "Auxiliary channel on" 2 "Error Indicator or Not Used " 3 "Not Available or Take No Action";
VAL_ 2561081086 AuxI_O70_3893 0 "Auxiliary channel off" 1 "Auxiliary channel on" 2 "Error Indicator or Not Used " 3 "Not Available or Take No Action";
VAL_ 2561081086 AuxI_O71_3894 0 "Auxiliary channel off" 1 "Auxiliary channel on" 2 "Error Indicator or Not Used " 3 "Not Available or Take No Action";
VAL_ 2561081086 AuxI_O72_3895 0 "Auxiliary channel off" 1 "Auxiliary channel on" 2 "Error Indicator or Not Used " 3 "Not Available or Take No Action";
VAL_ 2561081086 AuxI_O65_3888 0 "Auxiliary channel off" 1 "Auxiliary channel on" 2 "Error Indicator or Not Used " 3 "Not Available or Take No Action";
VAL_ 2561081086 AuxI_O66_3889 0 "Auxiliary channel off" 1 "Auxiliary channel on" 2 "Error Indicator or Not Used " 3 "Not Available or Take No Action";
VAL_ 2561081086 AuxI_O67_3890 0 "Auxiliary channel off" 1 "Auxiliary channel on" 2 "Error Indicator or Not Used " 3 "Not Available or Take No Action";
VAL_ 2561081086 AuxI_O68_3891 0 "Auxiliary channel off" 1 "Auxiliary channel on" 2 "Error Indicator or Not Used " 3 "Not Available or Take No Action";
VAL_ 2561081086 AuxI_O61_3884 0 "Auxiliary channel off" 1 "Auxiliary channel on" 2 "Error Indicator or Not Used " 3 "Not Available or Take No Action";
VAL_ 2561081086 AuxI_O62_3885 0 "Auxiliary channel off" 1 "Auxiliary channel on" 2 "Error Indicator or Not Used " 3 "Not Available or Take No Action";
VAL_ 2561081086 AuxI_O63_3886 0 "Auxiliary channel off" 1 "Auxiliary channel on" 2 "Error Indicator or Not Used " 3 "Not Available or Take No Action";
VAL_ 2561081086 AuxI_O64_3887 0 "Auxiliary channel off" 1 "Auxiliary channel on" 2 "Error Indicator or Not Used " 3 "Not Available or Take No Action";
VAL_ 2561081086 AuxI_O57_3880 0 "Auxiliary channel off" 1 "Auxiliary channel on" 2 "Error Indicator or Not Used " 3 "Not Available or Take No Action";
VAL_ 2561081086 AuxI_O58_3881 0 "Auxiliary channel off" 1 "Auxiliary channel on" 2 "Error Indicator or Not Used " 3 "Not Available or Take No Action";
VAL_ 2561081086 AuxI_O59_3882 0 "Auxiliary channel off" 1 "Auxiliary channel on" 2 "Error Indicator or Not Used " 3 "Not Available or Take No Action";
VAL_ 2561081086 AuxI_O60_3883 0 "Auxiliary channel off" 1 "Auxiliary channel on" 2 "Error Indicator or Not Used " 3 "Not Available or Take No Action";
VAL_ 2561081086 AuxI_O53_3876 0 "Auxiliary channel off" 1 "Auxiliary channel on" 2 "Error Indicator or Not Used " 3 "Not Available or Take No Action";
VAL_ 2561081086 AuxI_O54_3877 0 "Auxiliary channel off" 1 "Auxiliary channel on" 2 "Error Indicator or Not Used " 3 "Not Available or Take No Action";
VAL_ 2561081086 AuxI_O55_3878 0 "Auxiliary channel off" 1 "Auxiliary channel on" 2 "Error Indicator or Not Used " 3 "Not Available or Take No Action";
VAL_ 2561081086 AuxI_O56_3879 0 "Auxiliary channel off" 1 "Auxiliary channel on" 2 "Error Indicator or Not Used " 3 "Not Available or Take No Action";
VAL_ 2561081086 AuxI_O49_3872 0 "Auxiliary channel off" 1 "Auxiliary channel on" 2 "Error Indicator or Not Used " 3 "Not Available or Take No Action";
VAL_ 2561081086 AuxI_O50_3873 0 "Auxiliary channel off" 1 "Auxiliary channel on" 2 "Error Indicator or Not Used " 3 "Not Available or Take No Action";
VAL_ 2561081086 AuxI_O51_3874 0 "Auxiliary channel off" 1 "Auxiliary channel on" 2 "Error Indicator or Not Used " 3 "Not Available or Take No Action";
VAL_ 2561081086 AuxI_O52_3875 0 "Auxiliary channel off" 1 "Auxiliary channel on" 2 "Error Indicator or Not Used " 3 "Not Available or Take No Action";
VAL_ 2561015550 AuxI_O109_3932 0 "Auxiliary channel off" 1 "Auxiliary channel on" 2 "Error Indicator or Not Used " 3 "Not Available or Take No Action";
VAL_ 2561015550 AuxI_O110_3933 0 "Auxiliary channel off" 1 "Auxiliary channel on" 2 "Error Indicator or Not Used " 3 "Not Available or Take No Action";
VAL_ 2561015550 AuxI_O111_3934 0 "Auxiliary channel off" 1 "Auxiliary channel on" 2 "Error Indicator or Not Used " 3 "Not Available or Take No Action";
VAL_ 2561015550 AuxI_O112_3935 0 "Auxiliary channel off" 1 "Auxiliary channel on" 2 "Error Indicator or Not Used " 3 "Not Available or Take No Action";
VAL_ 2561015550 AuxI_O105_3928 0 "Auxiliary channel off" 1 "Auxiliary channel on" 2 "Error Indicator or Not Used " 3 "Not Available or Take No Action";
VAL_ 2561015550 AuxI_O106_3929 0 "Auxiliary channel off" 1 "Auxiliary channel on" 2 "Error Indicator or Not Used " 3 "Not Available or Take No Action";
VAL_ 2561015550 AuxI_O107_3930 0 "Auxiliary channel off" 1 "Auxiliary channel on" 2 "Error Indicator or Not Used " 3 "Not Available or Take No Action";
VAL_ 2561015550 AuxI_O108_3931 0 "Auxiliary channel off" 1 "Auxiliary channel on" 2 "Error Indicator or Not Used " 3 "Not Available or Take No Action";
VAL_ 2561015550 AuxI_O101_3924 0 "Auxiliary channel off" 1 "Auxiliary channel on" 2 "Error Indicator or Not Used " 3 "Not Available or Take No Action";
VAL_ 2561015550 AuxI_O102_3925 0 "Auxiliary channel off" 1 "Auxiliary channel on" 2 "Error Indicator or Not Used " 3 "Not Available or Take No Action";
VAL_ 2561015550 AuxI_O103_3926 0 "Auxiliary channel off" 1 "Auxiliary channel on" 2 "Error Indicator or Not Used " 3 "Not Available or Take No Action";
VAL_ 2561015550 AuxI_O104_3927 0 "Auxiliary channel off" 1 "Auxiliary channel on" 2 "Error Indicator or Not Used " 3 "Not Available or Take No Action";
VAL_ 2561015550 AuxI_O97_3920 0 "Auxiliary channel off" 1 "Auxiliary channel on" 2 "Error Indicator or Not Used " 3 "Not Available or Take No Action";
VAL_ 2561015550 AuxI_O98_3921 0 "Auxiliary channel off" 1 "Auxiliary channel on" 2 "Error Indicator or Not Used " 3 "Not Available or Take No Action";
VAL_ 2561015550 AuxI_O99_3922 0 "Auxiliary channel off" 1 "Auxiliary channel on" 2 "Error Indicator or Not Used " 3 "Not Available or Take No Action";
VAL_ 2561015550 AuxI_O100_3923 0 "Auxiliary channel off" 1 "Auxiliary channel on" 2 "Error Indicator or Not Used " 3 "Not Available or Take No Action";
VAL_ 2561015550 AuxI_O93_3916 0 "Auxiliary channel off" 1 "Auxiliary channel on" 2 "Error Indicator or Not Used " 3 "Not Available or Take No Action";
VAL_ 2561015550 AuxI_O94_3917 0 "Auxiliary channel off" 1 "Auxiliary channel on" 2 "Error Indicator or Not Used " 3 "Not Available or Take No Action";
VAL_ 2561015550 AuxI_O95_3918 0 "Auxiliary channel off" 1 "Auxiliary channel on" 2 "Error Indicator or Not Used " 3 "Not Available or Take No Action";
VAL_ 2561015550 AuxI_O96_3919 0 "Auxiliary channel off" 1 "Auxiliary channel on" 2 "Error Indicator or Not Used " 3 "Not Available or Take No Action";
VAL_ 2561015550 AuxI_O89_3912 0 "Auxiliary channel off" 1 "Auxiliary channel on" 2 "Error Indicator or Not Used " 3 "Not Available or Take No Action";
VAL_ 2561015550 AuxI_O90_3913 0 "Auxiliary channel off" 1 "Auxiliary channel on" 2 "Error Indicator or Not Used " 3 "Not Available or Take No Action";
VAL_ 2561015550 AuxI_O91_3914 0 "Auxiliary channel off" 1 "Auxiliary channel on" 2 "Error Indicator or Not Used " 3 "Not Available or Take No Action";
VAL_ 2561015550 AuxI_O92_3915 0 "Auxiliary channel off" 1 "Auxiliary channel on" 2 "Error Indicator or Not Used " 3 "Not Available or Take No Action";
VAL_ 2561015550 AuxI_O85_3908 0 "Auxiliary channel off" 1 "Auxiliary channel on" 2 "Error Indicator or Not Used " 3 "Not Available or Take No Action";
VAL_ 2561015550 AuxI_O86_3909 0 "Auxiliary channel off" 1 "Auxiliary channel on" 2 "Error Indicator or Not Used " 3 "Not Available or Take No Action";
VAL_ 2561015550 AuxI_O87_3910 0 "Auxiliary channel off" 1 "Auxiliary channel on" 2 "Error Indicator or Not Used " 3 "Not Available or Take No Action";
VAL_ 2561015550 AuxI_O88_3911 0 "Auxiliary channel off" 1 "Auxiliary channel on" 2 "Error Indicator or Not Used " 3 "Not Available or Take No Action";
VAL_ 2561015550 AuxI_O81_3904 0 "Auxiliary channel off" 1 "Auxiliary channel on" 2 "Error Indicator or Not Used " 3 "Not Available or Take No Action";
VAL_ 2561015550 AuxI_O82_3905 0 "Auxiliary channel off" 1 "Auxiliary channel on" 2 "Error Indicator or Not Used " 3 "Not Available or Take No Action";
VAL_ 2561015550 AuxI_O83_3906 0 "Auxiliary channel off" 1 "Auxiliary channel on" 2 "Error Indicator or Not Used " 3 "Not Available or Take No Action";
VAL_ 2561015550 AuxI_O84_3907 0 "Auxiliary channel off" 1 "Auxiliary channel on" 2 "Error Indicator or Not Used " 3 "Not Available or Take No Action";
VAL_ 2566746622 TrailerBrakeStrokeAxle5Right 0 "OK" 1 "Non-functioning" 2 "Overstroke" 3 "Dragging brake" 4 "Reserved" 5 "Reserved" 6 "Sensor error" 7 "Not available";
VAL_ 2566746622 TrailerBrakeStrokeAxle5Left 0 "OK" 1 "Non-functioning" 2 "Overstroke" 3 "Dragging brake" 4 "Reserved" 5 "Reserved" 6 "Sensor error" 7 "Not available";
VAL_ 2566746622 TrailerBrakeStrokeAxle4Right 0 "OK" 1 "Non-functioning" 2 "Overstroke" 3 "Dragging brake" 4 "Reserved" 5 "Reserved" 6 "Sensor error" 7 "Not available";
VAL_ 2566746622 TrailerBrakeStrokeAxle4Left 0 "OK" 1 "Non-functioning" 2 "Overstroke" 3 "Dragging brake" 4 "Reserved" 5 "Reserved" 6 "Sensor error" 7 "Not available";
VAL_ 2566746622 TrailerBrakeStrokeAxle3Right 0 "OK" 1 "Non-functioning" 2 "Overstroke" 3 "Dragging brake" 4 "Reserved" 5 "Reserved" 6 "Sensor error" 7 "Not available";
VAL_ 2566746622 TrailerBrakeStrokeAxle3Left 0 "OK" 1 "Non-functioning" 2 "Overstroke" 3 "Dragging brake" 4 "Reserved" 5 "Reserved" 6 "Sensor error" 7 "Not available";
VAL_ 2566746622 TrailerBrakeStrokeAxle2Right 0 "OK" 1 "Non-functioning" 2 "Overstroke" 3 "Dragging brake" 4 "Reserved" 5 "Reserved" 6 "Sensor error" 7 "Not available";
VAL_ 2566746622 TrailerBrakeStrokeAxle2Left 0 "OK" 1 "Non-functioning" 2 "Overstroke" 3 "Dragging brake" 4 "Reserved" 5 "Reserved" 6 "Sensor error" 7 "Not available";
VAL_ 2566746622 TrailerBrakeStrokeAxle1Right 0 "OK" 1 "Non-functioning" 2 "Overstroke" 3 "Dragging brake" 4 "Reserved" 5 "Reserved" 6 "Sensor error" 7 "Not available";
VAL_ 2566746622 TrailerBrakeStrokeAxle1Left 0 "OK" 1 "Non-functioning" 2 "Overstroke" 3 "Dragging brake" 4 "Reserved" 5 "Reserved" 6 "Sensor error" 7 "Not available";
VAL_ 2566746622 TractorBrakeStrokeAxle5Right 0 "OK" 1 "Non-functioning" 2 "Overstroke" 3 "Dragging brake" 4 "Reserved" 5 "Reserved" 6 "Sensor error" 7 "Not available";
VAL_ 2566746622 TractorBrakeStrokeAxle5Left 0 "OK" 1 "Non-functioning" 2 "Overstroke" 3 "Dragging brake" 4 "Reserved" 5 "Reserved" 6 "Sensor error" 7 "Not available";
VAL_ 2566746622 TractorBrakeStrokeAxle4Right 0 "OK" 1 "Non-functioning" 2 "Overstroke" 3 "Dragging brake" 4 "Reserved" 5 "Reserved" 6 "Sensor error" 7 "Not available";
VAL_ 2566746622 TractorBrakeStrokeAxle4Left 0 "OK" 1 "Non-functioning" 2 "Overstroke" 3 "Dragging brake" 4 "Reserved" 5 "Reserved" 6 "Sensor error" 7 "Not available";
VAL_ 2566746622 TractorBrakeStrokeAxle3Right 0 "OK" 1 "Non-functioning" 2 "Overstroke" 3 "Dragging brake" 4 "Reserved" 5 "Reserved" 6 "Sensor error" 7 "Not available";
VAL_ 2566746622 TractorBrakeStrokeAxle3Left 0 "OK" 1 "Non-functioning" 2 "Overstroke" 3 "Dragging brake" 4 "Reserved" 5 "Reserved" 6 "Sensor error" 7 "Not available";
VAL_ 2566746622 TractorBrakeStrokeAxle2Right 0 "OK" 1 "Non-functioning" 2 "Overstroke" 3 "Dragging brake" 4 "Reserved" 5 "Reserved" 6 "Sensor error" 7 "Not available";
VAL_ 2566746622 TractorBrakeStrokeAxle2Left 0 "OK" 1 "Non-functioning" 2 "Overstroke" 3 "Dragging brake" 4 "Reserved" 5 "Reserved" 6 "Sensor error" 7 "Not available";
VAL_ 2566746622 TractorBrakeStrokeAxle1Right 0 "OK" 1 "Non-functioning" 2 "Overstroke" 3 "Dragging brake" 4 "Reserved" 5 "Reserved" 6 "Sensor error" 7 "Not available";
VAL_ 2566746622 TractorBrakeStrokeAxle1Left 0 "OK" 1 "Non-functioning" 2 "Overstroke " 3 "Dragging brake" 4 "Reserved" 5 "Reserved" 6 "Sensor error" 7 "Not available";
VAL_ 2566827774 AirCompressorStatus 0 "Compressor not active" 1 "Compressor active" 2 "Error indicator" 3 "Not available";
VAL_ 2566803966 RequestedACCDistanceMode 0 "Requested ACC Distance Mode #1" 1 "Requested ACC Distance Mode #2" 2 "Requested ACC Distance Mode #3" 3 "Requested ACC Distance Mode #4" 4 "Requested ACC Distance Mode #5" 5 "not defined" 6 "error condition" 7 "not available";
VAL_ 2566803966 ACCUsageDemand 0 "driver demand for not using ACC distance keeping control" 1 "driver demand for using ACC distance keeping control" 2 "reserved" 3 "don't care";
VAL_ 2432593918 ForwardCollisionWarning 0 "No warning" 1 "Collision is imminent" 2 "Error indicator" 3 "not available";
VAL_ 2432593918 ACCDistanceAlertSignal 0 "ACC DAS Not Active" 1 "ACC DAS Active" 2 "Reserved" 3 "Take no action";
VAL_ 2432593918 ACCSystemShutoffWarning 0 "ACC SSOW Not Active" 1 "ACC SSOW Active" 2 "Reserved" 3 "Take no action";
VAL_ 2432593918 ACCTargetDetected 0 "No targets detected" 1 "Target detected" 2 "Reserved" 3 "Take no action";
VAL_ 2432593918 AdptiveCruiseCtrlSetDistanceMode 0 "ACC Distance mode #1" 1 "ACC Distance mode #2" 2 "ACC Distance mode #3" 3 "ACC Distance mode #4" 4 "ACC Distance mode #5" 5 "Conventional cruise control mode" 6 "Error condition" 7 "Not available/not valid";
VAL_ 2432593918 AdaptiveCruiseCtrlMode 0 "Off" 1 "Speed control active" 2 "Distance control active" 3 "Overtake mode" 4 "Hold mode" 5 "Finish mode" 6 "Disabled or error condition" 7 "Not available/not valid";
VAL_ 2565406462 ControlByte_2541 0 "Positive Acknowledgment" 1 "Negative Acknowledgment" 2 "Access Denied" 3 "Cannot Respond";
VAL_ 2566803198 Status2OfDoors 0 "all bus doors are disabled" 1 "at least 1 bus door enabled " 2 "error" 3 "not available";
VAL_ 2566803198 Ramp_WheelChairLiftPos 0 "Inside bus" 1 "Outside bus" 2 "Error" 3 "Not available";
VAL_ 2566803198 PosOfDoors 0 "At least 1 door is open" 1 "Closing last door" 2 "All doors closed" 14 "Error" 15 "Not available";
VAL_ 2565870334 FifthWheelRollWarnIndcr_3317 0 "Limit not exceeded" 1 "Limit exceeded" 2 "error" 3 "Not Available";
VAL_ 2566762238 FifthWheelSliderLockIndicator 0 "Not Locked" 1 "Locked" 2 "Error" 3 "Not Available";
VAL_ 2566762238 FfthWhlLockCoupleStatusIndicator 0 "Incomplete or bad couple" 1 "Successful couple detected" 2 "Error" 3 "Not Available";
VAL_ 2566762238 FfthWhlLckReadyToCoupleIndicator 0 "Lock not open" 1 "Lock open" 2 "Error" 3 "Not Available";
VAL_ 2566762238 FifthWheelErrorStatus 0 "0" 1 "1" 2 "2" 3 "3" 4 "4" 5 "5" 6 "6" 7 "7" 8 "8" 9 "9" 10 "10" 11 "11" 12 "12" 13 "13" 14 "14" 15 "15";
VAL_ 2364543998 PitchAndRollCompensated_3326 0 "Compensation Off" 1 "Compensation On" 2 "Error" 3 "Not Available";
VAL_ 2364543998 PitchRateFigureOfMerit_3325 0 "Pitch rate fully functional" 1 "Pitch rate degraded" 2 "Error" 3 "Not available";
VAL_ 2364543998 RollAngleFigureOfMerit_3324 0 "Roll angle fully functional" 1 "Roll angle degraded" 2 "Error" 3 "Not available";
VAL_ 2364543998 PitchAngleFigureOfMerit_3323 0 "Pitch angle fully functional" 1 "Pitch angle degraded" 2 "Error" 3 "Not available";
VAL_ 2566846718 TransOilLevel1MeasurementStatus 0 "Conditions valid for transmission oil level measurement" 1 "Conditions not valid, Settling timer still counting down" 2 "Conditions not valid, Transmission in gear" 3 "Conditions not valid, Transmission fluid temperature too low" 4 "Conditions not valid, Transmission fluid temperature too high" 5 "Conditions not valid, Vehicle moving" 6 "Conditions not valid, Vehicle not level" 7 "Conditions not valid, Engine speed too low" 8 "Conditions not valid, Engine speed too high" 9 "Conditions not valid, No request for reading" 10 "Not defined" 11 "Not defined" 12 "Not defined" 13 "Conditions not valid, Other" 14 "Error" 15 "Not available";
VAL_ 2566846718 TransOilLevel1CountdownTimer 0 "less than 1 minute" 1 "One minute" 2 "Two minutes" 3 "Three minutes" 4 "Four minutes" 5 "Five minutes" 6 "Six minutes" 7 "Seven minutes" 8 "Eight minutes" 9 "Nine minutes" 10 "Ten minutes" 11 "Eleven minutes" 12 "Twelve minutes" 13 "Thirteen minutes" 14 "Error" 15 "Not Available";
VAL_ 2566760702 WrelessCommunicationNetworkType2 0 "Cellular network #1" 1 "Cellular network #2" 2 "Wireless LAN #1" 3 "Wireless LAN #2" 4 "Satellite network" 254 "Error" 255 "Not Available";
VAL_ 2566760702 NetworkAntennaStatus2 0 "Off" 1 "On" 254 "Error" 255 "Not Available";
VAL_ 2566760702 NetworkServiceStatus2 0 "Local Service" 1 "Roaming Service" 2 "Service not available" 3 "Not Authorized to Operate on Service" 254 "Error" 255 "Not Available";
VAL_ 2566760702 NetworkTransceiverStatus2 0 "Off" 1 "On" 2 "Not Authorized to Operate on Network" 254 "Error" 255 "Not Available";
VAL_ 2566760958 WrelessCommunicationNetworkType1 0 "Cellular network #1" 1 "Cellular network #2" 2 "Wireless LAN #1" 3 "Wireless LAN #2" 4 "Satellite network" 254 "Error" 255 "Not Available";
VAL_ 2566760958 NetworkAntennaStatus1 0 "Off" 1 "On" 254 "Error" 255 "Not Available";
VAL_ 2566760958 NetworkServiceStatus1 0 "Local Service" 1 "Roaming Service" 2 "Service not available" 3 "Not Authorized to Operate on Service" 254 "Error" 255 "Not Available";
VAL_ 2566760958 NetworkTransceiverStatus1 0 "Off" 1 "On" 2 "Not Authorized to Operate on Network" 254 "Error" 255 "Not Available";
VAL_ 2633869310 VoltageRegulatorEnabled 0 "Not regulating voltage" 1 "Regulating voltage" 2 "Reserved" 3 "Not available";
VAL_ 2633869310 VoltageRegulatorSoftStartState 0 "Soft start is inactive" 1 "Soft start is active" 2 "Reserved" 3 "Not available";
VAL_ 2633869310 VltgRgltrUndrfrqncyCmpnstnEnbld 0 "Underfrequency compensation disabled" 1 "Underfrequency compensation enabled" 2 "Reserved" 3 "Not available";
VAL_ 2633869310 VltgRgltrVAr_PwrFctrOprtingMode 0 "VAr/Power Factor regulation disabled" 1 "Power factor regulation enabled" 2 "VAr regulation enabled" 3 "Reserved" 4 "Reserved" 5 "Reserved" 6 "Reserved" 7 "Not available";
VAL_ 2633869310 VltgRglatorLoadCompensationMode 0 "load compensation disabled" 1 "Voltage droop compensation enabled" 2 "IR line drop compensation enabled" 3 "Reserved" 4 "Reserved" 5 "Reserved" 6 "Reserved" 7 "Not available";
